// *************************************************************************** *
// *                                                                           *
// * Description:         CANDB File                                           *
// * Generated at:        2023-04-23 21:52                                     *
// * System:              SDB22400                                             *
// * Variant:             KX11_A2_ADCU2_VCU2_PCM                               *
// * Network:             ChassisCAN1                                          *
// *                                                                           *
// *************************************************************************** *
VERSION "ChassisCAN1"

NS_ :

BS_ :

BU_ :  ASDM BBM ECM ETC PSCM1 SAS TCM VDDM

BO_ 147 AsdmChas1Fr01 : 8 ASDM
 SG_ AsyADL3FuncCtrlSts_UB : 32|1@0+ (1,0) [0|1] "" Vector__XXX
 SG_ AsyADL3FuncCtrlStsADMod : 27|2@0+ (1,0) [0|3] "" Vector__XXX
 SG_ AsyADL3FuncCtrlStsChks : 23|8@0+ (1.0,0.0) [0.0|255.0] "Unitless" Vector__XXX
 SG_ AsyADL3FuncCtrlStsCntr : 31|4@0+ (1.0,0.0) [0.0|15.0] "Unitless" Vector__XXX
 SG_ AsyADL3FuncCtrlStsCtrlSts : 33|1@0+ (1,0) [0|1] "" Vector__XXX
 SG_ AsyADL3FuncCtrlStsDegraded : 39|4@0+ (1.0,0.0) [0.0|15.0] "Unitless" Vector__XXX
 SG_ AsyADL3FuncCtrlStsQf : 25|2@0+ (1,0) [0|3] "" Vector__XXX
 SG_ AsyADL3FuncCtrlStsSts : 35|2@0+ (1,0) [0|3] "" Vector__XXX
 SG_ AsyADModeReq_UB : 48|1@0+ (1,0) [0|1] "" BBM
 SG_ AsyADModeReqADActiveReq : 51|2@0+ (1,0) [0|3] "" BBM
 SG_ AsyADModeReqADDeactiveReq : 49|1@0+ (1,0) [0|1] "" BBM
 SG_ AsyADModeReqChks : 47|8@0+ (1.0,0.0) [0.0|255.0] "Unitless" BBM
 SG_ AsyADModeReqCntr : 55|4@0+ (1.0,0.0) [0.0|15.0] "Unitless" BBM
 SG_ PASFuncActive : 15|1@0+ (1,0) [0|1] "" ECM
 SG_ PASFuncActive_UB : 14|1@0+ (1,0) [0|1] "" ECM
 SG_ RctaBrkReqQM : 13|1@0+ (1,0) [0|1] "" ECM
 SG_ RctaBrkReqQM_UB : 12|1@0+ (1,0) [0|1] "" ECM
 SG_ RcwmBrkReqQM : 11|1@0+ (1,0) [0|1] "" Vector__XXX
 SG_ RcwmBrkReqQM_UB : 10|1@0+ (1,0) [0|1] "" Vector__XXX

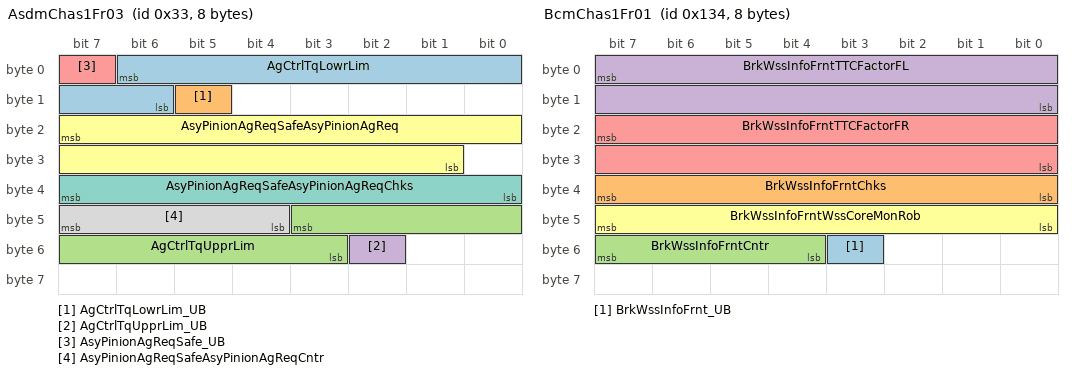
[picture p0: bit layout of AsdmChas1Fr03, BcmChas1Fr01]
BO_ 51 AsdmChas1Fr03 : 8 ASDM
 SG_ AgCtrlTqLowrLim : 6|9@0+ (0.125,-30.0) [-30.0|30.0] "Nm" PSCM1
 SG_ AgCtrlTqLowrLim_UB : 13|1@0+ (1,0) [0|1] "" PSCM1
 SG_ AgCtrlTqUpprLim : 43|9@0+ (0.125,-30.0) [-30.0|30.0] "Nm" PSCM1
 SG_ AgCtrlTqUpprLim_UB : 50|1@0+ (1,0) [0|1] "" PSCM1
 SG_ AsyPinionAgReqSafe_UB : 7|1@0+ (1,0) [0|1] "" PSCM1
 SG_ AsyPinionAgReqSafeAsyPinionAgReq : 23|15@0+ (0.0009765625,-14.5) [-14.5|17.4990234375] "rad" PSCM1
 SG_ AsyPinionAgReqSafeAsyPinionAgReqChks : 39|8@0+ (1.0,0.0) [0.0|255.0] "Unitless" PSCM1
 SG_ AsyPinionAgReqSafeAsyPinionAgReqCntr : 47|4@0+ (1.0,0.0) [0.0|15.0] "Unitless" PSCM1

BO_ 1321 AsdmChas1NMFr : 8 ASDM
 SG_ PNC16_ASDM : 16|1@0+ (1,0) [0|0] "" VDDM
 SG_ PNC17_ASDM : 17|1@0+ (1,0) [0|0] "" VDDM
 SG_ PNC18_ASDM : 18|1@0+ (1,0) [0|0] "" VDDM
 SG_ PNC19_ASDM : 19|1@0+ (1,0) [0|0] "" VDDM
 SG_ PNC20_ASDM : 20|1@0+ (1,0) [0|0] "" VDDM
 SG_ PNC21_ASDM : 21|1@0+ (1,0) [0|0] "" VDDM
 SG_ PNC22_ASDM : 22|1@0+ (1,0) [0|0] "" VDDM
 SG_ PNC23_ASDM : 23|1@0+ (1,0) [0|0] "" VDDM
 SG_ PNC24_ASDM : 24|1@0+ (1,0) [0|0] "" VDDM
 SG_ PNC25_ASDM : 25|1@0+ (1,0) [0|0] "" VDDM
 SG_ PNC26_ASDM : 26|1@0+ (1,0) [0|0] "" VDDM
 SG_ PNC27_ASDM : 27|1@0+ (1,0) [0|0] "" VDDM
 SG_ PNC28_ASDM : 28|1@0+ (1,0) [0|0] "" VDDM
 SG_ PNC29_ASDM : 29|1@0+ (1,0) [0|0] "" VDDM
 SG_ PNC30_ASDM : 30|1@0+ (1,0) [0|0] "" VDDM
 SG_ PNC31_ASDM : 31|1@0+ (1,0) [0|0] "" VDDM
 SG_ PNC32_ASDM : 32|1@0+ (1,0) [0|0] "" VDDM
 SG_ PNC33_ASDM : 33|1@0+ (1,0) [0|0] "" VDDM
 SG_ PNC34_ASDM : 34|1@0+ (1,0) [0|0] "" VDDM
 SG_ PNC35_ASDM : 35|1@0+ (1,0) [0|0] "" VDDM
 SG_ PNC36_ASDM : 36|1@0+ (1,0) [0|0] "" VDDM
 SG_ PNC37_ASDM : 37|1@0+ (1,0) [0|0] "" VDDM
 SG_ PNC38_ASDM : 38|1@0+ (1,0) [0|0] "" VDDM
 SG_ PNC39_ASDM : 39|1@0+ (1,0) [0|0] "" VDDM
 SG_ PNC40_ASDM : 40|1@0+ (1,0) [0|0] "" VDDM
 SG_ PNC41_ASDM : 41|1@0+ (1,0) [0|0] "" VDDM
 SG_ PNC42_ASDM : 42|1@0+ (1,0) [0|0] "" VDDM
 SG_ NM_PNI_ASDM : 14|1@0+ (1,0) [0|0] "" VDDM
 SG_ NM_AW_ASDM : 12|1@0+ (1,0) [0|0] "" VDDM
 SG_ NM_CS_ASDM : 11|1@0+ (1,0) [0|0] "" VDDM
 SG_ NM_RMR_ASDM : 8|1@0+ (1,0) [0|0] "" VDDM
 SG_ NM_NodeID_ASDM : 7|8@0+ (1,0) [0|0] "" VDDM

BO_ 308 BcmChas1Fr01 : 8 BBM
 SG_ BrkWssInfoFrnt_UB : 51|1@0+ (1,0) [0|1] "" Vector__XXX
 SG_ BrkWssInfoFrntChks : 39|8@0+ (1.0,0.0) [0.0|255.0] "Unitless" Vector__XXX
 SG_ BrkWssInfoFrntCntr : 55|4@0+ (1.0,0.0) [0.0|15.0] "Unitless" Vector__XXX
 SG_ BrkWssInfoFrntTTCFactorFL : 7|16@0+ (0.00000916,0.7) [0.7|1.3003006] "Unitless" Vector__XXX
 SG_ BrkWssInfoFrntTTCFactorFR : 23|16@0+ (0.00000916,0.7) [0.7|1.3003006] "Unitless" Vector__XXX
 SG_ BrkWssInfoFrntWssCoreMonRob : 47|8@0+ (1.0,0.0) [0.0|255.0] "Unitless" Vector__XXX

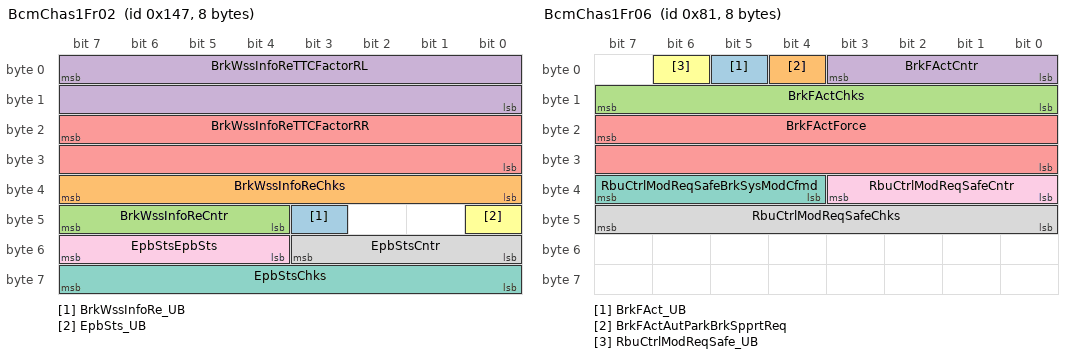
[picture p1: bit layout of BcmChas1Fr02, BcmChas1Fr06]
BO_ 327 BcmChas1Fr02 : 8 BBM
 SG_ BrkWssInfoRe_UB : 43|1@0+ (1,0) [0|1] "" Vector__XXX
 SG_ BrkWssInfoReChks : 39|8@0+ (1.0,0.0) [0.0|255.0] "Unitless" Vector__XXX
 SG_ BrkWssInfoReCntr : 47|4@0+ (1.0,0.0) [0.0|15.0] "Unitless" Vector__XXX
 SG_ BrkWssInfoReTTCFactorRL : 7|16@0+ (0.00000916,0.7) [0.7|1.3003006] "Unitless" Vector__XXX
 SG_ BrkWssInfoReTTCFactorRR : 23|16@0+ (0.00000916,0.7) [0.7|1.3003006] "Unitless" Vector__XXX
 SG_ EpbSts_UB : 40|1@0+ (1,0) [0|1] "" Vector__XXX
 SG_ EpbStsChks : 63|8@0+ (1.0,0.0) [0.0|255.0] "Unitless" Vector__XXX
 SG_ EpbStsCntr : 51|4@0+ (1.0,0.0) [0.0|15.0] "Unitless" Vector__XXX
 SG_ EpbStsEpbSts : 55|4@0+ (1,0) [0|15] "" Vector__XXX

BO_ 84 BcmChas1Fr03 : 8 BBM
 SG_ SBMHealthChkCmd : 63|8@0+ (1.0,0.0) [0.0|255.0] "Unitless" Vector__XXX
 SG_ SBMHealthChkCmd_UB : 27|1@0+ (1,0) [0|1] "" Vector__XXX

BO_ 129 BcmChas1Fr06 : 8 BBM
 SG_ BrkFAct_UB : 5|1@0+ (1,0) [0|1] "" Vector__XXX
 SG_ BrkFActAutParkBrkSpprtReq : 4|1@0+ (1,0) [0|1] "" Vector__XXX
 SG_ BrkFActChks : 15|8@0+ (1.0,0.0) [0.0|255.0] "Unitless" Vector__XXX
 SG_ BrkFActCntr : 3|4@0+ (1.0,0.0) [0.0|15.0] "Unitless" Vector__XXX
 SG_ BrkFActForce : 23|16@0+ (1.0,0.0) [0.0|50000.0] "N" Vector__XXX
 SG_ RbuCtrlModReqSafe_UB : 6|1@0+ (1,0) [0|1] "" Vector__XXX
 SG_ RbuCtrlModReqSafeBrkSysModCfmd : 39|4@0+ (1,0) [0|15] "" Vector__XXX
 SG_ RbuCtrlModReqSafeChks : 47|8@0+ (1.0,0.0) [0.0|255.0] "Unitless" Vector__XXX
 SG_ RbuCtrlModReqSafeCntr : 35|4@0+ (1.0,0.0) [0.0|15.0] "Unitless" Vector__XXX

BO_ 265 BcmChas1Fr07 : 8 BBM
 SG_ EpbAvlPrim_UB : 57|1@0+ (1,0) [0|1] "" Vector__XXX
 SG_ EpbAvlPrimApplyFunctionalitiesAvailable : 27|1@0+ (1,0) [0|1] "" Vector__XXX
 SG_ EpbAvlPrimChks : 23|8@0+ (1.0,0.0) [0.0|255.0] "Unitless" Vector__XXX
 SG_ EpbAvlPrimCntr : 31|4@0+ (1.0,0.0) [0.0|15.0] "Unitless" Vector__XXX
 SG_ EpbAvlPrimDriveAwayIntention : 26|1@0+ (1,0) [0|1] "" Vector__XXX
 SG_ EpbAvlPrimHostAvailabilityFull : 25|1@0+ (1,0) [0|1] "" Vector__XXX
 SG_ EpbAvlPrimHostAvailabilityRelOnly : 24|1@0+ (1,0) [0|1] "" Vector__XXX
 SG_ EpbAvlPrimPrimarySystemAvailable : 39|1@0+ (1,0) [0|1] "" Vector__XXX
 SG_ EpbAvlPrimReserved1 : 38|1@0+ (1,0) [0|1] "" Vector__XXX
 SG_ EpbAvlPrimReserved2 : 37|1@0+ (1,0) [0|1] "" Vector__XXX
 SG_ EpbAvlPrimReserved3 : 36|1@0+ (1,0) [0|1] "" Vector__XXX
 SG_ EpbAvlPrimReserved4 : 35|1@0+ (1,0) [0|1] "" Vector__XXX
 SG_ EpbAvlPrimRollerTestBench : 34|1@0+ (1,0) [0|1] "" Vector__XXX
 SG_ PrimBrkSysSt_UB : 56|1@0+ (1,0) [0|1] "" Vector__XXX
 SG_ PrimBrkSysStBrkSysSt : 7|4@0+ (1,0) [0|15] "" Vector__XXX
 SG_ PrimBrkSysStChks : 15|8@0+ (1.0,0.0) [0.0|255.0] "Unitless" Vector__XXX
 SG_ PrimBrkSysStCntr : 3|4@0+ (1.0,0.0) [0.0|15.0] "Unitless" Vector__XXX

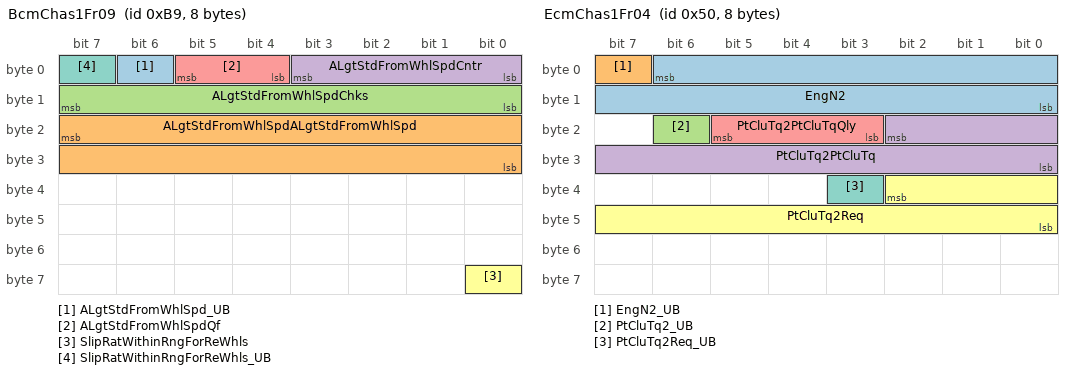
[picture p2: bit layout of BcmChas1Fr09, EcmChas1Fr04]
BO_ 185 BcmChas1Fr09 : 8 BBM
 SG_ ALgtStdFromWhlSpd_UB : 6|1@0+ (1,0) [0|1] "" Vector__XXX
 SG_ ALgtStdFromWhlSpdALgtStdFromWhlSpd : 23|16@0- (0.0009765625,0.0) [-18.0|18.0] "m/s^2" Vector__XXX
 SG_ ALgtStdFromWhlSpdChks : 15|8@0+ (1.0,0.0) [0.0|255.0] "Unitless" Vector__XXX
 SG_ ALgtStdFromWhlSpdCntr : 3|4@0+ (1.0,0.0) [0.0|15.0] "Unitless" Vector__XXX
 SG_ ALgtStdFromWhlSpdQf : 5|2@0+ (1,0) [0|3] "" Vector__XXX
 SG_ SlipRatWithinRngForReWhls : 56|1@0+ (1,0) [0|1] "" Vector__XXX
 SG_ SlipRatWithinRngForReWhls_UB : 7|1@0+ (1,0) [0|1] "" Vector__XXX

BO_ 1334 BcmChas1NMFr : 8 BBM
 SG_ PNC16_BBM : 16|1@0+ (1,0) [0|0] "" Vector__XXX
 SG_ PNC17_BBM : 17|1@0+ (1,0) [0|0] "" Vector__XXX
 SG_ PNC18_BBM : 18|1@0+ (1,0) [0|0] "" Vector__XXX
 SG_ PNC19_BBM : 19|1@0+ (1,0) [0|0] "" Vector__XXX
 SG_ PNC20_BBM : 20|1@0+ (1,0) [0|0] "" Vector__XXX
 SG_ PNC21_BBM : 21|1@0+ (1,0) [0|0] "" Vector__XXX
 SG_ PNC22_BBM : 22|1@0+ (1,0) [0|0] "" Vector__XXX
 SG_ PNC23_BBM : 23|1@0+ (1,0) [0|0] "" Vector__XXX
 SG_ PNC24_BBM : 24|1@0+ (1,0) [0|0] "" Vector__XXX
 SG_ PNC25_BBM : 25|1@0+ (1,0) [0|0] "" Vector__XXX
 SG_ PNC26_BBM : 26|1@0+ (1,0) [0|0] "" Vector__XXX
 SG_ PNC27_BBM : 27|1@0+ (1,0) [0|0] "" Vector__XXX
 SG_ PNC28_BBM : 28|1@0+ (1,0) [0|0] "" Vector__XXX
 SG_ PNC29_BBM : 29|1@0+ (1,0) [0|0] "" Vector__XXX
 SG_ PNC30_BBM : 30|1@0+ (1,0) [0|0] "" Vector__XXX
 SG_ PNC31_BBM : 31|1@0+ (1,0) [0|0] "" Vector__XXX
 SG_ PNC32_BBM : 32|1@0+ (1,0) [0|0] "" Vector__XXX
 SG_ PNC33_BBM : 33|1@0+ (1,0) [0|0] "" Vector__XXX
 SG_ PNC34_BBM : 34|1@0+ (1,0) [0|0] "" Vector__XXX
 SG_ PNC35_BBM : 35|1@0+ (1,0) [0|0] "" Vector__XXX
 SG_ PNC36_BBM : 36|1@0+ (1,0) [0|0] "" Vector__XXX
 SG_ PNC37_BBM : 37|1@0+ (1,0) [0|0] "" Vector__XXX
 SG_ PNC38_BBM : 38|1@0+ (1,0) [0|0] "" Vector__XXX
 SG_ PNC39_BBM : 39|1@0+ (1,0) [0|0] "" Vector__XXX
 SG_ PNC40_BBM : 40|1@0+ (1,0) [0|0] "" Vector__XXX
 SG_ PNC41_BBM : 41|1@0+ (1,0) [0|0] "" Vector__XXX
 SG_ PNC42_BBM : 42|1@0+ (1,0) [0|0] "" Vector__XXX
 SG_ NM_PNI_BBM : 14|1@0+ (1,0) [0|0] "" Vector__XXX
 SG_ NM_AW_BBM : 12|1@0+ (1,0) [0|0] "" Vector__XXX
 SG_ NM_CS_BBM : 11|1@0+ (1,0) [0|0] "" Vector__XXX
 SG_ NM_RMR_BBM : 8|1@0+ (1,0) [0|0] "" Vector__XXX
 SG_ NM_NodeID_BBM : 7|8@0+ (1,0) [0|0] "" Vector__XXX

BO_ 134 EcmChas1BsgFr40 : 8 ECM
 SG_ DrvgCyc : 39|1@0+ (1,0) [0|1] "" Vector__XXX
 SG_ DrvgCyc_UB : 38|1@0+ (1,0) [0|1] "" Vector__XXX

BO_ 544 EcmChas1BsgFr41 : 8 ECM
 SG_ AccrPedlRat_UB : 7|1@0+ (1,0) [0|1] "" Vector__XXX
 SG_ AccrPedlRatAccrPedlRat : 6|15@0+ (0.00390625,0.0) [0.0|100.0] "%" Vector__XXX
 SG_ AccrPedlRatChks : 23|8@0+ (1.0,0.0) [0.0|255.0] "Unitless" Vector__XXX
 SG_ AccrPedlRatCntr : 31|4@0+ (1.0,0.0) [0.0|15.0] "Unitless" Vector__XXX

BO_ 80 EcmChas1Fr04 : 8 ECM
 SG_ EngN2 : 6|15@0+ (0.5,0.0) [0.0|16383.5] "rpm" TCM,VDDM
 SG_ EngN2_UB : 7|1@0+ (1,0) [0|1] "" TCM,VDDM
 SG_ PtCluTq2_UB : 22|1@0+ (1,0) [0|1] "" TCM
 SG_ PtCluTq2PtCluTq : 18|11@0+ (1.0,-1024.0) [-1024.0|1023.0] "NewtonMeter" TCM
 SG_ PtCluTq2PtCluTqQly : 21|3@0+ (1,0) [0|7] "" TCM
 SG_ PtCluTq2Req : 34|11@0+ (1.0,-1024.0) [-1024.0|1023.0] "NewtonMeter" TCM
 SG_ PtCluTq2Req_UB : 35|1@0+ (1,0) [0|1] "" TCM

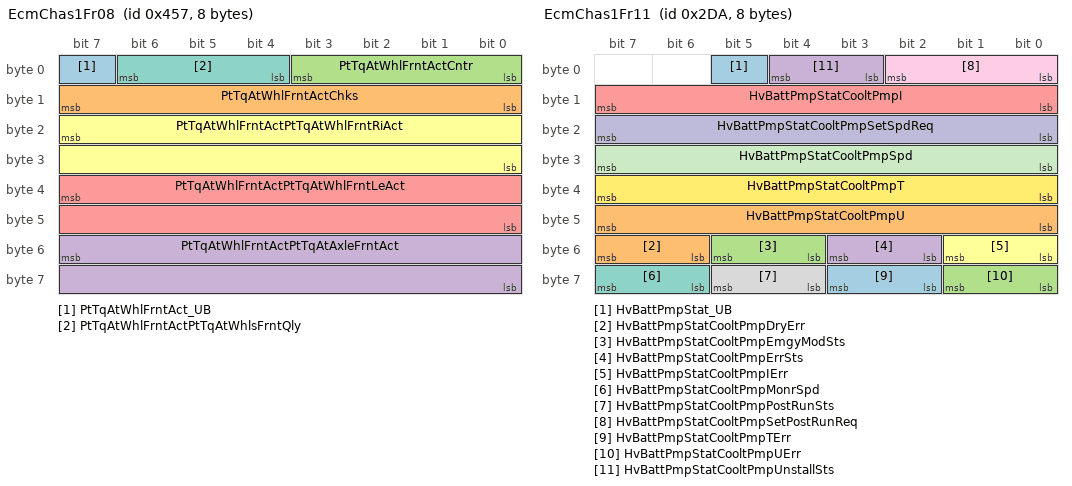
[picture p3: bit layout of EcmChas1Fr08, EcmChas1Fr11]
BO_ 1111 EcmChas1Fr08 : 8 ECM
 SG_ PtTqAtWhlFrntAct_UB : 7|1@0+ (1,0) [0|1] "" PSCM1
 SG_ PtTqAtWhlFrntActChks : 15|8@0+ (1.0,0.0) [0.0|255.0] "Unitless" PSCM1
 SG_ PtTqAtWhlFrntActCntr : 3|4@0+ (1.0,0.0) [0.0|15.0] "Unitless" PSCM1
 SG_ PtTqAtWhlFrntActPtTqAtAxleFrntAct : 55|16@0- (1.0,0.0) [-20000.0|20000.0] "NewtonMeter" PSCM1
 SG_ PtTqAtWhlFrntActPtTqAtWhlFrntLeAct : 39|16@0- (1.0,0.0) [-20000.0|20000.0] "NewtonMeter" PSCM1
 SG_ PtTqAtWhlFrntActPtTqAtWhlFrntRiAct : 23|16@0- (1.0,0.0) [-20000.0|20000.0] "NewtonMeter" PSCM1
 SG_ PtTqAtWhlFrntActPtTqAtWhlsFrntQly : 6|3@0+ (1,0) [0|7] "" PSCM1

BO_ 708 EcmChas1Fr09 : 8 ECM
 SG_ PtVehSpdMax_UB : 4|1@0+ (1,0) [0|1] "" VDDM
 SG_ PtVehSpdMaxChks : 15|8@0+ (1.0,0.0) [0.0|255.0] "Unitless" VDDM
 SG_ PtVehSpdMaxCntr : 3|4@0+ (1.0,0.0) [0.0|15.0] "Unitless" VDDM
 SG_ PtVehSpdMaxReq : 23|8@0+ (0.4,0.0) [0.0|102.0] "m/s" VDDM

BO_ 730 EcmChas1Fr11 : 8 ECM
 SG_ HvBattPmpStat_UB : 5|1@0+ (1,0) [0|1] "" VDDM
 SG_ HvBattPmpStatCooltPmpDryErr : 55|2@0+ (1,0) [0|3] "" VDDM
 SG_ HvBattPmpStatCooltPmpEmgyModSts : 53|2@0+ (1,0) [0|3] "" VDDM
 SG_ HvBattPmpStatCooltPmpErrSts : 51|2@0+ (1,0) [0|3] "" VDDM
 SG_ HvBattPmpStatCooltPmpI : 15|8@0+ (0.2,0.0) [0.0|50.800000000000004] "A" VDDM
 SG_ HvBattPmpStatCooltPmpIErr : 49|2@0+ (1,0) [0|3] "" VDDM
 SG_ HvBattPmpStatCooltPmpMonrSpd : 63|2@0+ (1,0) [0|3] "" VDDM
 SG_ HvBattPmpStatCooltPmpPostRunSts : 61|2@0+ (1,0) [0|3] "" VDDM
 SG_ HvBattPmpStatCooltPmpSetPostRunReq : 2|3@0+ (1,0) [0|7] "" VDDM
 SG_ HvBattPmpStatCooltPmpSetSpdReq : 23|8@0+ (1.0,0.0) [0.0|254.0] "Unitless" VDDM
 SG_ HvBattPmpStatCooltPmpSpd : 31|8@0+ (1.0,0.0) [0.0|254.0] "Unitless" VDDM
 SG_ HvBattPmpStatCooltPmpT : 39|8@0+ (1.0,-50.0) [-50.0|200.0] "degC" VDDM
 SG_ HvBattPmpStatCooltPmpTErr : 59|2@0+ (1,0) [0|3] "" VDDM
 SG_ HvBattPmpStatCooltPmpU : 47|8@0+ (0.1,0.0) [0.0|25.0] "Volt" VDDM
 SG_ HvBattPmpStatCooltPmpUErr : 57|2@0+ (1,0) [0|3] "" VDDM
 SG_ HvBattPmpStatCooltPmpUnstallSts : 4|2@0+ (1,0) [0|3] "" VDDM

BO_ 859 EcmChas1Fr12 : 8 ECM
 SG_ DispElecPwr_UB : 51|1@0+ (1,0) [0|1] "" VDDM
 SG_ DispElecPwrAbs : 49|10@0+ (0.5,0.0) [0.0|511.0] "kW" VDDM
 SG_ DispElecPwrSts : 50|1@0+ (1,0) [0|1] "" VDDM

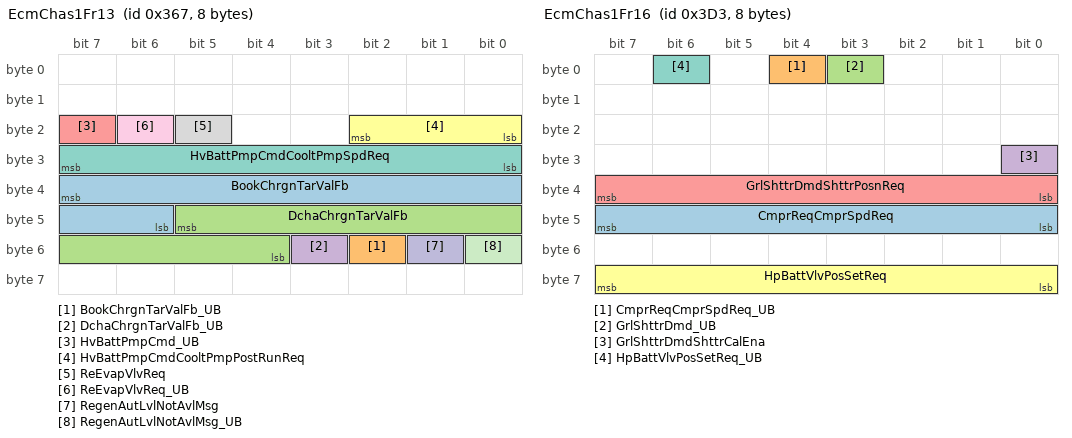
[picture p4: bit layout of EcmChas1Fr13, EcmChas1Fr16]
BO_ 871 EcmChas1Fr13 : 8 ECM
 SG_ BookChrgnTarValFb : 39|10@0+ (0.1,0.0) [0.0|100.0] "%" VDDM
 SG_ BookChrgnTarValFb_UB : 50|1@0+ (1,0) [0|1] "" VDDM
 SG_ DchaChrgnTarValFb : 45|10@0+ (0.1,0.0) [0.0|100.0] "%" VDDM
 SG_ DchaChrgnTarValFb_UB : 51|1@0+ (1,0) [0|1] "" VDDM
 SG_ HvBattPmpCmd_UB : 23|1@0+ (1,0) [0|1] "" Vector__XXX
 SG_ HvBattPmpCmdCooltPmpPostRunReq : 18|3@0+ (1,0) [0|7] "" Vector__XXX
 SG_ HvBattPmpCmdCooltPmpSpdReq : 31|8@0+ (1.0,0.0) [0.0|254.0] "Unitless" Vector__XXX
 SG_ ReEvapVlvReq : 21|1@0+ (1,0) [0|1] "" VDDM
 SG_ ReEvapVlvReq_UB : 22|1@0+ (1,0) [0|1] "" VDDM
 SG_ RegenAutLvlNotAvlMsg : 49|1@0+ (1,0) [0|1] "" VDDM
 SG_ RegenAutLvlNotAvlMsg_UB : 48|1@0+ (1,0) [0|1] "" VDDM

BO_ 979 EcmChas1Fr16 : 8 ECM
 SG_ CmprReqCmprSpdReq : 47|8@0+ (50.0,0.0) [0.0|12700.0] "rpm" VDDM
 SG_ CmprReqCmprSpdReq_UB : 4|1@0+ (1,0) [0|1] "" VDDM
 SG_ GrlShttrDmd_UB : 3|1@0+ (1,0) [0|1] "" Vector__XXX
 SG_ GrlShttrDmdShttrCalEna : 24|1@0+ (1,0) [0|1] "" Vector__XXX
 SG_ GrlShttrDmdShttrPosnReq : 39|8@0+ (1.0,0.0) [0.0|255.0] "Unitless" Vector__XXX
 SG_ HpBattVlvPosSetReq : 63|8@0+ (1.0,0.0) [0.0|100.0] "%" Vector__XXX
 SG_ HpBattVlvPosSetReq_UB : 6|1@0+ (1,0) [0|1] "" Vector__XXX

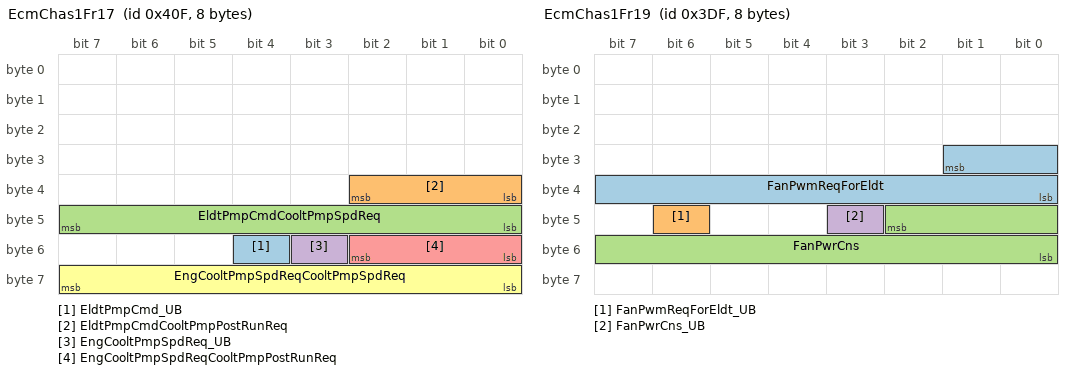
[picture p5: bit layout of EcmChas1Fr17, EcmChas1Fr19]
BO_ 1039 EcmChas1Fr17 : 8 ECM
 SG_ EldtPmpCmd_UB : 52|1@0+ (1,0) [0|1] "" Vector__XXX
 SG_ EldtPmpCmdCooltPmpPostRunReq : 34|3@0+ (1,0) [0|7] "" Vector__XXX
 SG_ EldtPmpCmdCooltPmpSpdReq : 47|8@0+ (1.0,0.0) [0.0|254.0] "Unitless" Vector__XXX
 SG_ EngCooltPmpSpdReq_UB : 51|1@0+ (1,0) [0|1] "" Vector__XXX
 SG_ EngCooltPmpSpdReqCooltPmpPostRunReq : 50|3@0+ (1,0) [0|7] "" Vector__XXX
 SG_ EngCooltPmpSpdReqCooltPmpSpdReq : 63|8@0+ (1.0,0.0) [0.0|254.0] "Unitless" Vector__XXX

BO_ 563 EcmChas1Fr18 : 8 ECM
 SG_ CmprRunTime : 7|32@0+ (1.0,0.0) [0.0|4294967295.0] "Unitless" VDDM
 SG_ CmprRunTime_UB : 38|1@0+ (1,0) [0|1] "" VDDM

BO_ 991 EcmChas1Fr19 : 8 ECM
 SG_ FanPwmReqForEldt : 25|10@0+ (0.1,0.0) [0.0|100.0] "%" VDDM
 SG_ FanPwmReqForEldt_UB : 46|1@0+ (1,0) [0|1] "" VDDM
 SG_ FanPwrCns : 42|11@0+ (1.0,0.0) [0.0|2047.0] "W" VDDM
 SG_ FanPwrCns_UB : 43|1@0+ (1,0) [0|1] "" VDDM

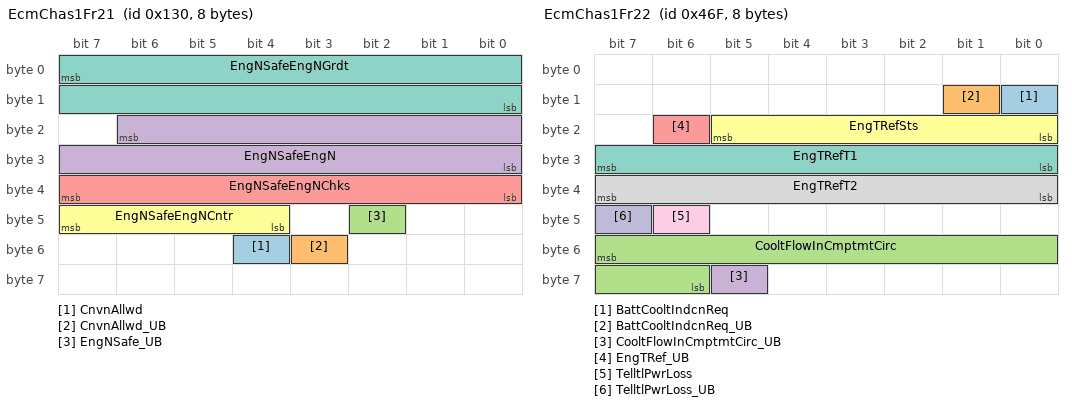
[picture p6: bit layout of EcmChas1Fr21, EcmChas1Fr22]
BO_ 304 EcmChas1Fr21 : 8 ECM
 SG_ CnvnAllwd : 52|1@0+ (1,0) [0|1] "" VDDM
 SG_ CnvnAllwd_UB : 51|1@0+ (1,0) [0|1] "" VDDM
 SG_ EngNSafe_UB : 42|1@0+ (1,0) [0|1] "" SAS
 SG_ EngNSafeEngN : 22|15@0+ (0.5,0.0) [0.0|16383.5] "rpm" SAS
 SG_ EngNSafeEngNChks : 39|8@0+ (1.0,0.0) [0.0|255.0] "Unitless" SAS
 SG_ EngNSafeEngNCntr : 47|4@0+ (1.0,0.0) [0.0|15.0] "Unitless" SAS
 SG_ EngNSafeEngNGrdt : 7|16@0- (1.0,0.0) [-30000.0|32767.0] "RpmPerSec" SAS

BO_ 1135 EcmChas1Fr22 : 8 ECM
 SG_ BattCooltIndcnReq : 8|1@0+ (1,0) [0|1] "" VDDM
 SG_ BattCooltIndcnReq_UB : 9|1@0+ (1,0) [0|1] "" VDDM
 SG_ CooltFlowInCmptmtCirc : 55|10@0+ (0.05,0.0) [0.0|51.150000000000006] "L / min" VDDM
 SG_ CooltFlowInCmptmtCirc_UB : 61|1@0+ (1,0) [0|1] "" VDDM
 SG_ EngTRef_UB : 22|1@0+ (1,0) [0|1] "" TCM
 SG_ EngTRefSts : 21|6@0+ (1.0,0.0) [0.0|63.0] "Unitless" TCM
 SG_ EngTRefT1 : 31|8@0+ (1.0,-50.0) [-50.0|200.0] "degC" TCM
 SG_ EngTRefT2 : 39|8@0+ (1.0,-50.0) [-50.0|200.0] "degC" TCM
 SG_ TelltlPwrLoss : 46|1@0+ (1,0) [0|1] "" VDDM
 SG_ TelltlPwrLoss_UB : 47|1@0+ (1,0) [0|1] "" VDDM

BO_ 576 EcmChas1Fr23 : 8 ECM
 SG_ HvBattPmpPwrCns : 3|12@0+ (1.0,0.0) [0.0|4095.0] "W" VDDM
 SG_ HvBattPmpPwrCns_UB : 7|1@0+ (1,0) [0|1] "" VDDM
 SG_ PostHeatgRunTiEstimd : 23|16@0+ (1.0,0.0) [0.0|65535.0] "Unitless" VDDM
 SG_ PostHeatgRunTiEstimd_UB : 6|1@0+ (1,0) [0|1] "" VDDM

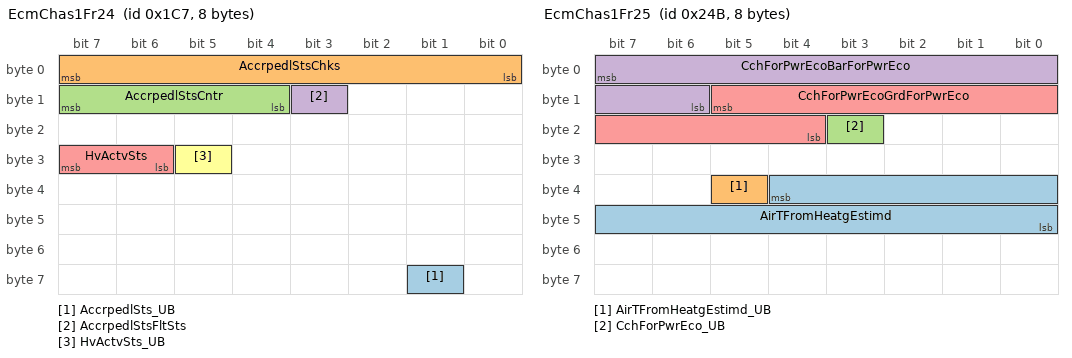
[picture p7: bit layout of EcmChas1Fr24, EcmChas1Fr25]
BO_ 455 EcmChas1Fr24 : 8 ECM
 SG_ AccrpedlSts_UB : 57|1@0+ (1,0) [0|1] "" VDDM
 SG_ AccrpedlStsChks : 7|8@0+ (1.0,0.0) [0.0|255.0] "Unitless" VDDM
 SG_ AccrpedlStsCntr : 15|4@0+ (1.0,0.0) [0.0|15.0] "Unitless" VDDM
 SG_ AccrpedlStsFltSts : 11|1@0+ (1,0) [0|1] "" VDDM
 SG_ HvActvSts : 31|2@0+ (1,0) [0|3] "" VDDM
 SG_ HvActvSts_UB : 29|1@0+ (1,0) [0|1] "" VDDM

BO_ 587 EcmChas1Fr25 : 8 ECM
 SG_ AirTFromHeatgEstimd : 36|13@0- (0.1,0.0) [-256.0|255.9] "degC" VDDM
 SG_ AirTFromHeatgEstimd_UB : 37|1@0+ (1,0) [0|1] "" VDDM
 SG_ CchForPwrEco_UB : 19|1@0+ (1,0) [0|1] "" VDDM
 SG_ CchForPwrEcoBarForPwrEco : 7|10@0+ (0.1,0.0) [0.0|102.30000000000001] "%" VDDM
 SG_ CchForPwrEcoGrdForPwrEco : 13|10@0+ (0.1,0.0) [0.0|102.30000000000001] "Unitless" VDDM

BO_ 543 EcmChas1Fr26 : 8 ECM
 SG_ AcCmprVlvICns : 39|8@0+ (0.05,0.0) [0.0|12.600000000000001] "A" VDDM
 SG_ AcCmprVlvICns_UB : 61|1@0+ (1,0) [0|1] "" VDDM
 SG_ GearMov : 23|2@0+ (1,0) [0|3] "" VDDM
 SG_ GearMov_UB : 21|1@0+ (1,0) [0|1] "" VDDM

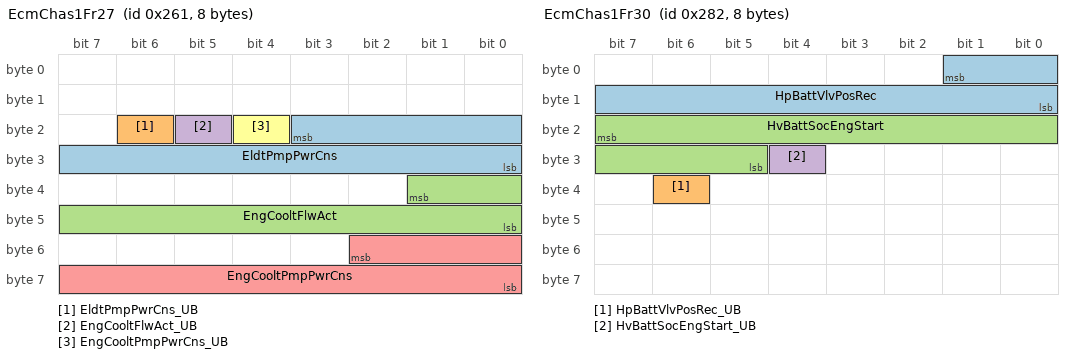
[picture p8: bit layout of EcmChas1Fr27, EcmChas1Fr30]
BO_ 609 EcmChas1Fr27 : 8 ECM
 SG_ EldtPmpPwrCns : 19|12@0+ (1.0,0.0) [0.0|4095.0] "W" VDDM
 SG_ EldtPmpPwrCns_UB : 22|1@0+ (1,0) [0|1] "" VDDM
 SG_ EngCooltFlwAct : 33|10@0+ (0.1,0.0) [0.0|102.30000000000001] "L / min" VDDM
 SG_ EngCooltFlwAct_UB : 21|1@0+ (1,0) [0|1] "" VDDM
 SG_ EngCooltPmpPwrCns : 50|11@0+ (1.0,0.0) [0.0|2047.0] "W" VDDM
 SG_ EngCooltPmpPwrCns_UB : 20|1@0+ (1,0) [0|1] "" VDDM

BO_ 632 EcmChas1Fr29 : 8 ECM
 SG_ ChrgnSpd : 38|11@0+ (1.0,0.0) [0.0|2047.0] "Km/h" VDDM
 SG_ ChrgnSpd_UB : 48|1@0+ (1,0) [0|1] "" VDDM

BO_ 642 EcmChas1Fr30 : 8 ECM
 SG_ HpBattVlvPosRec : 1|10@0+ (0.1,0.0) [0.0|100.0] "%" VDDM
 SG_ HpBattVlvPosRec_UB : 38|1@0+ (1,0) [0|1] "" VDDM
 SG_ HvBattSocEngStart : 23|11@0+ (0.05,0.0) [0.0|100.0] "%" VDDM
 SG_ HvBattSocEngStart_UB : 28|1@0+ (1,0) [0|1] "" VDDM

BO_ 131 EcmChas1Fr31 : 8 ECM
 SG_ EngSt1WdSts_UB : 23|1@0+ (1,0) [0|1] "" TCM,VDDM
 SG_ EngSt1WdStsChks : 7|8@0+ (1.0,0.0) [0.0|255.0] "Unitless" TCM,VDDM
 SG_ EngSt1WdStsCntr : 15|4@0+ (1.0,0.0) [0.0|15.0] "Unitless" TCM,VDDM
 SG_ EngSt1WdStsEngSt1WdSts : 11|4@0+ (1,0) [0|15] "" TCM,VDDM

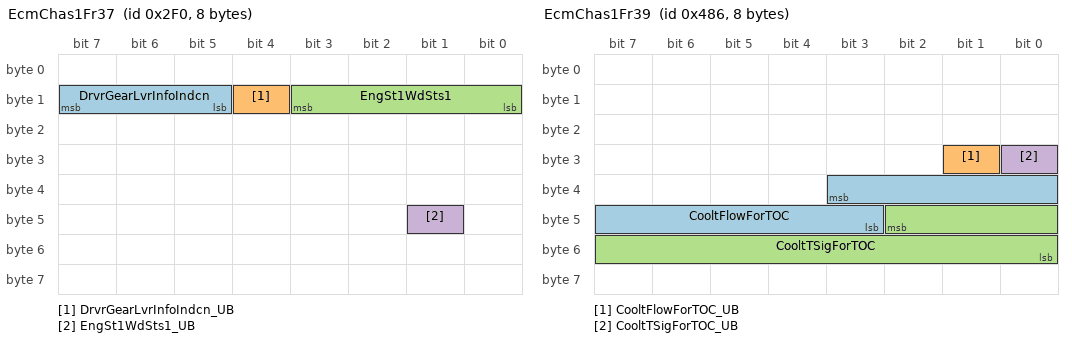
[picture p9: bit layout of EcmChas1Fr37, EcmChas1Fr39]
BO_ 752 EcmChas1Fr37 : 8 ECM
 SG_ DrvrGearLvrInfoIndcn : 15|3@0+ (1,0) [0|7] "" VDDM
 SG_ DrvrGearLvrInfoIndcn_UB : 12|1@0+ (1,0) [0|1] "" VDDM
 SG_ EngSt1WdSts1 : 11|4@0+ (1,0) [0|15] "" SAS
 SG_ EngSt1WdSts1_UB : 41|1@0+ (1,0) [0|1] "" SAS

BO_ 1157 EcmChas1Fr38 : 8 ECM
 SG_ AutoShowModPrpsnEna : 43|1@0+ (1,0) [0|1] "" VDDM
 SG_ AutoShowModPrpsnEna_UB : 42|1@0+ (1,0) [0|1] "" VDDM

BO_ 1158 EcmChas1Fr39 : 8 ECM
 SG_ CooltFlowForTOC : 35|9@0+ (0.1,0.0) [0.0|51.1] "L / min" TCM
 SG_ CooltFlowForTOC_UB : 25|1@0+ (1,0) [0|1] "" TCM
 SG_ CooltTSigForTOC : 42|11@0+ (0.1,-40.0) [-40.0|140.0] "degC" TCM
 SG_ CooltTSigForTOC_UB : 24|1@0+ (1,0) [0|1] "" TCM

BO_ 837 EcmChas1Fr42 : 8 ECM
 SG_ DstEstimdToEmptyForDrvgElecPredTyp2 : 46|10@0+ (1.0,0.0) [0.0|1023.0] "KiloMtr" VDDM
 SG_ DstEstimdToEmptyForDrvgElecPredTyp2_UB : 52|1@0+ (1,0) [0|1] "" VDDM

BO_ 913 EcmChas1Fr48 : 8 ECM
 SG_ DispIdlChrgPwr : 47|10@0+ (0.5,0.0) [0.0|511.0] "kW" VDDM
 SG_ DispIdlChrgPwr_UB : 32|1@0+ (1,0) [0|1] "" VDDM

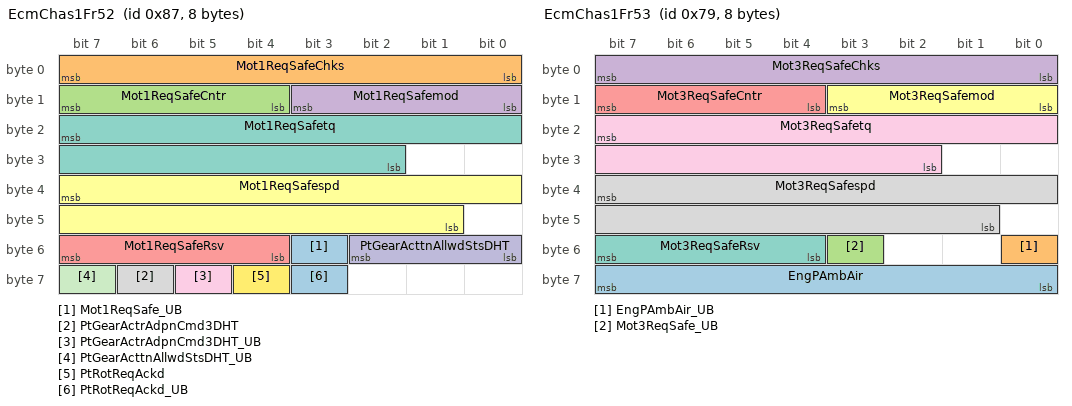
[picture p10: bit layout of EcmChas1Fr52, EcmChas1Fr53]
BO_ 135 EcmChas1Fr52 : 8 ECM
 SG_ Mot1ReqSafe_UB : 51|1@0+ (1,0) [0|1] "" TCM
 SG_ Mot1ReqSafeChks : 7|8@0+ (1.0,0.0) [0.0|255.0] "Unitless" TCM
 SG_ Mot1ReqSafeCntr : 15|4@0+ (1.0,0.0) [0.0|15.0] "Unitless" TCM
 SG_ Mot1ReqSafemod : 11|4@0+ (1,0) [0|15] "" TCM
 SG_ Mot1ReqSafeRsv : 55|4@0+ (1.0,0.0) [0.0|15.0] "Unitless" TCM
 SG_ Mot1ReqSafespd : 39|15@0- (1.0,0.0) [-16384.0|16383.0] "rpm" TCM
 SG_ Mot1ReqSafetq : 23|14@0+ (1.0,-8188.0) [-8188.0|8192.0] "NewtonMeter" TCM
 SG_ PtGearActrAdpnCmd3DHT : 62|1@0+ (1,0) [0|1] "" TCM
 SG_ PtGearActrAdpnCmd3DHT_UB : 61|1@0+ (1,0) [0|1] "" TCM
 SG_ PtGearActtnAllwdStsDHT : 50|3@0+ (1.0,0.0) [0.0|7.0] "Unitless" TCM
 SG_ PtGearActtnAllwdStsDHT_UB : 63|1@0+ (1,0) [0|1] "" TCM
 SG_ PtRotReqAckd : 60|1@0+ (1,0) [0|1] "" TCM
 SG_ PtRotReqAckd_UB : 59|1@0+ (1,0) [0|1] "" TCM

BO_ 121 EcmChas1Fr53 : 8 ECM
 SG_ EngPAmbAir : 63|8@0+ (5.0,0.0) [0.0|1275.0] "hPa" TCM
 SG_ EngPAmbAir_UB : 48|1@0+ (1,0) [0|1] "" TCM
 SG_ Mot3ReqSafe_UB : 51|1@0+ (1,0) [0|1] "" TCM
 SG_ Mot3ReqSafeChks : 7|8@0+ (1.0,0.0) [0.0|255.0] "Unitless" TCM
 SG_ Mot3ReqSafeCntr : 15|4@0+ (1.0,0.0) [0.0|15.0] "Unitless" TCM
 SG_ Mot3ReqSafemod : 11|4@0+ (1,0) [0|15] "" TCM
 SG_ Mot3ReqSafeRsv : 55|4@0+ (1.0,0.0) [0.0|15.0] "Unitless" TCM
 SG_ Mot3ReqSafespd : 39|15@0- (1.0,0.0) [-16384.0|16383.0] "rpm" TCM
 SG_ Mot3ReqSafetq : 23|14@0+ (1.0,-8188.0) [-8188.0|8192.0] "NewtonMeter" TCM

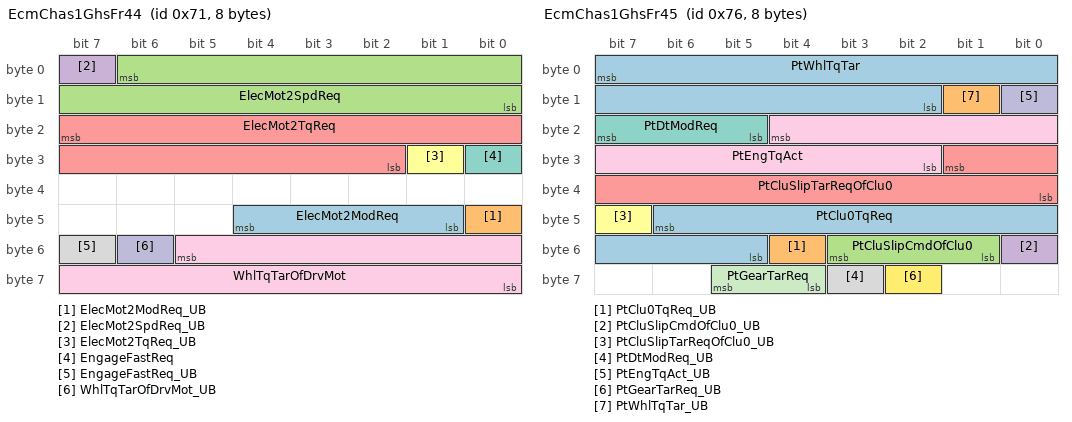
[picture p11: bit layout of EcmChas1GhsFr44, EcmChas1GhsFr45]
BO_ 113 EcmChas1GhsFr44 : 8 ECM
 SG_ ElecMot2ModReq : 44|4@0+ (1,0) [0|15] "" TCM,VDDM
 SG_ ElecMot2ModReq_UB : 40|1@0+ (1,0) [0|1] "" TCM,VDDM
 SG_ ElecMot2SpdReq : 6|15@0- (1.0,0.0) [-16384.0|16383.0] "rpm" TCM
 SG_ ElecMot2SpdReq_UB : 7|1@0+ (1,0) [0|1] "" TCM
 SG_ ElecMot2TqReq : 23|14@0+ (1.0,-8188.0) [-8188.0|8192.0] "NewtonMeter" TCM
 SG_ ElecMot2TqReq_UB : 25|1@0+ (1,0) [0|1] "" TCM
 SG_ EngageFastReq : 24|1@0+ (1,0) [0|1] "" TCM
 SG_ EngageFastReq_UB : 55|1@0+ (1,0) [0|1] "" TCM
 SG_ WhlTqTarOfDrvMot : 53|14@0+ (1.0,-6383.0) [-6383.0|10000.0] "NewtonMeter" TCM
 SG_ WhlTqTarOfDrvMot_UB : 54|1@0+ (1,0) [0|1] "" TCM

BO_ 118 EcmChas1GhsFr45 : 8 ECM
 SG_ PtClu0TqReq : 46|10@0+ (1.0,0.0) [0.0|1023.0] "Unitless" TCM
 SG_ PtClu0TqReq_UB : 52|1@0+ (1,0) [0|1] "" TCM
 SG_ PtCluSlipCmdOfClu0 : 51|3@0+ (1,0) [0|7] "" TCM
 SG_ PtCluSlipCmdOfClu0_UB : 48|1@0+ (1,0) [0|1] "" TCM
 SG_ PtCluSlipTarReqOfClu0 : 25|10@0+ (1.0,0.0) [0.0|1023.0] "Unitless" TCM
 SG_ PtCluSlipTarReqOfClu0_UB : 47|1@0+ (1,0) [0|1] "" TCM
 SG_ PtDtModReq : 23|3@0+ (1,0) [0|7] "" TCM,VDDM
 SG_ PtDtModReq_UB : 59|1@0+ (1,0) [0|1] "" TCM,VDDM
 SG_ PtEngTqAct : 20|11@0+ (1.0,-1024.0) [-1024.0|1023.0] "NewtonMeter" TCM
 SG_ PtEngTqAct_UB : 8|1@0+ (1,0) [0|1] "" TCM
 SG_ PtGearTarReq : 61|2@0+ (1,0) [0|3] "" TCM
 SG_ PtGearTarReq_UB : 58|1@0+ (1,0) [0|1] "" TCM
 SG_ PtWhlTqTar : 7|14@0+ (1.0,-6383.0) [-6383.0|10000.0] "NewtonMeter" TCM
 SG_ PtWhlTqTar_UB : 9|1@0+ (1,0) [0|1] "" TCM

BO_ 133 EcmChas1GhsFr47 : 8 ECM
 SG_ EngTqCpMax : 6|11@0+ (1.0,-1024.0) [-1024.0|1023.0] "NewtonMeter" TCM,VDDM
 SG_ EngTqCpMax_UB : 7|1@0+ (1,0) [0|1] "" TCM,VDDM
 SG_ EngTqCpMin : 11|11@0+ (1.0,-1024.0) [-1024.0|1023.0] "NewtonMeter" TCM,VDDM
 SG_ EngTqCpMin_UB : 16|1@0+ (1,0) [0|1] "" TCM,VDDM

BO_ 1296 EcmChas1NMFr : 8 ECM
 SG_ PNC16_ECM : 16|1@0+ (1,0) [0|0] "" ASDM, BBM
 SG_ PNC17_ECM : 17|1@0+ (1,0) [0|0] "" ASDM, BBM
 SG_ PNC18_ECM : 18|1@0+ (1,0) [0|0] "" ASDM, BBM
 SG_ PNC19_ECM : 19|1@0+ (1,0) [0|0] "" ASDM, BBM
 SG_ PNC20_ECM : 20|1@0+ (1,0) [0|0] "" ASDM, BBM
 SG_ PNC21_ECM : 21|1@0+ (1,0) [0|0] "" ASDM, BBM
 SG_ PNC22_ECM : 22|1@0+ (1,0) [0|0] "" ASDM, BBM
 SG_ PNC23_ECM : 23|1@0+ (1,0) [0|0] "" ASDM, BBM
 SG_ PNC24_ECM : 24|1@0+ (1,0) [0|0] "" ASDM, BBM
 SG_ PNC25_ECM : 25|1@0+ (1,0) [0|0] "" ASDM, BBM
 SG_ PNC26_ECM : 26|1@0+ (1,0) [0|0] "" ASDM, BBM
 SG_ PNC27_ECM : 27|1@0+ (1,0) [0|0] "" ASDM, BBM
 SG_ PNC28_ECM : 28|1@0+ (1,0) [0|0] "" ASDM, BBM
 SG_ PNC29_ECM : 29|1@0+ (1,0) [0|0] "" ASDM, BBM
 SG_ PNC30_ECM : 30|1@0+ (1,0) [0|0] "" ASDM, BBM
 SG_ PNC31_ECM : 31|1@0+ (1,0) [0|0] "" ASDM, BBM
 SG_ PNC32_ECM : 32|1@0+ (1,0) [0|0] "" ASDM, BBM
 SG_ PNC33_ECM : 33|1@0+ (1,0) [0|0] "" ASDM, BBM
 SG_ PNC34_ECM : 34|1@0+ (1,0) [0|0] "" ASDM, BBM
 SG_ PNC35_ECM : 35|1@0+ (1,0) [0|0] "" ASDM, BBM
 SG_ PNC36_ECM : 36|1@0+ (1,0) [0|0] "" ASDM, BBM
 SG_ PNC37_ECM : 37|1@0+ (1,0) [0|0] "" ASDM, BBM
 SG_ PNC38_ECM : 38|1@0+ (1,0) [0|0] "" ASDM, BBM
 SG_ PNC39_ECM : 39|1@0+ (1,0) [0|0] "" ASDM, BBM
 SG_ PNC40_ECM : 40|1@0+ (1,0) [0|0] "" ASDM, BBM
 SG_ PNC41_ECM : 41|1@0+ (1,0) [0|0] "" ASDM, BBM
 SG_ PNC42_ECM : 42|1@0+ (1,0) [0|0] "" ASDM, BBM
 SG_ NM_PNI_ECM : 14|1@0+ (1,0) [0|0] "" ASDM, BBM
 SG_ NM_AW_ECM : 12|1@0+ (1,0) [0|0] "" ASDM, BBM
 SG_ NM_CS_ECM : 11|1@0+ (1,0) [0|0] "" ASDM, BBM
 SG_ NM_RMR_ECM : 8|1@0+ (1,0) [0|0] "" ASDM, BBM
 SG_ NM_NodeID_ECM : 7|8@0+ (1,0) [0|0] "" ASDM, BBM

BO_ 1429 EtcToMvemXcpFr01 : 8 ETC

BO_ 1424 EtcToMvemXcpFr02 : 8 ETC

BO_ 1425 EtcToMvemXcpFr03 : 8 ETC

BO_ 1441 EtcToPscm1cChas1XcpFr01 : 8 ETC

BO_ 1409 EtcToPscmChas1XcpFr01 : 8 ETC

BO_ 1416 EtcToPscmChas1XcpFr02 : 8 ETC

BO_ 1418 EtcToPscmChas1XcpFr03 : 8 ETC

BO_ 1420 EtcToPscmChas1XcpFr04 : 8 ETC

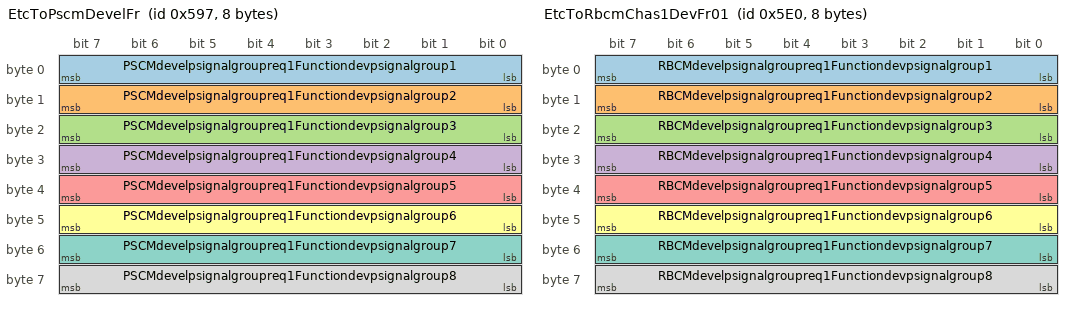
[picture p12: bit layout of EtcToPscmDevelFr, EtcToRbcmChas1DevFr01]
BO_ 1431 EtcToPscmDevelFr : 8 ETC
 SG_ PSCMdevelpsignalgroupreq1Functiondevpsignalgroup1 : 7|8@0+ (1.0,0.0) [0.0|255.0] "Unitless" PSCM1
 SG_ PSCMdevelpsignalgroupreq1Functiondevpsignalgroup2 : 15|8@0+ (1.0,0.0) [0.0|255.0] "Unitless" PSCM1
 SG_ PSCMdevelpsignalgroupreq1Functiondevpsignalgroup3 : 23|8@0+ (1.0,0.0) [0.0|255.0] "Unitless" PSCM1
 SG_ PSCMdevelpsignalgroupreq1Functiondevpsignalgroup4 : 31|8@0+ (1.0,0.0) [0.0|255.0] "Unitless" PSCM1
 SG_ PSCMdevelpsignalgroupreq1Functiondevpsignalgroup5 : 39|8@0+ (1.0,0.0) [0.0|255.0] "Unitless" PSCM1
 SG_ PSCMdevelpsignalgroupreq1Functiondevpsignalgroup6 : 47|8@0+ (1.0,0.0) [0.0|255.0] "Unitless" PSCM1
 SG_ PSCMdevelpsignalgroupreq1Functiondevpsignalgroup7 : 55|8@0+ (1.0,0.0) [0.0|255.0] "Unitless" PSCM1
 SG_ PSCMdevelpsignalgroupreq1Functiondevpsignalgroup8 : 63|8@0+ (1.0,0.0) [0.0|255.0] "Unitless" PSCM1

BO_ 1442 EtcToRasmChas1XcpFr01 : 8 ETC

BO_ 1504 EtcToRbcmChas1DevFr01 : 8 ETC
 SG_ RBCMdevelpsignalgroupreq1Functiondevpsignalgroup1 : 7|8@0+ (1.0,0.0) [0.0|255.0] "Unitless" Vector__XXX
 SG_ RBCMdevelpsignalgroupreq1Functiondevpsignalgroup2 : 15|8@0+ (1.0,0.0) [0.0|255.0] "Unitless" Vector__XXX
 SG_ RBCMdevelpsignalgroupreq1Functiondevpsignalgroup3 : 23|8@0+ (1.0,0.0) [0.0|255.0] "Unitless" Vector__XXX
 SG_ RBCMdevelpsignalgroupreq1Functiondevpsignalgroup4 : 31|8@0+ (1.0,0.0) [0.0|255.0] "Unitless" Vector__XXX
 SG_ RBCMdevelpsignalgroupreq1Functiondevpsignalgroup5 : 39|8@0+ (1.0,0.0) [0.0|255.0] "Unitless" Vector__XXX
 SG_ RBCMdevelpsignalgroupreq1Functiondevpsignalgroup6 : 47|8@0+ (1.0,0.0) [0.0|255.0] "Unitless" Vector__XXX
 SG_ RBCMdevelpsignalgroupreq1Functiondevpsignalgroup7 : 55|8@0+ (1.0,0.0) [0.0|255.0] "Unitless" Vector__XXX
 SG_ RBCMdevelpsignalgroupreq1Functiondevpsignalgroup8 : 63|8@0+ (1.0,0.0) [0.0|255.0] "Unitless" Vector__XXX

BO_ 1414 EtcToTcmXcpFr01 : 8 ETC

BO_ 1411 EtcToTcmXcpFr02 : 8 ETC

BO_ 1421 EtctoVddmBcmXCPFr01 : 8 ETC

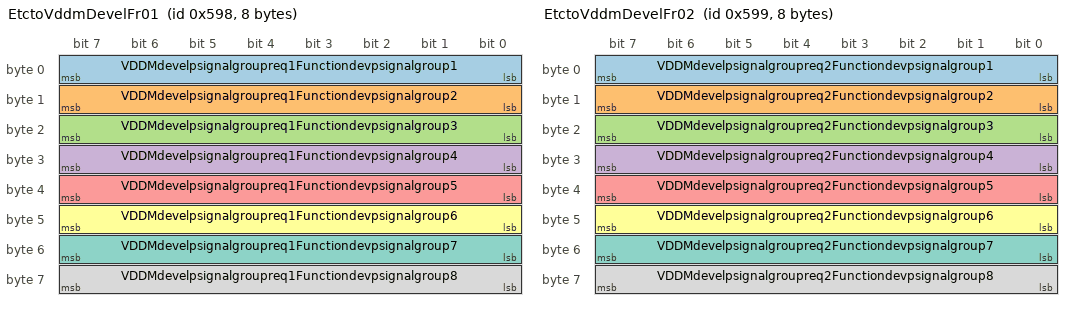
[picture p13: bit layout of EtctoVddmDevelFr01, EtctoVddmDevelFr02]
BO_ 1432 EtctoVddmDevelFr01 : 8 ETC
 SG_ VDDMdevelpsignalgroupreq1Functiondevpsignalgroup1 : 7|8@0+ (1.0,0.0) [0.0|255.0] "Unitless" BBM
 SG_ VDDMdevelpsignalgroupreq1Functiondevpsignalgroup2 : 15|8@0+ (1.0,0.0) [0.0|255.0] "Unitless" BBM
 SG_ VDDMdevelpsignalgroupreq1Functiondevpsignalgroup3 : 23|8@0+ (1.0,0.0) [0.0|255.0] "Unitless" BBM
 SG_ VDDMdevelpsignalgroupreq1Functiondevpsignalgroup4 : 31|8@0+ (1.0,0.0) [0.0|255.0] "Unitless" BBM
 SG_ VDDMdevelpsignalgroupreq1Functiondevpsignalgroup5 : 39|8@0+ (1.0,0.0) [0.0|255.0] "Unitless" BBM
 SG_ VDDMdevelpsignalgroupreq1Functiondevpsignalgroup6 : 47|8@0+ (1.0,0.0) [0.0|255.0] "Unitless" BBM
 SG_ VDDMdevelpsignalgroupreq1Functiondevpsignalgroup7 : 55|8@0+ (1.0,0.0) [0.0|255.0] "Unitless" BBM
 SG_ VDDMdevelpsignalgroupreq1Functiondevpsignalgroup8 : 63|8@0+ (1.0,0.0) [0.0|255.0] "Unitless" BBM

BO_ 1433 EtctoVddmDevelFr02 : 8 ETC
 SG_ VDDMdevelpsignalgroupreq2Functiondevpsignalgroup1 : 7|8@0+ (1.0,0.0) [0.0|255.0] "Unitless" BBM
 SG_ VDDMdevelpsignalgroupreq2Functiondevpsignalgroup2 : 15|8@0+ (1.0,0.0) [0.0|255.0] "Unitless" BBM
 SG_ VDDMdevelpsignalgroupreq2Functiondevpsignalgroup3 : 23|8@0+ (1.0,0.0) [0.0|255.0] "Unitless" BBM
 SG_ VDDMdevelpsignalgroupreq2Functiondevpsignalgroup4 : 31|8@0+ (1.0,0.0) [0.0|255.0] "Unitless" BBM
 SG_ VDDMdevelpsignalgroupreq2Functiondevpsignalgroup5 : 39|8@0+ (1.0,0.0) [0.0|255.0] "Unitless" BBM
 SG_ VDDMdevelpsignalgroupreq2Functiondevpsignalgroup6 : 47|8@0+ (1.0,0.0) [0.0|255.0] "Unitless" BBM
 SG_ VDDMdevelpsignalgroupreq2Functiondevpsignalgroup7 : 55|8@0+ (1.0,0.0) [0.0|255.0] "Unitless" BBM
 SG_ VDDMdevelpsignalgroupreq2Functiondevpsignalgroup8 : 63|8@0+ (1.0,0.0) [0.0|255.0] "Unitless" BBM

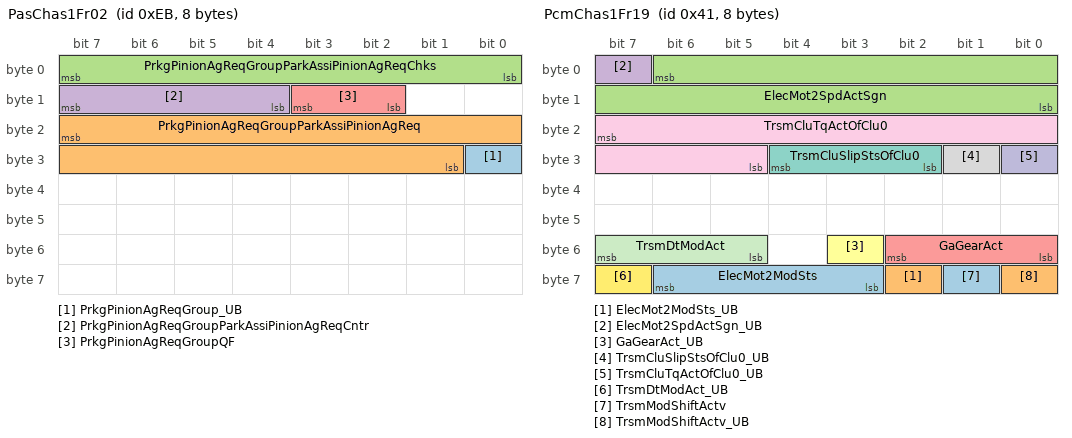
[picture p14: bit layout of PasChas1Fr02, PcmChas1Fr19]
BO_ 235 PasChas1Fr02 : 8 ASDM
 SG_ PrkgPinionAgReqGroup_UB : 24|1@0+ (1,0) [0|1] "" PSCM1
 SG_ PrkgPinionAgReqGroupParkAssiPinionAgReq : 23|15@0+ (0.000976563,-14.5) [-14.5|17.499039821] "rad" PSCM1
 SG_ PrkgPinionAgReqGroupParkAssiPinionAgReqChks : 7|8@0+ (1.0,0.0) [0.0|255.0] "Unitless" PSCM1
 SG_ PrkgPinionAgReqGroupParkAssiPinionAgReqCntr : 15|4@0+ (1.0,0.0) [0.0|15.0] "Unitless" PSCM1
 SG_ PrkgPinionAgReqGroupQF : 11|2@0+ (1,0) [0|3] "" PSCM1

BO_ 149 PasChas1Fr04 : 8 ASDM
 SG_ PrkgGearReqGroup_UB : 10|1@0+ (1,0) [0|1] "" ECM
 SG_ PrkgGearReqGroupChks : 7|8@0+ (1.0,0.0) [0.0|255.0] "Unitless" ECM
 SG_ PrkgGearReqGroupCntr : 15|4@0+ (1.0,0.0) [0.0|15.0] "Unitless" ECM
 SG_ PrkgGearReqGroupReqSts1 : 11|1@0+ (1,0) [0|1] "" ECM

BO_ 65 PcmChas1Fr19 : 8 TCM
 SG_ ElecMot2ModSts : 62|4@0+ (1,0) [0|15] "" BBM,ECM,VDDM
 SG_ ElecMot2ModSts_UB : 58|1@0+ (1,0) [0|1] "" BBM,ECM,VDDM
 SG_ ElecMot2SpdActSgn : 6|15@0- (1.0,0.0) [-16384.0|16383.0] "rpm" BBM,ECM,VDDM
 SG_ ElecMot2SpdActSgn_UB : 7|1@0+ (1,0) [0|1] "" BBM,ECM,VDDM
 SG_ GaGearAct : 50|3@0+ (1.0,0.0) [0.0|7.0] "Unitless" ECM
 SG_ GaGearAct_UB : 51|1@0+ (1,0) [0|1] "" ECM
 SG_ TrsmCluSlipStsOfClu0 : 28|3@0+ (1,0) [0|7] "" ECM
 SG_ TrsmCluSlipStsOfClu0_UB : 25|1@0+ (1,0) [0|1] "" ECM
 SG_ TrsmCluTqActOfClu0 : 23|11@0+ (1.0,-1024.0) [-1024.0|1023.0] "NewtonMeter" ECM
 SG_ TrsmCluTqActOfClu0_UB : 24|1@0+ (1,0) [0|1] "" ECM
 SG_ TrsmDtModAct : 55|3@0+ (1,0) [0|7] "" BBM,ECM
 SG_ TrsmDtModAct_UB : 63|1@0+ (1,0) [0|1] "" BBM,ECM
 SG_ TrsmModShiftActv : 57|1@0+ (1,0) [0|1] "" ECM
 SG_ TrsmModShiftActv_UB : 56|1@0+ (1,0) [0|1] "" ECM

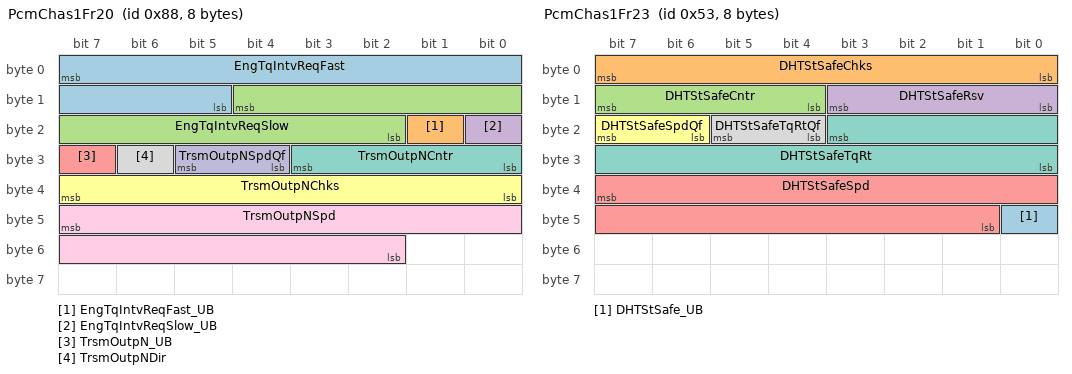
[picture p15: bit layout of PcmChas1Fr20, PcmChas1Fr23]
BO_ 136 PcmChas1Fr20 : 8 TCM
 SG_ EngTqIntvReqFast : 7|11@0+ (1.0,-1024.0) [-1024.0|1023.0] "NewtonMeter" ECM
 SG_ EngTqIntvReqFast_UB : 17|1@0+ (1,0) [0|1] "" ECM
 SG_ EngTqIntvReqSlow : 12|11@0+ (1.0,-1024.0) [-1024.0|1023.0] "NewtonMeter" ECM
 SG_ EngTqIntvReqSlow_UB : 16|1@0+ (1,0) [0|1] "" ECM
 SG_ TrsmOutpN_UB : 31|1@0+ (1,0) [0|1] "" ECM
 SG_ TrsmOutpNChks : 39|8@0+ (1.0,0.0) [0.0|255.0] "Unitless" ECM
 SG_ TrsmOutpNCntr : 27|4@0+ (1.0,0.0) [0.0|15.0] "Unitless" ECM
 SG_ TrsmOutpNDir : 30|1@0+ (1,0) [0|1] "" ECM
 SG_ TrsmOutpNSpd : 47|14@0+ (1.0,0.0) [0.0|16383.0] "Unitless" ECM
 SG_ TrsmOutpNSpdQf : 29|2@0+ (1,0) [0|3] "" ECM

BO_ 262 PcmChas1Fr21 : 8 TCM
 SG_ TrsmClu0FltIndcn : 55|2@0+ (1,0) [0|3] "" ECM
 SG_ TrsmClu0FltIndcn_UB : 39|1@0+ (1,0) [0|1] "" ECM
 SG_ TrsmClu0Sts_UB : 38|1@0+ (1,0) [0|1] "" ECM
 SG_ TrsmClu0StsChks : 47|8@0+ (1.0,0.0) [0.0|255.0] "Unitless" ECM
 SG_ TrsmClu0StsCntr : 35|4@0+ (1.0,0.0) [0.0|15.0] "Unitless" ECM
 SG_ TrsmClu0StsTrsm0CluSts : 37|2@0+ (1,0) [0|3] "" ECM
 SG_ TrsmCluTqCpMaxOfClu0 : 7|11@0+ (1.0,-1024.0) [-1024.0|1023.0] "NewtonMeter" ECM
 SG_ TrsmCluTqCpMaxOfClu0_UB : 10|1@0+ (1,0) [0|1] "" ECM
 SG_ TrsmGearActrScanForRefActv3DHT : 53|1@0+ (1,0) [0|1] "" ECM
 SG_ TrsmGearActrScanForRefActv3DHT_UB : 52|1@0+ (1,0) [0|1] "" ECM
 SG_ TrsmGearActrScanForRefReq3DHT : 63|1@0+ (1,0) [0|1] "" ECM
 SG_ TrsmGearActrScanForRefReq3DHT_UB : 62|1@0+ (1,0) [0|1] "" ECM
 SG_ TrsmGearEngmtSts : 50|3@0+ (1.0,0.0) [0.0|7.0] "Unitless" ECM
 SG_ TrsmGearEngmtSts_UB : 51|1@0+ (1,0) [0|1] "" ECM
 SG_ TrsmParkLockSt : 12|2@0+ (1,0) [0|3] "" ECM,VDDM
 SG_ TrsmParkLockSt_UB : 9|1@0+ (1,0) [0|1] "" ECM,VDDM
 SG_ TrsmRotReq : 61|1@0+ (1,0) [0|1] "" ECM
 SG_ TrsmRotReq_UB : 60|1@0+ (1,0) [0|1] "" ECM
 SG_ TrsmWhlProtnMaxTq : 23|16@0- (1.0,0.0) [-20000.0|20000.0] "NewtonMeter" ECM
 SG_ TrsmWhlProtnMaxTq_UB : 8|1@0+ (1,0) [0|1] "" ECM

BO_ 1142 PcmChas1Fr22 : 8 TCM
 SG_ TOCCooltFlowReq : 7|10@0+ (0.02,0.0) [0.0|20.46] "L / min" ECM,VDDM
 SG_ TOCCooltFlowReq_UB : 13|1@0+ (1,0) [0|1] "" ECM,VDDM

BO_ 83 PcmChas1Fr23 : 8 TCM
 SG_ DHTStSafe_UB : 40|1@0+ (1,0) [0|1] "" ECM
 SG_ DHTStSafeChks : 7|8@0+ (1.0,0.0) [0.0|255.0] "Unitless" ECM
 SG_ DHTStSafeCntr : 15|4@0+ (1.0,0.0) [0.0|15.0] "Unitless" ECM
 SG_ DHTStSafeRsv : 11|4@0+ (1.0,0.0) [0.0|15.0] "Unitless" ECM
 SG_ DHTStSafeSpd : 39|15@0- (1.0,0.0) [-16384.0|16383.0] "rpm" ECM
 SG_ DHTStSafeSpdQf : 23|2@0+ (1,0) [0|3] "" ECM
 SG_ DHTStSafeTqRt : 19|12@0+ (0.01,0.0) [0.0|40.95] "Unitless" ECM
 SG_ DHTStSafeTqRtQf : 21|2@0+ (1,0) [0|3] "" ECM

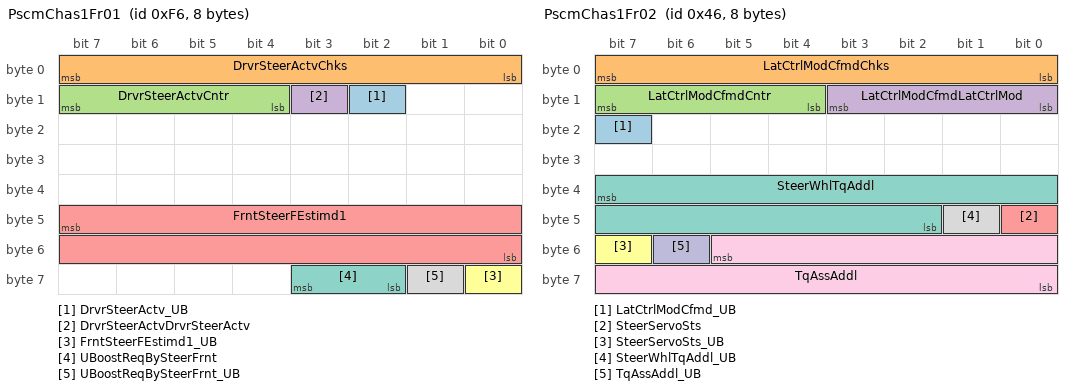
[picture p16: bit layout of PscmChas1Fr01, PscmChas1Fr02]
BO_ 246 PscmChas1Fr01 : 8 PSCM1
 SG_ DrvrSteerActv_UB : 10|1@0+ (1,0) [0|1] "" ASDM
 SG_ DrvrSteerActvChks : 7|8@0+ (1.0,0.0) [0.0|255.0] "Unitless" ASDM
 SG_ DrvrSteerActvCntr : 15|4@0+ (1.0,0.0) [0.0|15.0] "Unitless" ASDM
 SG_ DrvrSteerActvDrvrSteerActv : 11|1@0+ (1,0) [0|1] "" ASDM
 SG_ FrntSteerFEstimd1 : 47|16@0- (1.0,0.0) [-32768.0|32767.0] "N" BBM,VDDM
 SG_ FrntSteerFEstimd1_UB : 56|1@0+ (1,0) [0|1] "" BBM,VDDM
 SG_ UBoostReqBySteerFrnt : 59|2@0+ (1,0) [0|3] "" ECM,VDDM
 SG_ UBoostReqBySteerFrnt_UB : 57|1@0+ (1,0) [0|1] "" ECM,VDDM

BO_ 70 PscmChas1Fr02 : 8 PSCM1
 SG_ LatCtrlModCfmd_UB : 23|1@0+ (1,0) [0|1] "" ASDM,BBM,VDDM
 SG_ LatCtrlModCfmdChks : 7|8@0+ (1.0,0.0) [0.0|255.0] "Unitless" ASDM,BBM,VDDM
 SG_ LatCtrlModCfmdCntr : 15|4@0+ (1.0,0.0) [0.0|15.0] "Unitless" ASDM,BBM,VDDM
 SG_ LatCtrlModCfmdLatCtrlMod : 11|4@0+ (1,0) [0|15] "" ASDM,BBM,VDDM
 SG_ SteerServoSts : 40|1@0+ (1,0) [0|1] "" ASDM,VDDM
 SG_ SteerServoSts_UB : 55|1@0+ (1,0) [0|1] "" ASDM,VDDM
 SG_ SteerWhlTqAddl : 39|14@0- (0.00390625,0.0) [-30.0|30.0] "NewtonMeter" ASDM,BBM,VDDM
 SG_ SteerWhlTqAddl_UB : 41|1@0+ (1,0) [0|1] "" ASDM,BBM,VDDM
 SG_ TqAssAddl : 53|14@0- (0.00390625,0.0) [-30.0|30.0] "NewtonMeter" ASDM
 SG_ TqAssAddl_UB : 54|1@0+ (1,0) [0|1] "" ASDM

BO_ 444 PscmChas1Fr03 : 8 PSCM1
 SG_ DrvrSteerWhlHldGroup_UB : 1|1@0+ (1,0) [0|1] "" ASDM,VDDM
 SG_ DrvrSteerWhlHldGroupDrvrSteerWhlHld : 7|2@0+ (1,0) [0|3] "" ASDM,VDDM
 SG_ DrvrSteerWhlHldGroupDrvrSteerWhlHldQly : 5|4@0+ (1.0,0.0) [0.0|15.0] "Unitless" ASDM,VDDM
 SG_ SteerErrReq : 46|3@0+ (1,0) [0|7] "" VDDM
 SG_ SteerErrReq_UB : 47|1@0+ (1,0) [0|1] "" VDDM
 SG_ SteerExtFctSts_UB : 43|1@0+ (1,0) [0|1] "" ASDM
 SG_ SteerExtFctStsChks : 63|8@0+ (1.0,0.0) [0.0|255.0] "Unitless" ASDM
 SG_ SteerExtFctStsCntr : 51|4@0+ (1.0,0.0) [0.0|15.0] "Unitless" ASDM
 SG_ SteerExtFctStsDrvrSteerOvrd : 52|1@0+ (1,0) [0|1] "" ASDM
 SG_ SteerExtFctStsExtFctLowerLimActive : 53|1@0+ (1,0) [0|1] "" ASDM
 SG_ SteerExtFctStsExtFctRateLimActive : 54|1@0+ (1,0) [0|1] "" ASDM
 SG_ SteerExtFctStsExtFctUpperLimActive : 55|1@0+ (1,0) [0|1] "" ASDM
 SG_ SteerExtFctStsExtSafeLimActive : 40|1@0+ (1,0) [0|1] "" ASDM
 SG_ SteerExtFctStsLatAgReqNotInRange : 41|1@0+ (1,0) [0|1] "" ASDM
 SG_ SteerExtFctStsLatCtrlReqNotInRange : 42|1@0+ (1,0) [0|1] "" ASDM
 SG_ SteerStsToParkAssi : 15|3@0+ (1,0) [0|7] "" ASDM,BBM
 SG_ SteerStsToParkAssi_UB : 0|1@0+ (1,0) [0|1] "" ASDM,BBM

BO_ 955 PscmChas1Fr06 : 8 PSCM1
 SG_ PinionSteerAgMax1 : 54|15@0- (0.0009765625,0.0) [-14.5|14.5] "rad" VDDM
 SG_ PinionSteerAgMax1_UB : 55|1@0+ (1,0) [0|1] "" VDDM

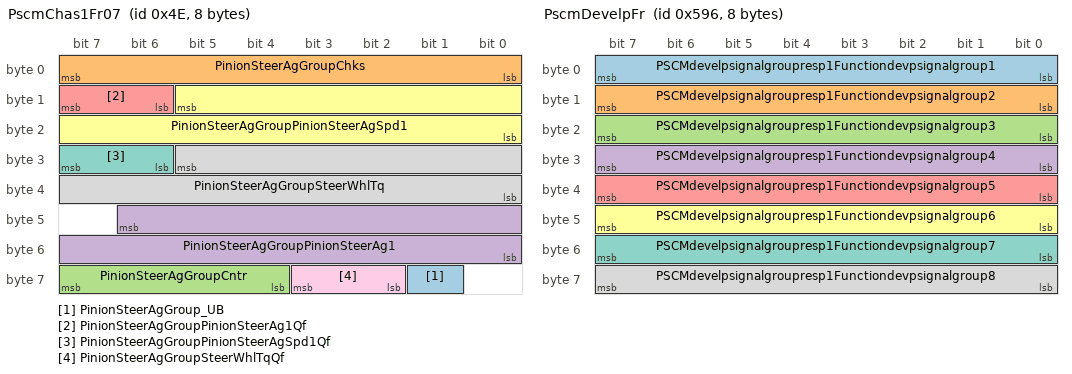
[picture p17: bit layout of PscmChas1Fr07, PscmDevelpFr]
BO_ 78 PscmChas1Fr07 : 8 PSCM1
 SG_ PinionSteerAgGroup_UB : 57|1@0+ (1,0) [0|1] "" ASDM,BBM,VDDM
 SG_ PinionSteerAgGroupChks : 7|8@0+ (1.0,0.0) [0.0|255.0] "Unitless" ASDM,BBM,VDDM
 SG_ PinionSteerAgGroupCntr : 63|4@0+ (1.0,0.0) [0.0|15.0] "Unitless" ASDM,BBM,VDDM
 SG_ PinionSteerAgGroupPinionSteerAg1 : 46|15@0- (0.0009765625,0.0) [-14.5|14.5] "rad" ASDM,BBM,VDDM
 SG_ PinionSteerAgGroupPinionSteerAg1Qf : 15|2@0+ (1,0) [0|3] "" ASDM,BBM,VDDM
 SG_ PinionSteerAgGroupPinionSteerAgSpd1 : 13|14@0- (0.0078125,0.0) [-50.0|50.0] "rad/s" ASDM,BBM,VDDM
 SG_ PinionSteerAgGroupPinionSteerAgSpd1Qf : 31|2@0+ (1,0) [0|3] "" ASDM,BBM,VDDM
 SG_ PinionSteerAgGroupSteerWhlTq : 29|14@0- (0.00390625,0.0) [-30.0|30.0] "NewtonMeter" ASDM,BBM,VDDM
 SG_ PinionSteerAgGroupSteerWhlTqQf : 59|2@0+ (1,0) [0|3] "" ASDM,BBM,VDDM

BO_ 1315 PscmChas1NMFr : 8 PSCM1
 SG_ PNC16_PSCM1 : 16|1@0+ (1,0) [0|0] "" Vector__XXX
 SG_ PNC17_PSCM1 : 17|1@0+ (1,0) [0|0] "" Vector__XXX
 SG_ PNC18_PSCM1 : 18|1@0+ (1,0) [0|0] "" Vector__XXX
 SG_ PNC19_PSCM1 : 19|1@0+ (1,0) [0|0] "" Vector__XXX
 SG_ PNC20_PSCM1 : 20|1@0+ (1,0) [0|0] "" Vector__XXX
 SG_ PNC21_PSCM1 : 21|1@0+ (1,0) [0|0] "" Vector__XXX
 SG_ PNC22_PSCM1 : 22|1@0+ (1,0) [0|0] "" Vector__XXX
 SG_ PNC23_PSCM1 : 23|1@0+ (1,0) [0|0] "" Vector__XXX
 SG_ PNC24_PSCM1 : 24|1@0+ (1,0) [0|0] "" Vector__XXX
 SG_ PNC25_PSCM1 : 25|1@0+ (1,0) [0|0] "" Vector__XXX
 SG_ PNC26_PSCM1 : 26|1@0+ (1,0) [0|0] "" Vector__XXX
 SG_ PNC27_PSCM1 : 27|1@0+ (1,0) [0|0] "" Vector__XXX
 SG_ PNC28_PSCM1 : 28|1@0+ (1,0) [0|0] "" Vector__XXX
 SG_ PNC29_PSCM1 : 29|1@0+ (1,0) [0|0] "" Vector__XXX
 SG_ PNC30_PSCM1 : 30|1@0+ (1,0) [0|0] "" Vector__XXX
 SG_ PNC31_PSCM1 : 31|1@0+ (1,0) [0|0] "" Vector__XXX
 SG_ PNC32_PSCM1 : 32|1@0+ (1,0) [0|0] "" Vector__XXX
 SG_ PNC33_PSCM1 : 33|1@0+ (1,0) [0|0] "" Vector__XXX
 SG_ PNC34_PSCM1 : 34|1@0+ (1,0) [0|0] "" Vector__XXX
 SG_ PNC35_PSCM1 : 35|1@0+ (1,0) [0|0] "" Vector__XXX
 SG_ PNC36_PSCM1 : 36|1@0+ (1,0) [0|0] "" Vector__XXX
 SG_ PNC37_PSCM1 : 37|1@0+ (1,0) [0|0] "" Vector__XXX
 SG_ PNC38_PSCM1 : 38|1@0+ (1,0) [0|0] "" Vector__XXX
 SG_ PNC39_PSCM1 : 39|1@0+ (1,0) [0|0] "" Vector__XXX
 SG_ PNC40_PSCM1 : 40|1@0+ (1,0) [0|0] "" Vector__XXX
 SG_ PNC41_PSCM1 : 41|1@0+ (1,0) [0|0] "" Vector__XXX
 SG_ PNC42_PSCM1 : 42|1@0+ (1,0) [0|0] "" Vector__XXX
 SG_ NM_PNI_PSCM1 : 14|1@0+ (1,0) [0|0] "" Vector__XXX
 SG_ NM_AW_PSCM1 : 12|1@0+ (1,0) [0|0] "" Vector__XXX
 SG_ NM_CS_PSCM1 : 11|1@0+ (1,0) [0|0] "" Vector__XXX
 SG_ NM_RMR_PSCM1 : 8|1@0+ (1,0) [0|0] "" Vector__XXX
 SG_ NM_NodeID_PSCM1 : 7|8@0+ (1,0) [0|0] "" Vector__XXX

BO_ 1430 PscmDevelpFr : 8 PSCM1
 SG_ PSCMdevelpsignalgroupresp1Functiondevpsignalgroup1 : 7|8@0+ (1.0,0.0) [0.0|255.0] "Unitless" ETC
 SG_ PSCMdevelpsignalgroupresp1Functiondevpsignalgroup2 : 15|8@0+ (1.0,0.0) [0.0|255.0] "Unitless" ETC
 SG_ PSCMdevelpsignalgroupresp1Functiondevpsignalgroup3 : 23|8@0+ (1.0,0.0) [0.0|255.0] "Unitless" ETC
 SG_ PSCMdevelpsignalgroupresp1Functiondevpsignalgroup4 : 31|8@0+ (1.0,0.0) [0.0|255.0] "Unitless" ETC
 SG_ PSCMdevelpsignalgroupresp1Functiondevpsignalgroup5 : 39|8@0+ (1.0,0.0) [0.0|255.0] "Unitless" ETC
 SG_ PSCMdevelpsignalgroupresp1Functiondevpsignalgroup6 : 47|8@0+ (1.0,0.0) [0.0|255.0] "Unitless" ETC
 SG_ PSCMdevelpsignalgroupresp1Functiondevpsignalgroup7 : 55|8@0+ (1.0,0.0) [0.0|255.0] "Unitless" ETC
 SG_ PSCMdevelpsignalgroupresp1Functiondevpsignalgroup8 : 63|8@0+ (1.0,0.0) [0.0|255.0] "Unitless" ETC

BO_ 1410 PscmToEtcChas1XcpFr01 : 8 PSCM1

BO_ 1417 PscmToEtcChas1XcpFr02 : 8 PSCM1

BO_ 1419 PscmToEtcChas1XcpFr03 : 8 PSCM1

BO_ 1415 PscmToEtcChas1XcpFr04 : 8 PSCM1

BO_ 1412 PscmToEtcChas1XcpFr05 : 8 PSCM1

BO_ 1423 PscmToEtcChas1XcpFr06 : 8 PSCM1

BO_ 1648 PscmToVddmChas1DiagResFrame : 8 PSCM1
 SG_ PscmToVddmChas1DiagResNpdu : 7|64@0+ (1,0) [0|0] "" VDDM

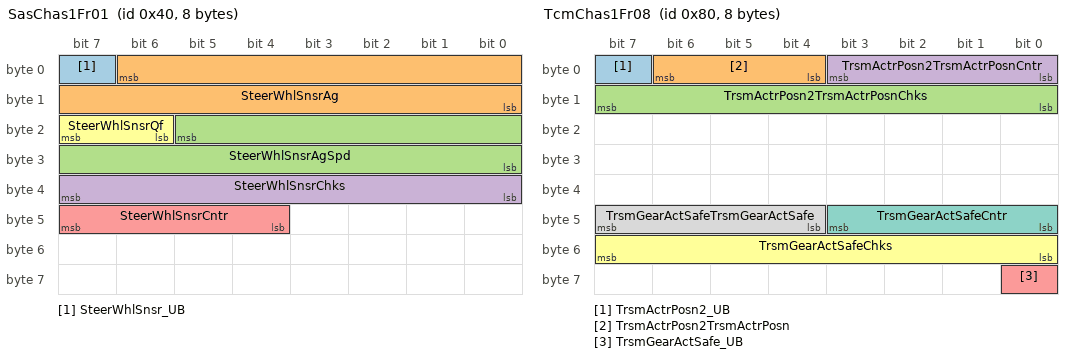
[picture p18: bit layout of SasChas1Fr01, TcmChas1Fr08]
BO_ 64 SasChas1Fr01 : 8 SAS
 SG_ SteerWhlSnsr_UB : 7|1@0+ (1,0) [0|1] "" ASDM,BBM,ECM,PSCM1,VDDM
 SG_ SteerWhlSnsrAg : 6|15@0- (0.0009765625,0.0) [-14.5|14.5] "rad" ASDM,BBM,ECM,PSCM1,VDDM
 SG_ SteerWhlSnsrAgSpd : 21|14@0- (0.0078125,0.0) [-50.0|50.0] "rad/s" ASDM,BBM,ECM,PSCM1,VDDM
 SG_ SteerWhlSnsrChks : 39|8@0+ (1.0,0.0) [0.0|255.0] "Unitless" ASDM,BBM,ECM,PSCM1,VDDM
 SG_ SteerWhlSnsrCntr : 47|4@0+ (1.0,0.0) [0.0|15.0] "Unitless" ASDM,BBM,ECM,PSCM1,VDDM
 SG_ SteerWhlSnsrQf : 23|2@0+ (1,0) [0|3] "" ASDM,BBM,ECM,PSCM1,VDDM

BO_ 1319 SasChas1NMFr : 8 SAS
 SG_ PNC16_SAS : 16|1@0+ (1,0) [0|0] "" Vector__XXX
 SG_ PNC17_SAS : 17|1@0+ (1,0) [0|0] "" Vector__XXX
 SG_ PNC18_SAS : 18|1@0+ (1,0) [0|0] "" Vector__XXX
 SG_ PNC19_SAS : 19|1@0+ (1,0) [0|0] "" Vector__XXX
 SG_ PNC20_SAS : 20|1@0+ (1,0) [0|0] "" Vector__XXX
 SG_ PNC21_SAS : 21|1@0+ (1,0) [0|0] "" Vector__XXX
 SG_ PNC22_SAS : 22|1@0+ (1,0) [0|0] "" Vector__XXX
 SG_ PNC23_SAS : 23|1@0+ (1,0) [0|0] "" Vector__XXX
 SG_ PNC24_SAS : 24|1@0+ (1,0) [0|0] "" Vector__XXX
 SG_ PNC25_SAS : 25|1@0+ (1,0) [0|0] "" Vector__XXX
 SG_ PNC26_SAS : 26|1@0+ (1,0) [0|0] "" Vector__XXX
 SG_ PNC27_SAS : 27|1@0+ (1,0) [0|0] "" Vector__XXX
 SG_ PNC28_SAS : 28|1@0+ (1,0) [0|0] "" Vector__XXX
 SG_ PNC29_SAS : 29|1@0+ (1,0) [0|0] "" Vector__XXX
 SG_ PNC30_SAS : 30|1@0+ (1,0) [0|0] "" Vector__XXX
 SG_ PNC31_SAS : 31|1@0+ (1,0) [0|0] "" Vector__XXX
 SG_ PNC32_SAS : 32|1@0+ (1,0) [0|0] "" Vector__XXX
 SG_ PNC33_SAS : 33|1@0+ (1,0) [0|0] "" Vector__XXX
 SG_ PNC34_SAS : 34|1@0+ (1,0) [0|0] "" Vector__XXX
 SG_ PNC35_SAS : 35|1@0+ (1,0) [0|0] "" Vector__XXX
 SG_ PNC36_SAS : 36|1@0+ (1,0) [0|0] "" Vector__XXX
 SG_ PNC37_SAS : 37|1@0+ (1,0) [0|0] "" Vector__XXX
 SG_ PNC38_SAS : 38|1@0+ (1,0) [0|0] "" Vector__XXX
 SG_ PNC39_SAS : 39|1@0+ (1,0) [0|0] "" Vector__XXX
 SG_ PNC40_SAS : 40|1@0+ (1,0) [0|0] "" Vector__XXX
 SG_ PNC41_SAS : 41|1@0+ (1,0) [0|0] "" Vector__XXX
 SG_ PNC42_SAS : 42|1@0+ (1,0) [0|0] "" Vector__XXX
 SG_ NM_PNI_SAS : 14|1@0+ (1,0) [0|0] "" Vector__XXX
 SG_ NM_AW_SAS : 12|1@0+ (1,0) [0|0] "" Vector__XXX
 SG_ NM_CS_SAS : 11|1@0+ (1,0) [0|0] "" Vector__XXX
 SG_ NM_RMR_SAS : 8|1@0+ (1,0) [0|0] "" Vector__XXX
 SG_ NM_NodeID_SAS : 7|8@0+ (1,0) [0|0] "" Vector__XXX

BO_ 1650 SasToVddmChas1DiagResFrame : 8 SAS
 SG_ SasToVddmChas1DiagResNpdu : 7|64@0+ (1,0) [0|0] "" VDDM

BO_ 128 TcmChas1Fr08 : 8 TCM
 SG_ TrsmActrPosn2_UB : 7|1@0+ (1,0) [0|1] "" ECM
 SG_ TrsmActrPosn2TrsmActrPosn : 6|3@0+ (1,0) [0|7] "" ECM
 SG_ TrsmActrPosn2TrsmActrPosnChks : 15|8@0+ (1.0,0.0) [0.0|255.0] "Unitless" ECM
 SG_ TrsmActrPosn2TrsmActrPosnCntr : 3|4@0+ (1.0,0.0) [0.0|15.0] "Unitless" ECM
 SG_ TrsmGearActSafe_UB : 56|1@0+ (1,0) [0|1] "" ECM
 SG_ TrsmGearActSafeChks : 55|8@0+ (1.0,0.0) [0.0|255.0] "Unitless" ECM
 SG_ TrsmGearActSafeCntr : 43|4@0+ (1.0,0.0) [0.0|15.0] "Unitless" ECM
 SG_ TrsmGearActSafeTrsmGearActSafe : 47|4@0+ (1,0) [0|15] "" ECM

BO_ 512 TcmChas1Fr09 : 8 TCM
 SG_ TrsmClrRdyReq : 21|1@0+ (1,0) [0|1] "" ECM
 SG_ TrsmClrRdyReq_UB : 20|1@0+ (1,0) [0|1] "" ECM
 SG_ TrsmCluTEstimdOfClu0 : 31|9@0+ (1.25,-40.0) [-40.0|598.75] "degC" ECM
 SG_ TrsmCluTEstimdOfClu0_UB : 38|1@0+ (1,0) [0|1] "" ECM

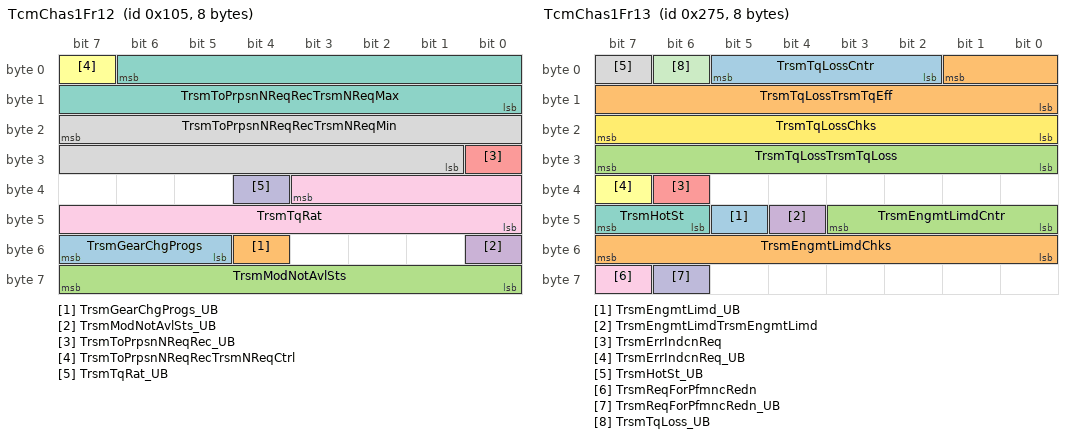
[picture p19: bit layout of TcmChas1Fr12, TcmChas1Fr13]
BO_ 261 TcmChas1Fr12 : 8 TCM
 SG_ TrsmGearChgProgs : 55|3@0+ (1,0) [0|7] "" ECM,VDDM
 SG_ TrsmGearChgProgs_UB : 52|1@0+ (1,0) [0|1] "" ECM,VDDM
 SG_ TrsmModNotAvlSts : 63|8@0+ (1.0,0.0) [0.0|255.0] "Unitless" ECM,VDDM
 SG_ TrsmModNotAvlSts_UB : 48|1@0+ (1,0) [0|1] "" ECM,VDDM
 SG_ TrsmToPrpsnNReqRec_UB : 24|1@0+ (1,0) [0|1] "" ECM
 SG_ TrsmToPrpsnNReqRecTrsmNReqCtrl : 7|1@0+ (1,0) [0|1] "" ECM
 SG_ TrsmToPrpsnNReqRecTrsmNReqMax : 6|15@0+ (0.5,0.0) [0.0|16383.5] "rpm" ECM
 SG_ TrsmToPrpsnNReqRecTrsmNReqMin : 23|15@0+ (0.5,0.0) [0.0|16383.5] "rpm" ECM
 SG_ TrsmTqRat : 35|12@0+ (0.01,0.0) [0.0|40.95] "Unitless" ECM,VDDM
 SG_ TrsmTqRat_UB : 36|1@0+ (1,0) [0|1] "" ECM,VDDM

BO_ 629 TcmChas1Fr13 : 8 TCM
 SG_ TrsmEngmtLimd_UB : 45|1@0+ (1,0) [0|1] "" ECM
 SG_ TrsmEngmtLimdChks : 55|8@0+ (1.0,0.0) [0.0|255.0] "Unitless" ECM
 SG_ TrsmEngmtLimdCntr : 43|4@0+ (1.0,0.0) [0.0|15.0] "Unitless" ECM
 SG_ TrsmEngmtLimdTrsmEngmtLimd : 44|1@0+ (1,0) [0|1] "" ECM
 SG_ TrsmErrIndcnReq : 38|1@0+ (1,0) [0|1] "" ECM,VDDM
 SG_ TrsmErrIndcnReq_UB : 39|1@0+ (1,0) [0|1] "" ECM,VDDM
 SG_ TrsmHotSt : 47|2@0+ (1,0) [0|3] "" ECM,VDDM
 SG_ TrsmHotSt_UB : 7|1@0+ (1,0) [0|1] "" ECM,VDDM
 SG_ TrsmReqForPfmncRedn : 63|1@0+ (1,0) [0|1] "" ECM
 SG_ TrsmReqForPfmncRedn_UB : 62|1@0+ (1,0) [0|1] "" ECM
 SG_ TrsmTqLoss_UB : 6|1@0+ (1,0) [0|1] "" ECM,VDDM
 SG_ TrsmTqLossChks : 23|8@0+ (1.0,0.0) [0.0|255.0] "Unitless" ECM,VDDM
 SG_ TrsmTqLossCntr : 5|4@0+ (1.0,0.0) [0.0|15.0] "Unitless" ECM,VDDM
 SG_ TrsmTqLossTrsmTqEff : 1|10@0+ (0.1,0.0) [0.0|100.0] "%" ECM,VDDM
 SG_ TrsmTqLossTrsmTqLoss : 31|8@0+ (0.5,0.0) [0.0|127.0] "Unitless" ECM,VDDM

// Node Comments
CM_ BU_ ETC "External Tester Connector";
CM_ BU_ PSCM1 "Power Steering Control Module";
CM_ BU_ SAS "Steering Angle Sensor";

// Signal Comments
CM_ SG_ 147 AsyADL3FuncCtrlStsADMod "ADMod";
CM_ SG_ 147 AsyADL3FuncCtrlStsChks "Checksum";
CM_ SG_ 147 AsyADL3FuncCtrlStsCntr "Counter";
CM_ SG_ 147 AsyADL3FuncCtrlStsCtrlSts "CtrlSts";
CM_ SG_ 147 AsyADL3FuncCtrlStsDegraded "Degraded";
CM_ SG_ 147 AsyADL3FuncCtrlStsQf "Qf";
CM_ SG_ 147 AsyADL3FuncCtrlStsSts "Status";
CM_ SG_ 147 AsyADModeReqADActiveReq "ADActiveRequest";
CM_ SG_ 147 AsyADModeReqADDeactiveReq "AD Deactive Request";
CM_ SG_ 147 AsyADModeReqChks "Checksum";
CM_ SG_ 147 AsyADModeReqCntr "Counter";
CM_ SG_ 147 PASFuncActive "Parking function.";
CM_ SG_ 147 RctaBrkReqQM "Indicating RCTA braking is committed.
This signal complies with QM.";
CM_ SG_ 147 RcwmBrkReqQM "Indicating RCW braking request is committed. This signal complies with QM.";
CM_ SG_ 51 AgCtrlTqLowrLim "Lower limit for angle controller torque request.";
CM_ SG_ 51 AgCtrlTqUpprLim "Upper limit for angle controller torque request.";
CM_ SG_ 51 AsyPinionAgReqSafeAsyPinionAgReq "Steering request signal from Active Safety with end-to-end protection ";
CM_ SG_ 51 AsyPinionAgReqSafeAsyPinionAgReqChks "CRC";
CM_ SG_ 51 AsyPinionAgReqSafeAsyPinionAgReqCntr "Counter";
CM_ SG_ 308 BrkWssInfoFrntChks "checksum
";
CM_ SG_ 308 BrkWssInfoFrntCntr "counter";
CM_ SG_ 308 BrkWssInfoFrntTTCFactorFL "Correction factor needed by BBM to calculate Vehicle speed. If VDDM lost, then BBM use the latest value";
CM_ SG_ 308 BrkWssInfoFrntTTCFactorFR "Correction factor needed by BBM to calculate Vehicle speed. If VDDM lost, then BBM use the latest value";
CM_ SG_ 308 BrkWssInfoFrntWssCoreMonRob "wss core monitor";
CM_ SG_ 327 BrkWssInfoReChks "checksum
";
CM_ SG_ 327 BrkWssInfoReCntr "counter";
CM_ SG_ 327 BrkWssInfoReTTCFactorRL "Correction factor needed by BBM to calculate Vehicle speed. If VDDM lost, then BBM use the latest value";
CM_ SG_ 327 BrkWssInfoReTTCFactorRR "Correction factor needed by BBM to calculate Vehicle speed. If VDDM lost, then BBM use the latest value";
CM_ SG_ 327 EpbStsChks "Electrical Park Brake system status information Status for the rear wheel park actuator";
CM_ SG_ 327 EpbStsCntr "Electrical Park Brake system status information Counter for EPB status";
CM_ SG_ 327 EpbStsEpbSts "Electrical Park Brake system status information Status for the rear wheel park actuator";
CM_ SG_ 84 SBMHealthChkCmd "These signals are for BCM  and RBCM handshake during SelfTest, to check RBCM pressure build and valve status on lifecycle.";
CM_ SG_ 129 BrkFActAutParkBrkSpprtReq "AutParkBrkSpprtReq";
CM_ SG_ 129 BrkFActChks "checksum";
CM_ SG_ 129 BrkFActCntr "counter";
CM_ SG_ 129 BrkFActForce "Brake force in Newtons";
CM_ SG_ 129 RbuCtrlModReqSafeBrkSysModCfmd "Mode confirmation";
CM_ SG_ 129 RbuCtrlModReqSafeChks "checksum";
CM_ SG_ 129 RbuCtrlModReqSafeCntr "counter";
CM_ SG_ 265 EpbAvlPrimApplyFunctionalitiesAvailable "apply func available";
CM_ SG_ 265 EpbAvlPrimChks "Checksum";
CM_ SG_ 265 EpbAvlPrimCntr "Counter";
CM_ SG_ 265 EpbAvlPrimDriveAwayIntention "DAR";
CM_ SG_ 265 EpbAvlPrimHostAvailabilityFull "Host availabiltiy full";
CM_ SG_ 265 EpbAvlPrimHostAvailabilityRelOnly "Host availablity relay only";
CM_ SG_ 265 EpbAvlPrimPrimarySystemAvailable "Primary system available ";
CM_ SG_ 265 EpbAvlPrimReserved1 "reserved";
CM_ SG_ 265 EpbAvlPrimReserved2 "reserved";
CM_ SG_ 265 EpbAvlPrimReserved3 "reserved";
CM_ SG_ 265 EpbAvlPrimReserved4 "reserved";
CM_ SG_ 265 EpbAvlPrimRollerTestBench "Rollerbench";
CM_ SG_ 265 PrimBrkSysStBrkSysSt "brake system state";
CM_ SG_ 265 PrimBrkSysStChks "checksum";
CM_ SG_ 265 PrimBrkSysStCntr "counter";
CM_ SG_ 185 ALgtStdFromWhlSpdALgtStdFromWhlSpd "Longitudinal acceleration over ground.
end2endprotection=profile1A dataid= 12345 Longitudinal acceleration over ground";
CM_ SG_ 185 ALgtStdFromWhlSpdChks "Longitudinal acceleration over ground.
end2endprotection=profile1A dataid=12345 Checksum for longitudinal acceleration over ground";
CM_ SG_ 185 ALgtStdFromWhlSpdCntr "Longitudinal acceleration over ground.
end2endprotection=profile1A dataid=12345 Counter for longitudinal acceleration over ground";
CM_ SG_ 185 ALgtStdFromWhlSpdQf "Longitudinal acceleration over ground.
end2endprotection=profile1A dataid=12345 Qf for longitudinal acceleration over ground";
CM_ SG_ 185 SlipRatWithinRngForReWhls "The boolean flag of both rear wheels' slip ratio beyond the calibrated threshold";
CM_ SG_ 134 DrvgCyc " Transition from 0 to 1 indicates a start of a new Driving Cycle.";
CM_ SG_ 544 AccrPedlRatAccrPedlRat "Accelerator Pedal Position with adapted 0 point. Value as percentage of fully pressed pedal";
CM_ SG_ 544 AccrPedlRatChks "Accelerator Pedal Position with adapted 0 point. Value as percentage of fully pressed pedal. Checksum";
CM_ SG_ 544 AccrPedlRatCntr "Accelerator Pedal Position with adapted 0 point. Value as percentage of fully pressed pedal. Counter";
CM_ SG_ 80 EngN2 "Engine Speed [rpm]";
CM_ SG_ 80 PtCluTq2PtCluTq "Crankshaft torque";
CM_ SG_ 80 PtCluTq2PtCluTqQly "Crankshaft torque quality factor";
CM_ SG_ 80 PtCluTq2Req "Requset crank shaft torque";
CM_ SG_ 1111 PtTqAtWhlFrntActChks "checksum";
CM_ SG_ 1111 PtTqAtWhlFrntActCntr "counter";
CM_ SG_ 1111 PtTqAtWhlFrntActPtTqAtAxleFrntAct "Actual torque delivered by the powertrain to the front axle";
CM_ SG_ 1111 PtTqAtWhlFrntActPtTqAtWhlFrntLeAct "Actual torque delivered by the powertrain to the front left wheel.";
CM_ SG_ 1111 PtTqAtWhlFrntActPtTqAtWhlFrntRiAct "Actual torque delivered by the powertrain to the front right wheel.";
CM_ SG_ 1111 PtTqAtWhlFrntActPtTqAtWhlsFrntQly "quality factor";
CM_ SG_ 708 PtVehSpdMaxChks "Checksum of PtVehSpdMax";
CM_ SG_ 708 PtVehSpdMaxCntr "Counter of PtVehSpdMax";
CM_ SG_ 708 PtVehSpdMaxReq " The signal shall limit the vehicle speed for e.g. reverse with electric engine and manipulation of the speed signal.";
CM_ SG_ 730 HvBattPmpStatCooltPmpDryErr "water pump MT Dryrun error";
CM_ SG_ 730 HvBattPmpStatCooltPmpEmgyModSts "water pump MT, Status Emergency mode";
CM_ SG_ 730 HvBattPmpStatCooltPmpErrSts "water pump error status";
CM_ SG_ 730 HvBattPmpStatCooltPmpI "Actual current consumption from battery coolant pump.";
CM_ SG_ 730 HvBattPmpStatCooltPmpIErr "water pump MT current error";
CM_ SG_ 730 HvBattPmpStatCooltPmpMonrSpd "water pump MT, RPM Monitoring";
CM_ SG_ 730 HvBattPmpStatCooltPmpPostRunSts "water pump post run status";
CM_ SG_ 730 HvBattPmpStatCooltPmpSetPostRunReq "water pump set post run speed request";
CM_ SG_ 730 HvBattPmpStatCooltPmpSetSpdReq "Coolant pump set speed request";
CM_ SG_ 730 HvBattPmpStatCooltPmpSpd "Coolant pump actual speed";
CM_ SG_ 730 HvBattPmpStatCooltPmpT "water pump MT Temperature ";
CM_ SG_ 730 HvBattPmpStatCooltPmpTErr "water pump MT temperature error";
CM_ SG_ 730 HvBattPmpStatCooltPmpU "Coolant pump voltage";
CM_ SG_ 730 HvBattPmpStatCooltPmpUErr "water pump MT voltage error";
CM_ SG_ 730 HvBattPmpStatCooltPmpUnstallSts "water pump MT, Deblocking";
CM_ SG_ 859 DispElecPwrAbs "absolutely motor power for display";
CM_ SG_ 859 DispElecPwrSts "status of motor charing o regen.";
CM_ SG_ 871 BookChrgnTarValFb "Feedback the corresponding signal when receives BookChrgnTarVal from TCAM";
CM_ SG_ 871 DchaChrgnTarValFb "Feedback the corresponding signal when receivesDchaChrgnTarVal from TCAM";
CM_ SG_ 871 HvBattPmpCmdCooltPmpPostRunReq "Coolant pump post run request";
CM_ SG_ 871 HvBattPmpCmdCooltPmpSpdReq "Coolant pump speed request";
CM_ SG_ 871 ReEvapVlvReq "Request to open shut off valve of rear evaporator.";
CM_ SG_ 871 RegenAutLvlNotAvlMsg "Regeneration level Auto not avaliable indication";
CM_ SG_ 979 CmprReqCmprSpdReq "AC compressor rotational speed request.";
CM_ SG_ 979 GrlShttrDmdShttrCalEna "AGM shutter calculation enable";
CM_ SG_ 979 GrlShttrDmdShttrPosnReq "AGM shutter position request";
CM_ SG_ 979 HpBattVlvPosSetReq "Battery three-way valve position request.";
CM_ SG_ 1039 EldtPmpCmdCooltPmpPostRunReq "Coolant pump post run request.";
CM_ SG_ 1039 EldtPmpCmdCooltPmpSpdReq "Coolant pump speed request.";
CM_ SG_ 1039 EngCooltPmpSpdReqCooltPmpPostRunReq "Coolant pump post run request";
CM_ SG_ 1039 EngCooltPmpSpdReqCooltPmpSpdReq "Coolant pump speed request.";
CM_ SG_ 563 CmprRunTime "Compressor run time.";
CM_ SG_ 991 FanPwmReqForEldt "Fan pwm request for electric drivetrain.";
CM_ SG_ 991 FanPwrCns "Actual electrical power consumed by the engine cooling fan.";
CM_ SG_ 304 CnvnAllwd "Intelligent charging allow status. 0 = NOK Or 1 = OK";
CM_ SG_ 304 EngNSafeEngN "Engine Speed [rpm] and Engine Speed derivative [rpm/s]";
CM_ SG_ 304 EngNSafeEngNChks "Engine Speed [rpm] and Engine Speed derivative [rpm/s]";
CM_ SG_ 304 EngNSafeEngNCntr "Engine Speed [rpm] and Engine Speed derivative [rpm/s]";
CM_ SG_ 304 EngNSafeEngNGrdt "Engine Speed [rpm] and Engine Speed derivative [rpm/s]";
CM_ SG_ 1135 BattCooltIndcnReq "Battery coolant level indication request";
CM_ SG_ 1135 CooltFlowInCmptmtCirc "Informs of coolant flow in the heat exchange. Created for the short coolant circuit in hybrid cars.";
CM_ SG_ 1135 EngTRefSts "Status bit array to indicate which sensors are used for the calculation of EngTRefT1 and EngTRefT2.";
CM_ SG_ 1135 EngTRefT1 "The lowest of the two reference temperatures that may be used for offset low diagnostics of temperatures in the TCM.";
CM_ SG_ 1135 EngTRefT2 "The highest of the two reference temperatures that may be used for offset low diagnostics of temperatures in the TCM.";
CM_ SG_ 1135 TelltlPwrLoss "Power loss dection ,which is used to indicate the DIM(turtle indicator)";
CM_ SG_ 576 HvBattPmpPwrCns "Coolant pump power consumption in battery cooling circuit.";
CM_ SG_ 576 PostHeatgRunTiEstimd "Estimated heating afterrun time.";
CM_ SG_ 455 AccrpedlStsChks " It should provide acceleration pedal Status signal ( AccrpedlSts ) to predict whether the accelerator pedal  has fault or not.1-Fault; 0-NoFault";
CM_ SG_ 455 AccrpedlStsCntr " It should provide acceleration pedal Status signal ( AccrpedlSts ) to predict whether the accelerator pedal  has fault or not.1-Fault; 0-NoFault";
CM_ SG_ 455 AccrpedlStsFltSts " It should provide acceleration pedal Status signal ( AccrpedlSts ) to predict whether the accelerator pedal  has fault or not.1-Fault; 0-NoFault";
CM_ SG_ 455 HvActvSts "Indicate HV avtivation status.";
CM_ SG_ 587 AirTFromHeatgEstimd "Estimated air temperature from heater.";
CM_ SG_ 587 CchForPwrEcoBarForPwrEco "Eco Coach data, both calculated instantaneous and grade eco coach data.";
CM_ SG_ 587 CchForPwrEcoGrdForPwrEco "Eco Coach data, both calculated instantaneous and grade eco coach data.";
CM_ SG_ 543 AcCmprVlvICns "Ac variable displacement valve current consumption.";
CM_ SG_ 543 GearMov "To indicate the case that if any one of gear lever, shifting fork, gear lock button, P-button is intervened when vehicle enter APA/RPA mode
YesYesNoUnknown,
0=YesYesNoUnknown_No
1=YesYesNoUnknown_YesNo
2=YesYesNoUnknown_Unknown
3=YesYesNoUnknown_YesYes";
CM_ SG_ 609 EldtPmpPwrCns "Coolant pump power consumption in ELDT cooling circuit.";
CM_ SG_ 609 EngCooltFlwAct "Engine actual coolant flow.";
CM_ SG_ 609 EngCooltPmpPwrCns "Actual electrical power consumed by engine water pump.";
CM_ SG_ 632 ChrgnSpd "Charging speed indication to driver in kph.";
CM_ SG_ 642 HpBattVlvPosRec "Battery three-way valve opening  position in percentage.";
CM_ SG_ 642 HvBattSocEngStart "Low SOC engine start point in HEV drive mode.";
CM_ SG_ 131 EngSt1WdStsChks "checksum";
CM_ SG_ 131 EngSt1WdStsCntr "counter";
CM_ SG_ 131 EngSt1WdStsEngSt1WdSts "Signaling the state of the powerpack";
CM_ SG_ 752 DrvrGearLvrInfoIndcn "Indicates to the driver why the gear lever information is change.";
CM_ SG_ 752 EngSt1WdSts1 "Signaling the state of the powerpack(without E2E)";
CM_ SG_ 1157 AutoShowModPrpsnEna "show car mode propultion enable conditon";
CM_ SG_ 1158 CooltFlowForTOC "estimated coolant flow of TOC circuit";
CM_ SG_ 1158 CooltTSigForTOC "coolant temperature of TOC circuit radiator outlet measured by sensor";
CM_ SG_ 837 DstEstimdToEmptyForDrvgElecPredTyp2 "Predicted distance till empty in economic driving behavior of type 2.";
CM_ SG_ 913 DispIdlChrgPwr "Charging power idle charging";
CM_ SG_ 135 Mot1ReqSafeChks "Checksum";
CM_ SG_ 135 Mot1ReqSafeCntr "Rolling Counter";
CM_ SG_ 135 Mot1ReqSafemod "P1 mode request";
CM_ SG_ 135 Mot1ReqSafeRsv "Reserved for FuSa";
CM_ SG_ 135 Mot1ReqSafespd "P1 speed  request";
CM_ SG_ 135 Mot1ReqSafetq "P1 torque  request";
CM_ SG_ 135 PtGearActrAdpnCmd3DHT "Gear actuator adaption allowed";
CM_ SG_ 135 PtGearActtnAllwdStsDHT "Gear action allowed status";
CM_ SG_ 135 PtRotReqAckd "Antibalking rotation performed";
CM_ SG_ 121 EngPAmbAir "Ambient pressure";
CM_ SG_ 121 Mot3ReqSafeChks "Checksum";
CM_ SG_ 121 Mot3ReqSafeCntr "Rolling Counter";
CM_ SG_ 121 Mot3ReqSafemod "P3 mode request";
CM_ SG_ 121 Mot3ReqSafeRsv "Reserved for FuSa";
CM_ SG_ 121 Mot3ReqSafespd "P3 speed  request";
CM_ SG_ 121 Mot3ReqSafetq "P3 torque  request";
CM_ SG_ 113 ElecMot2ModReq "Generator motor operation mode request
1: standby
2: torque control
3: speed control
4: UDC control
5: Speed Control Dead Zone";
CM_ SG_ 113 ElecMot2SpdReq "Generator motor speed request";
CM_ SG_ 113 ElecMot2TqReq "Generator motor torque request";
CM_ SG_ 113 EngageFastReq "Drivetrain engagement fast request";
CM_ SG_ 113 WhlTqTarOfDrvMot "Wheel torque request distributed to P2 motor";
CM_ SG_ 118 PtClu0TqReq "Clutch C0 torque request (Unit: Nm)";
CM_ SG_ 118 PtCluSlipCmdOfClu0 "Clutch C0 mode request, Reserve for other cases, current only used for Tip in C0 slip";
CM_ SG_ 118 PtCluSlipTarReqOfClu0 "Clutch C0 slip target request (Unit: rpm)";
CM_ SG_ 118 PtDtModReq "Drivetrain mode request(EV/Serial/Parallel)";
CM_ SG_ 118 PtEngTqAct "Engine Net torque actual without P1";
CM_ SG_ 118 PtGearTarReq "DHT Gear target request";
CM_ SG_ 118 PtWhlTqTar "Powertrain final torque request on the wheel";
CM_ SG_ 133 EngTqCpMax "Engine max torque capacity";
CM_ SG_ 133 EngTqCpMin "Engine min torque capacity";
CM_ SG_ 1431 PSCMdevelpsignalgroupreq1Functiondevpsignalgroup1 "develop signal group request";
CM_ SG_ 1431 PSCMdevelpsignalgroupreq1Functiondevpsignalgroup2 "develop signal group request";
CM_ SG_ 1431 PSCMdevelpsignalgroupreq1Functiondevpsignalgroup3 "develop signal group request";
CM_ SG_ 1431 PSCMdevelpsignalgroupreq1Functiondevpsignalgroup4 "develop signal group request";
CM_ SG_ 1431 PSCMdevelpsignalgroupreq1Functiondevpsignalgroup5 "develop signal group request";
CM_ SG_ 1431 PSCMdevelpsignalgroupreq1Functiondevpsignalgroup6 "develop signal group request";
CM_ SG_ 1431 PSCMdevelpsignalgroupreq1Functiondevpsignalgroup7 "develop signal group request";
CM_ SG_ 1431 PSCMdevelpsignalgroupreq1Functiondevpsignalgroup8 "develop signal group request";
CM_ SG_ 1504 RBCMdevelpsignalgroupreq1Functiondevpsignalgroup1 "RBCM development signal";
CM_ SG_ 1504 RBCMdevelpsignalgroupreq1Functiondevpsignalgroup2 "RBCM development signal";
CM_ SG_ 1504 RBCMdevelpsignalgroupreq1Functiondevpsignalgroup3 "RBCM development signal";
CM_ SG_ 1504 RBCMdevelpsignalgroupreq1Functiondevpsignalgroup4 "RBCM development signal";
CM_ SG_ 1504 RBCMdevelpsignalgroupreq1Functiondevpsignalgroup5 "RBCM development signal";
CM_ SG_ 1504 RBCMdevelpsignalgroupreq1Functiondevpsignalgroup6 "RBCM development signal";
CM_ SG_ 1504 RBCMdevelpsignalgroupreq1Functiondevpsignalgroup7 "RBCM development signal";
CM_ SG_ 1504 RBCMdevelpsignalgroupreq1Functiondevpsignalgroup8 "RBCM development signal";
CM_ SG_ 1432 VDDMdevelpsignalgroupreq1Functiondevpsignalgroup1 "develop signal group request";
CM_ SG_ 1432 VDDMdevelpsignalgroupreq1Functiondevpsignalgroup2 "develop signal group request";
CM_ SG_ 1432 VDDMdevelpsignalgroupreq1Functiondevpsignalgroup3 "develop signal group request";
CM_ SG_ 1432 VDDMdevelpsignalgroupreq1Functiondevpsignalgroup4 "develop signal group request";
CM_ SG_ 1432 VDDMdevelpsignalgroupreq1Functiondevpsignalgroup5 "develop signal group request";
CM_ SG_ 1432 VDDMdevelpsignalgroupreq1Functiondevpsignalgroup6 "develop signal group request";
CM_ SG_ 1432 VDDMdevelpsignalgroupreq1Functiondevpsignalgroup7 "develop signal group request";
CM_ SG_ 1432 VDDMdevelpsignalgroupreq1Functiondevpsignalgroup8 "develop signal group request";
CM_ SG_ 1433 VDDMdevelpsignalgroupreq2Functiondevpsignalgroup1 "VDDM development signal";
CM_ SG_ 1433 VDDMdevelpsignalgroupreq2Functiondevpsignalgroup2 "VDDM development signal";
CM_ SG_ 1433 VDDMdevelpsignalgroupreq2Functiondevpsignalgroup3 "VDDM development signal";
CM_ SG_ 1433 VDDMdevelpsignalgroupreq2Functiondevpsignalgroup4 "VDDM development signal";
CM_ SG_ 1433 VDDMdevelpsignalgroupreq2Functiondevpsignalgroup5 "VDDM development signal";
CM_ SG_ 1433 VDDMdevelpsignalgroupreq2Functiondevpsignalgroup6 "VDDM development signal";
CM_ SG_ 1433 VDDMdevelpsignalgroupreq2Functiondevpsignalgroup7 "VDDM development signal";
CM_ SG_ 1433 VDDMdevelpsignalgroupreq2Functiondevpsignalgroup8 "VDDM development signal";
CM_ SG_ 235 PrkgPinionAgReqGroupParkAssiPinionAgReq "The requested steering pinion angle by the autonomous parking system.";
CM_ SG_ 235 PrkgPinionAgReqGroupParkAssiPinionAgReqChks "counter,For E2E Protection";
CM_ SG_ 235 PrkgPinionAgReqGroupParkAssiPinionAgReqCntr "CRC,to check the signal,For E2E Protection";
CM_ SG_ 235 PrkgPinionAgReqGroupQF "QF";
CM_ SG_ 149 PrkgGearReqGroupChks "counter";
CM_ SG_ 149 PrkgGearReqGroupCntr "checksum";
CM_ SG_ 149 PrkgGearReqGroupReqSts1 "After selecting the RPA and before the handshake is successful, the PAS requests to suspend the P file to pull up the EPB";
CM_ SG_ 65 ElecMot2ModSts "Inverter mode status";
CM_ SG_ 65 ElecMot2SpdActSgn "Actual auxiliary motor speed with sign to indicate forward or backward direction";
CM_ SG_ 65 GaGearAct "Actual gear for DHT Everest";
CM_ SG_ 65 TrsmCluSlipStsOfClu0 "Transmission cluch slip actual status of C0";
CM_ SG_ 65 TrsmCluTqActOfClu0 "Clutch torque  actual  of clutch 0";
CM_ SG_ 65 TrsmDtModAct "the actual mode of the drivetrain";
CM_ SG_ 65 TrsmModShiftActv "Mode Shift Active";
CM_ SG_ 136 EngTqIntvReqFast "Engine torque intervention request fast";
CM_ SG_ 136 EngTqIntvReqSlow "Engine torque intervention request slow";
CM_ SG_ 136 TrsmOutpNChks "Checksum";
CM_ SG_ 136 TrsmOutpNCntr "rolling counter";
CM_ SG_ 136 TrsmOutpNDir "Transmission outputshaft direction 0 is the forward direction";
CM_ SG_ 136 TrsmOutpNSpd "Tansmission output shaft speed";
CM_ SG_ 136 TrsmOutpNSpdQf "Transmission outputshaft speed signal quality factor";
CM_ SG_ 262 TrsmClu0FltIndcn "Shall include the corresponding C0 fault message";
CM_ SG_ 262 TrsmClu0StsChks "Shall include the corresponding status of Clutch 0";
CM_ SG_ 262 TrsmClu0StsCntr "Shall include the corresponding status of Clutch 0";
CM_ SG_ 262 TrsmClu0StsTrsm0CluSts "Shall include the corresponding status of Clutch 0";
CM_ SG_ 262 TrsmCluTqCpMaxOfClu0 "Clutch capacity max of clutch 0";
CM_ SG_ 262 TrsmGearActrScanForRefActv3DHT "Gear actuator adaption active";
CM_ SG_ 262 TrsmGearActrScanForRefReq3DHT "Gear actuator adaption request";
CM_ SG_ 262 TrsmGearEngmtSts "Transmission gear engaging management status";
CM_ SG_ 262 TrsmParkLockSt "Transmission park lock state";
CM_ SG_ 262 TrsmRotReq "antibalking request";
CM_ SG_ 262 TrsmWhlProtnMaxTq "Transmission  wheel protection max  torque";
CM_ SG_ 1142 TOCCooltFlowReq "coolant flow requirement for TOC";
CM_ SG_ 83 DHTStSafeChks "Chechsum";
CM_ SG_ 83 DHTStSafeCntr "Rolling Counter";
CM_ SG_ 83 DHTStSafeRsv "Reserved for FuSa";
CM_ SG_ 83 DHTStSafeSpd "P1 actual speed";
CM_ SG_ 83 DHTStSafeSpdQf "P1 actual speed quality factor";
CM_ SG_ 83 DHTStSafeTqRt "Actual gear ratio";
CM_ SG_ 83 DHTStSafeTqRtQf "Actual gear ratio quality factor";
CM_ SG_ 246 DrvrSteerActvChks "Confirmation of driver steer actively Checksum";
CM_ SG_ 246 DrvrSteerActvCntr "Confirmation of driver steer actively Counter";
CM_ SG_ 246 DrvrSteerActvDrvrSteerActv "Indicates if the driver steers actively";
CM_ SG_ 246 FrntSteerFEstimd1 "FrntSteerFEstimd1 (Front Steer Force Estimated) provides estimates of the front steering rack force.";
CM_ SG_ 246 UBoostReqBySteerFrnt "UBoosReqBySteerFrnt is sent to the Electrical Management subsystem to request that sufficient electrical power is prodived for the steering system during special driving situations, e.g. parking manouvers.";
CM_ SG_ 70 LatCtrlModCfmdChks "Confirmation of lateral control request Confirmed lateral mode";
CM_ SG_ 70 LatCtrlModCfmdCntr "Confirmation of lateral control request Confirmed lateral mode";
CM_ SG_ 70 LatCtrlModCfmdLatCtrlMod "Confirmation of lateral control request Confirmed lateral mode";
CM_ SG_ 70 SteerServoSts "Status of lateral control request";
CM_ SG_ 70 SteerWhlTqAddl "Overlay torque from external requests";
CM_ SG_ 70 TqAssAddl "Total torque at motor";
CM_ SG_ 444 DrvrSteerWhlHldGroupDrvrSteerWhlHld "Hands on steering wheel information. Signal indicating whether the driver has his hands on the steering wheel or not.";
CM_ SG_ 444 DrvrSteerWhlHldGroupDrvrSteerWhlHldQly "Hands on steering wheel information. Confidence value for the DrvrSteerWhlHld estimation calculation, specifically indicating the confidence for the hands off state.";
CM_ SG_ 444 SteerErrReq "Sent from steering system to display to notify driver if no steering torque assist is available. Messages sent from Steering system to DIM";
CM_ SG_ 444 SteerExtFctStsChks "Confirmation of steer external function status Checksum";
CM_ SG_ 444 SteerExtFctStsCntr "Confirmation of steer external function status Counter";
CM_ SG_ 444 SteerExtFctStsDrvrSteerOvrd "Steering request of asking driver to take over";
CM_ SG_ 444 SteerExtFctStsExtFctLowerLimActive "Column  Torque Lower Limit ";
CM_ SG_ 444 SteerExtFctStsExtFctRateLimActive "External function rate Limit ";
CM_ SG_ 444 SteerExtFctStsExtFctUpperLimActive "Column Torque Upper Limit ";
CM_ SG_ 444 SteerExtFctStsExtSafeLimActive "External function torque output vs defined safety limiters ";
CM_ SG_ 444 SteerExtFctStsLatAgReqNotInRange "Pinion angle /current trajectory between primary and fall back ";
CM_ SG_ 444 SteerExtFctStsLatCtrlReqNotInRange "Lateral Ctrl request and primary and fall back ";
CM_ SG_ 444 SteerStsToParkAssi "SteerStsToParkAssi contains PSCM status related to execution of SAP.";
CM_ SG_ 955 PinionSteerAgMax1 "PinionSteerAgMax1 contains the current maximal pinion angle. Depends on tire size and vehicle type.";
CM_ SG_ 78 PinionSteerAgGroupChks "Checksum for PinionSteerAgGroup";
CM_ SG_ 78 PinionSteerAgGroupCntr "Counter for PinionSteerAgGroup";
CM_ SG_ 78 PinionSteerAgGroupPinionSteerAg1 "Calculated pinion steer angle at the front steering device";
CM_ SG_ 78 PinionSteerAgGroupPinionSteerAg1Qf "Quality factor for PinionSteerAg1";
CM_ SG_ 78 PinionSteerAgGroupPinionSteerAgSpd1 "Calculated pinion steer angle speed at the front steering device ";
CM_ SG_ 78 PinionSteerAgGroupPinionSteerAgSpd1Qf "Quality factor for PinionSteerAgSpd1";
CM_ SG_ 78 PinionSteerAgGroupSteerWhlTq "Torque on steering wheel";
CM_ SG_ 78 PinionSteerAgGroupSteerWhlTqQf "Quality factor for SteerWhlTq";
CM_ SG_ 1430 PSCMdevelpsignalgroupresp1Functiondevpsignalgroup1 "PSCM development signal";
CM_ SG_ 1430 PSCMdevelpsignalgroupresp1Functiondevpsignalgroup2 "PSCM development signal";
CM_ SG_ 1430 PSCMdevelpsignalgroupresp1Functiondevpsignalgroup3 "PSCM development signal";
CM_ SG_ 1430 PSCMdevelpsignalgroupresp1Functiondevpsignalgroup4 "PSCM development signal";
CM_ SG_ 1430 PSCMdevelpsignalgroupresp1Functiondevpsignalgroup5 "PSCM development signal";
CM_ SG_ 1430 PSCMdevelpsignalgroupresp1Functiondevpsignalgroup6 "PSCM development signal";
CM_ SG_ 1430 PSCMdevelpsignalgroupresp1Functiondevpsignalgroup7 "PSCM development signal";
CM_ SG_ 1430 PSCMdevelpsignalgroupresp1Functiondevpsignalgroup8 "PSCM development signal";
CM_ SG_ 64 SteerWhlSnsrAg "Actual steering wheel angle from the actual centre position of the steering wheel. ";
CM_ SG_ 64 SteerWhlSnsrAgSpd "Actual steering wheel angle from the actual centre position of the steering wheel. Steering angle speed with steering wheel rotation direction.  ";
CM_ SG_ 64 SteerWhlSnsrChks "Checksum for steering wheel sensor data.";
CM_ SG_ 64 SteerWhlSnsrCntr "Counter value for steering wheel sensor data.";
CM_ SG_ 64 SteerWhlSnsrQf "Qf for steering wheel sensor information";
CM_ SG_ 128 TrsmActrPosn2TrsmActrPosn "Describes the transmission position (P, R, N, D). Can also take intermediate positions (PR, RN, ND). If error are detected on position sensors undefined is set. Transmission measured gear lever position";
CM_ SG_ 128 TrsmActrPosn2TrsmActrPosnChks "E2E checksum";
CM_ SG_ 128 TrsmActrPosn2TrsmActrPosnCntr "Data counter";
CM_ SG_ 128 TrsmGearActSafeChks "Transmission Gear Actual. Actual gear engaged sent by transmission supplier.";
CM_ SG_ 128 TrsmGearActSafeCntr "Transmission Gear Actual. Actual gear engaged sent by transmission supplier.";
CM_ SG_ 128 TrsmGearActSafeTrsmGearActSafe "Transmission Gear Actual. Actual gear engaged sent by transmission supplier.";
CM_ SG_ 512 TrsmClrRdyReq "TrsmClrRdyReq";
CM_ SG_ 512 TrsmCluTEstimdOfClu0 "Clutch C0 temperature";
CM_ SG_ 261 TrsmGearChgProgs "Transmission gear change in progress. Transmission supplier sent signal containing informatoin regarding which phase the gear shift is in. 0 - not changing gear, 1 - start phase, 2 - tourqe phase, 3 - inertia phase, 4 - end phase.";
CM_ SG_ 261 TrsmModNotAvlSts "TCM uses signal Transmissions Mode Not Available Status to inform ECM which modes are unavailable (Neutral, Reverse, Drive, LockUp stuck-Off or LockUp stuck-On). Default value - 0 (no modes unavailable). Bit 0-7";
CM_ SG_ 261 TrsmToPrpsnNReqRecTrsmNReqCtrl "Transmission To Propulsion eNgine speed Request Record. Unit: Rpm";
CM_ SG_ 261 TrsmToPrpsnNReqRecTrsmNReqMax "Transmission To Propulsion eNgine speed Request Record. Unit: Rpm";
CM_ SG_ 261 TrsmToPrpsnNReqRecTrsmNReqMin "Transmission To Propulsion eNgine speed Request Record. Unit: Rpm";
CM_ SG_ 261 TrsmTqRat "Transmission Torque Ratio. Actual ratio between the input and the output torque of the transmission and torque converter This includes torque converter effects, clutch slip effects, and all gearing effects including final drive.";
CM_ SG_ 629 TrsmEngmtLimdChks "Reports if the gearbox is in a state with limited ability to transfer torque., e.g. engine standing still with open lockup.";
CM_ SG_ 629 TrsmEngmtLimdCntr "Reports if the gearbox is in a state with limited ability to transfer torque., e.g. engine standing still with open lockup.";
CM_ SG_ 629 TrsmEngmtLimdTrsmEngmtLimd "Reports if the gearbox is in a state with limited ability to transfer torque., e.g. engine standing still with open lockup.";
CM_ SG_ 629 TrsmErrIndcnReq "TCM uses signal Transmission Error Indication Request to send a MIL-request to ECM. ECM will then act upon this request and iluminate the MIL. For VEP software, TCM transmits signal after two consecutive failed driving cycles (for a MIL-relevant code). Default value - 0 (Off)";
CM_ SG_ 629 TrsmHotSt "Transmission hot state. Indicate transmission is in hot state. 0 - Not in hot state, 1 - Hot state level 1, 2 - Hot state level 2.";
CM_ SG_ 629 TrsmReqForPfmncRedn "TCM uses signal Transmission Request For Performance Reduction to send requests to ECM to activate the functionality Intended System Degradation (ISD). ISD will stage by stage reduce the maximum allowed torque for the engine over a number of driving cycles. Default signal - 0 (false).";
CM_ SG_ 629 TrsmTqLossChks "Actual torque losses in the transmission";
CM_ SG_ 629 TrsmTqLossCntr "Actual torque losses in the transmission";
CM_ SG_ 629 TrsmTqLossTrsmTqEff "Actual torque losses in the transmission";
CM_ SG_ 629 TrsmTqLossTrsmTqLoss "Actual torque losses in the transmission";

// Attribute definitions
BA_DEF_  "Baudrate" INT 1000 1000000; // [bps]
BA_DEF_  "BusType" STRING;
BA_DEF_  "DBName" STRING;
BA_DEF_  "ProtocolType" STRING;
BA_DEF_ BU_ "NmAsrNode" ENUM "No","Yes";
BA_DEF_ BU_ "NmAsrNodeIdentifier" INT 0 255;
BA_DEF_ BO_ "GenMsgCycleTime" INT 0 65536; // [ms]
BA_DEF_ BO_ "GenMsgDelayTime" INT 0 65536; // [ms]
BA_DEF_ BO_ "GenMsgSendType" ENUM "cyclic", "spontaneous", "not-used", "not-used", "not-used", "cyclicAndSpontaneous", "not-used", "cyclicIfActive", "NoMsgSendType"; // [us]
BA_DEF_ BO_ "GenMsgStartDelayTime" INT 0 65536; // [ms]
BA_DEF_ SG_ "GenSigSendType" ENUM "Cyclic","OnWrite","OnWriteWithRepetition","OnChange","OnChangeWithRepetition","IfActive","IfActiveWithRepetition","NoSigSendType";
BA_DEF_ SG_ "GenSigStartValue" HEX 0 80000000;
BA_DEF_ BO_ "GenMsgILSupport" ENUM "No","Yes";
BA_DEF_ BO_ "NmAsrMessage" ENUM "No","Yes";
BA_DEF_  "NmAsrBaseAddress" HEX 0 536870911;
BA_DEF_  "NmAsrMessageCount" INT 0 255;
BA_DEF_ BU_ "NodeLayerModules" STRING;
BA_DEF_ BU_ "ILused" ENUM "No","Yes";
BA_DEF_ SG_ "GenSigFuncType" ENUM "NoFunction","n/a","n/a","n/a","n/a","n/a","n/a","n/a","n/a","n/a","n/a","n/a","n/a","n/a","n/a","CHK","CNTR","n/a","n/a","n/a","CNTR_AR_01","CRC_AR_01_BOTH","CRC_AR_01_ALT","CRC_AR_01_LOW","CRC_AR_01_NIBBLE","CNTR_AR_04","CRC_AR_04A","CNTR_AR_05","CRC_AR_05";
BA_DEF_ SG_ "GenSigDataID" STRING;

BA_DEF_DEF_ "BusType" "";
BA_DEF_DEF_ "DBName" "";
BA_DEF_DEF_ "ProtocolType" "";
BA_DEF_DEF_ "NmAsrNode" "No";
BA_DEF_DEF_ "NmAsrNodeIdentifier" 0;
BA_DEF_DEF_ "GenSigStartValue" 0;
BA_DEF_DEF_ "GenSigSendType" "NoSigSendType";
BA_DEF_DEF_ "GenMsgCycleTime" 0;
BA_DEF_DEF_ "GenMsgDelayTime" 0;
BA_DEF_DEF_ "GenMsgStartDelayTime" 0;
BA_DEF_DEF_ "GenMsgSendType" "NoMsgSendType";
BA_DEF_DEF_ "GenMsgILSupport" "Yes";
BA_DEF_DEF_ "NmAsrMessage" "No";
BA_DEF_DEF_ "NmAsrBaseAddress" 1280;
BA_DEF_DEF_ "NmAsrMessageCount" 64;
BA_DEF_DEF_ "NodeLayerModules" "CANoeILNLSPA.dll";
BA_DEF_DEF_ "ILused" "Yes";
BA_DEF_DEF_ "GenSigFuncType" "NoFunction";
BA_DEF_DEF_ "GenSigDataID" "";

BA_ "Baudrate" 500000;
BA_ "BusType" "CAN";
BA_ "DBName" "ChassisCAN1";
BA_ "ProtocolType" "CAN";
// Network
// ECU: ASDM
BA_ "NmAsrNode" BU_ ASDM 1;
BA_ "NmAsrNodeIdentifier" BU_ ASDM 41;
BA_ "NodeLayerModules" BU_ ASDM "CANoeILNLSPA.dll,AsrNM33.dll";
// ECU: BBM
BA_ "NmAsrNode" BU_ BBM 1;
BA_ "NmAsrNodeIdentifier" BU_ BBM 54;
BA_ "NodeLayerModules" BU_ BBM "CANoeILNLSPA.dll,AsrNM33.dll";
// ECU: ECM
BA_ "NmAsrNode" BU_ ECM 1;
BA_ "NmAsrNodeIdentifier" BU_ ECM 16;
BA_ "NodeLayerModules" BU_ ECM "CANoeILNLSPA.dll,AsrNM33.dll";
// ECU: ETC
BA_ "ILused" BU_ ETC 0;
// ECU: PSCM1
BA_ "NmAsrNode" BU_ PSCM1 1;
BA_ "NmAsrNodeIdentifier" BU_ PSCM1 35;
BA_ "NodeLayerModules" BU_ PSCM1 "CANoeILNLSPA.dll,AsrNM33.dll";
// ECU: SAS
BA_ "NmAsrNode" BU_ SAS 1;
BA_ "NmAsrNodeIdentifier" BU_ SAS 39;
BA_ "NodeLayerModules" BU_ SAS "CANoeILNLSPA.dll,AsrNM33.dll";
// ECU: TCM
BA_ "NmAsrNode" BU_ TCM 1;
BA_ "NmAsrNodeIdentifier" BU_ TCM 48;
BA_ "NodeLayerModules" BU_ TCM "CANoeILNLSPA.dll,AsrNM33.dll";
// ECU: VDDM
BA_ "NmAsrNode" BU_ VDDM 1;
BA_ "NmAsrNodeIdentifier" BU_ VDDM 33;
BA_ "NodeLayerModules" BU_ VDDM "CANoeILNLSPA.dll,AsrNM33.dll";
// Frame: AsdmChas1Fr01
BA_ "GenMsgCycleTime" BO_ 147 20.000;
BA_ "GenMsgSendType" BO_ 147 0;
// Frame: AsdmChas1Fr03
BA_ "GenMsgCycleTime" BO_ 51 10.000;
BA_ "GenMsgSendType" BO_ 51 0;
// Frame: AsdmChas1NMFr
BA_ "GenMsgDelayTime" BO_ 1321 20.000;
BA_ "GenMsgSendType" BO_ 1321 1;
// Frame: BcmChas1Fr01
BA_ "GenMsgCycleTime" BO_ 308 50.000;
BA_ "GenMsgSendType" BO_ 308 0;
// Frame: BcmChas1Fr02
BA_ "GenMsgCycleTime" BO_ 327 50.000;
BA_ "GenMsgSendType" BO_ 327 0;
// Frame: BcmChas1Fr03
BA_ "GenMsgCycleTime" BO_ 84 10.000;
BA_ "GenMsgSendType" BO_ 84 0;
// Frame: BcmChas1Fr06
BA_ "GenMsgCycleTime" BO_ 129 10.000;
BA_ "GenMsgSendType" BO_ 129 0;
// Frame: BcmChas1Fr07
BA_ "GenMsgCycleTime" BO_ 265 20.000;
BA_ "GenMsgSendType" BO_ 265 0;
// Frame: BcmChas1Fr09
BA_ "GenMsgCycleTime" BO_ 185 20.000;
BA_ "GenMsgSendType" BO_ 185 0;
// Frame: BcmChas1NMFr
BA_ "GenMsgDelayTime" BO_ 1334 20.000;
BA_ "GenMsgSendType" BO_ 1334 1;
// Frame: EcmChas1BsgFr40
BA_ "GenMsgCycleTime" BO_ 134 50.000;
BA_ "GenMsgSendType" BO_ 134 0;
// Frame: EcmChas1BsgFr41
BA_ "GenMsgCycleTime" BO_ 544 100.000;
BA_ "GenMsgSendType" BO_ 544 0;
// Frame: EcmChas1Fr04
BA_ "GenMsgCycleTime" BO_ 80 10.000;
BA_ "GenMsgSendType" BO_ 80 0;
// Frame: EcmChas1Fr08
BA_ "GenMsgCycleTime" BO_ 1111 50.000;
BA_ "GenMsgSendType" BO_ 1111 0;
// Frame: EcmChas1Fr09
BA_ "GenMsgCycleTime" BO_ 708 130.000;
BA_ "GenMsgSendType" BO_ 708 0;
// Frame: EcmChas1Fr11
BA_ "GenMsgCycleTime" BO_ 730 130.000;
BA_ "GenMsgSendType" BO_ 730 0;
// Frame: EcmChas1Fr12
BA_ "GenMsgCycleTime" BO_ 859 170.000;
BA_ "GenMsgSendType" BO_ 859 0;
// Frame: EcmChas1Fr13
BA_ "GenMsgCycleTime" BO_ 871 200.000;
BA_ "GenMsgSendType" BO_ 871 0;
// Frame: EcmChas1Fr16
BA_ "GenMsgCycleTime" BO_ 979 260.000;
BA_ "GenMsgSendType" BO_ 979 0;
// Frame: EcmChas1Fr17
BA_ "GenMsgCycleTime" BO_ 1039 300.000;
BA_ "GenMsgSendType" BO_ 1039 0;
// Frame: EcmChas1Fr18
BA_ "GenMsgCycleTime" BO_ 563 100.000;
BA_ "GenMsgSendType" BO_ 563 0;
// Frame: EcmChas1Fr19
BA_ "GenMsgCycleTime" BO_ 991 270.000;
BA_ "GenMsgSendType" BO_ 991 0;
// Frame: EcmChas1Fr21
BA_ "GenMsgCycleTime" BO_ 304 25.000;
BA_ "GenMsgSendType" BO_ 304 0;
// Frame: EcmChas1Fr22
BA_ "GenMsgCycleTime" BO_ 1135 400.000;
BA_ "GenMsgSendType" BO_ 1135 0;
// Frame: EcmChas1Fr23
BA_ "GenMsgCycleTime" BO_ 576 800.000;
BA_ "GenMsgSendType" BO_ 576 0;
// Frame: EcmChas1Fr24
BA_ "GenMsgCycleTime" BO_ 455 30.000;
BA_ "GenMsgSendType" BO_ 455 0;
// Frame: EcmChas1Fr25
BA_ "GenMsgCycleTime" BO_ 587 100.000;
BA_ "GenMsgSendType" BO_ 587 0;
// Frame: EcmChas1Fr26
BA_ "GenMsgCycleTime" BO_ 543 40.000;
BA_ "GenMsgSendType" BO_ 543 0;
// Frame: EcmChas1Fr27
BA_ "GenMsgCycleTime" BO_ 609 100.000;
BA_ "GenMsgSendType" BO_ 609 0;
// Frame: EcmChas1Fr29
BA_ "GenMsgCycleTime" BO_ 632 100.000;
BA_ "GenMsgSendType" BO_ 632 0;
// Frame: EcmChas1Fr30
BA_ "GenMsgCycleTime" BO_ 642 100.000;
BA_ "GenMsgSendType" BO_ 642 0;
// Frame: EcmChas1Fr31
BA_ "GenMsgCycleTime" BO_ 131 10.000;
BA_ "GenMsgSendType" BO_ 131 0;
// Frame: EcmChas1Fr37
BA_ "GenMsgCycleTime" BO_ 752 80.000;
BA_ "GenMsgSendType" BO_ 752 0;
// Frame: EcmChas1Fr38
BA_ "GenMsgCycleTime" BO_ 1157 1000.000;
BA_ "GenMsgSendType" BO_ 1157 0;
// Frame: EcmChas1Fr39
BA_ "GenMsgCycleTime" BO_ 1158 1000.000;
BA_ "GenMsgSendType" BO_ 1158 0;
// Frame: EcmChas1Fr42
BA_ "GenMsgCycleTime" BO_ 837 260.000;
BA_ "GenMsgSendType" BO_ 837 0;
// Frame: EcmChas1Fr48
BA_ "GenMsgCycleTime" BO_ 913 400.000;
BA_ "GenMsgSendType" BO_ 913 0;
// Frame: EcmChas1Fr52
BA_ "GenMsgCycleTime" BO_ 135 20.000;
BA_ "GenMsgSendType" BO_ 135 0;
// Frame: EcmChas1Fr53
BA_ "GenMsgCycleTime" BO_ 121 20.000;
BA_ "GenMsgSendType" BO_ 121 0;
// Frame: EcmChas1GhsFr44
BA_ "GenMsgCycleTime" BO_ 113 10.000;
BA_ "GenMsgSendType" BO_ 113 0;
// Frame: EcmChas1GhsFr45
BA_ "GenMsgCycleTime" BO_ 118 10.000;
BA_ "GenMsgSendType" BO_ 118 0;
// Frame: EcmChas1GhsFr47
BA_ "GenMsgCycleTime" BO_ 133 10.000;
BA_ "GenMsgSendType" BO_ 133 0;
// Frame: EcmChas1NMFr
BA_ "GenMsgDelayTime" BO_ 1296 20.000;
BA_ "GenMsgSendType" BO_ 1296 1;
// Frame: EtcToMvemXcpFr01
BA_ "GenMsgDelayTime" BO_ 1429 5.000;
BA_ "GenMsgSendType" BO_ 1429 1;
// Frame: EtcToMvemXcpFr02
BA_ "GenMsgDelayTime" BO_ 1424 5.000;
BA_ "GenMsgSendType" BO_ 1424 1;
// Frame: EtcToMvemXcpFr03
BA_ "GenMsgDelayTime" BO_ 1425 5.000;
BA_ "GenMsgSendType" BO_ 1425 1;
// Frame: EtcToPscm1cChas1XcpFr01
BA_ "GenMsgDelayTime" BO_ 1441 5.000;
BA_ "GenMsgSendType" BO_ 1441 1;
// Frame: EtcToPscmChas1XcpFr01
BA_ "GenMsgDelayTime" BO_ 1409 5.000;
BA_ "GenMsgSendType" BO_ 1409 1;
// Frame: EtcToPscmChas1XcpFr02
BA_ "GenMsgDelayTime" BO_ 1416 5.000;
BA_ "GenMsgSendType" BO_ 1416 1;
// Frame: EtcToPscmChas1XcpFr03
BA_ "GenMsgDelayTime" BO_ 1418 5.000;
BA_ "GenMsgSendType" BO_ 1418 1;
// Frame: EtcToPscmChas1XcpFr04
BA_ "GenMsgDelayTime" BO_ 1420 5.000;
BA_ "GenMsgSendType" BO_ 1420 1;
// Frame: EtcToPscmDevelFr
BA_ "GenMsgDelayTime" BO_ 1431 95.000;
BA_ "GenMsgSendType" BO_ 1431 1;
// Frame: EtcToRasmChas1XcpFr01
BA_ "GenMsgDelayTime" BO_ 1442 5.000;
BA_ "GenMsgSendType" BO_ 1442 1;
// Frame: EtcToRbcmChas1DevFr01
BA_ "GenMsgDelayTime" BO_ 1504 95.000;
BA_ "GenMsgSendType" BO_ 1504 1;
// Frame: EtcToTcmXcpFr01
BA_ "GenMsgDelayTime" BO_ 1414 10.000;
BA_ "GenMsgSendType" BO_ 1414 1;
// Frame: EtcToTcmXcpFr02
BA_ "GenMsgDelayTime" BO_ 1411 10.000;
BA_ "GenMsgSendType" BO_ 1411 1;
// Frame: EtctoVddmBcmXCPFr01
BA_ "GenMsgDelayTime" BO_ 1421 10.000;
BA_ "GenMsgSendType" BO_ 1421 1;
// Frame: EtctoVddmDevelFr01
BA_ "GenMsgDelayTime" BO_ 1432 95.000;
BA_ "GenMsgSendType" BO_ 1432 1;
// Frame: EtctoVddmDevelFr02
BA_ "GenMsgDelayTime" BO_ 1433 95.000;
BA_ "GenMsgSendType" BO_ 1433 1;
// Frame: PasChas1Fr02
BA_ "GenMsgCycleTime" BO_ 235 15.000;
BA_ "GenMsgSendType" BO_ 235 0;
// Frame: PasChas1Fr04
BA_ "GenMsgDelayTime" BO_ 149 10.000;
BA_ "GenMsgSendType" BO_ 149 1;
// Frame: PcmChas1Fr19
BA_ "GenMsgCycleTime" BO_ 65 10.000;
BA_ "GenMsgSendType" BO_ 65 0;
// Frame: PcmChas1Fr20
BA_ "GenMsgCycleTime" BO_ 136 15.000;
BA_ "GenMsgSendType" BO_ 136 0;
// Frame: PcmChas1Fr21
BA_ "GenMsgCycleTime" BO_ 262 20.000;
BA_ "GenMsgSendType" BO_ 262 0;
// Frame: PcmChas1Fr22
BA_ "GenMsgCycleTime" BO_ 1142 1000.000;
BA_ "GenMsgSendType" BO_ 1142 0;
// Frame: PcmChas1Fr23
BA_ "GenMsgCycleTime" BO_ 83 15.000;
BA_ "GenMsgSendType" BO_ 83 0;
// Frame: PscmChas1Fr01
BA_ "GenMsgCycleTime" BO_ 246 10.000;
BA_ "GenMsgSendType" BO_ 246 0;
// Frame: PscmChas1Fr02
BA_ "GenMsgCycleTime" BO_ 70 15.000;
BA_ "GenMsgSendType" BO_ 70 0;
// Frame: PscmChas1Fr03
BA_ "GenMsgCycleTime" BO_ 444 25.000;
BA_ "GenMsgSendType" BO_ 444 0;
// Frame: PscmChas1Fr06
BA_ "GenMsgCycleTime" BO_ 955 400.000;
BA_ "GenMsgSendType" BO_ 955 0;
// Frame: PscmChas1Fr07
BA_ "GenMsgCycleTime" BO_ 78 10.000;
BA_ "GenMsgSendType" BO_ 78 0;
// Frame: PscmChas1NMFr
BA_ "GenMsgDelayTime" BO_ 1315 20.000;
BA_ "GenMsgSendType" BO_ 1315 1;
// Frame: PscmDevelpFr
BA_ "GenMsgDelayTime" BO_ 1430 95.000;
BA_ "GenMsgSendType" BO_ 1430 1;
// Frame: PscmToEtcChas1XcpFr01
BA_ "GenMsgDelayTime" BO_ 1410 5.000;
BA_ "GenMsgSendType" BO_ 1410 1;
// Frame: PscmToEtcChas1XcpFr02
BA_ "GenMsgDelayTime" BO_ 1417 5.000;
BA_ "GenMsgSendType" BO_ 1417 1;
// Frame: PscmToEtcChas1XcpFr03
BA_ "GenMsgDelayTime" BO_ 1419 5.000;
BA_ "GenMsgSendType" BO_ 1419 1;
// Frame: PscmToEtcChas1XcpFr04
BA_ "GenMsgDelayTime" BO_ 1415 5.000;
BA_ "GenMsgSendType" BO_ 1415 1;
// Frame: PscmToEtcChas1XcpFr05
BA_ "GenMsgDelayTime" BO_ 1412 5.000;
BA_ "GenMsgSendType" BO_ 1412 1;
// Frame: PscmToEtcChas1XcpFr06
BA_ "GenMsgDelayTime" BO_ 1423 5.000;
BA_ "GenMsgSendType" BO_ 1423 1;
// Frame: PscmToVddmChas1DiagResFrame
BA_ "GenMsgDelayTime" BO_ 1648 5.000;
BA_ "GenMsgSendType" BO_ 1648 1;
// Frame: SasChas1Fr01
BA_ "GenMsgCycleTime" BO_ 64 10.000;
BA_ "GenMsgSendType" BO_ 64 0;
// Frame: SasChas1NMFr
BA_ "GenMsgDelayTime" BO_ 1319 20.000;
BA_ "GenMsgSendType" BO_ 1319 1;
// Frame: SasToVddmChas1DiagResFrame
BA_ "GenMsgDelayTime" BO_ 1650 5.000;
BA_ "GenMsgSendType" BO_ 1650 1;
// Frame: TcmChas1Fr08
BA_ "GenMsgCycleTime" BO_ 128 30.000;
BA_ "GenMsgSendType" BO_ 128 0;
// Frame: TcmChas1Fr09
BA_ "GenMsgCycleTime" BO_ 512 200.000;
BA_ "GenMsgSendType" BO_ 512 0;
// Frame: TcmChas1Fr12
BA_ "GenMsgCycleTime" BO_ 261 15.000;
BA_ "GenMsgSendType" BO_ 261 0;
// Frame: TcmChas1Fr13
BA_ "GenMsgCycleTime" BO_ 629 100.000;
BA_ "GenMsgSendType" BO_ 629 0;
BA_ "GenMsgILSupport" BO_ 1321 0;
BA_ "GenMsgILSupport" BO_ 1334 0;
BA_ "GenMsgILSupport" BO_ 1296 0;
BA_ "GenMsgILSupport" BO_ 1315 0;
BA_ "GenMsgILSupport" BO_ 1319 0;
BA_ "NmAsrMessage" BO_ 1321 1;
BA_ "NmAsrMessage" BO_ 1334 1;
BA_ "NmAsrMessage" BO_ 1296 1;
BA_ "NmAsrMessage" BO_ 1315 1;
BA_ "NmAsrMessage" BO_ 1319 1;
BA_ "GenSigSendType" SG_ 185 ALgtStdFromWhlSpdALgtStdFromWhlSpd 0;
BA_ "GenSigDataID" SG_ 185 ALgtStdFromWhlSpdChks "0x34";
BA_ "GenSigFuncType" SG_ 185 ALgtStdFromWhlSpdChks 15;
BA_ "GenSigSendType" SG_ 185 ALgtStdFromWhlSpdChks 0;
BA_ "GenSigFuncType" SG_ 185 ALgtStdFromWhlSpdCntr 16;
BA_ "GenSigSendType" SG_ 185 ALgtStdFromWhlSpdCntr 0;
BA_ "GenSigSendType" SG_ 185 ALgtStdFromWhlSpdQf 0;
BA_ "GenSigStartValue" SG_ 185 ALgtStdFromWhlSpdQf 1;
BA_ "GenSigSendType" SG_ 543 AcCmprVlvICns 0;
BA_ "GenSigSendType" SG_ 544 AccrPedlRatAccrPedlRat 0;
BA_ "GenSigDataID" SG_ 544 AccrPedlRatChks "0x364";
BA_ "GenSigFuncType" SG_ 544 AccrPedlRatChks 15;
BA_ "GenSigSendType" SG_ 544 AccrPedlRatChks 0;
BA_ "GenSigFuncType" SG_ 544 AccrPedlRatCntr 16;
BA_ "GenSigSendType" SG_ 544 AccrPedlRatCntr 0;
BA_ "GenSigDataID" SG_ 455 AccrpedlStsChks "0x1781";
BA_ "GenSigFuncType" SG_ 455 AccrpedlStsChks 15;
BA_ "GenSigSendType" SG_ 455 AccrpedlStsChks 0;
BA_ "GenSigFuncType" SG_ 455 AccrpedlStsCntr 16;
BA_ "GenSigSendType" SG_ 455 AccrpedlStsCntr 0;
BA_ "GenSigSendType" SG_ 455 AccrpedlStsFltSts 0;
BA_ "GenSigSendType" SG_ 51 AgCtrlTqLowrLim 0;
BA_ "GenSigStartValue" SG_ 51 AgCtrlTqLowrLim 240;
BA_ "GenSigSendType" SG_ 51 AgCtrlTqUpprLim 0;
BA_ "GenSigStartValue" SG_ 51 AgCtrlTqUpprLim 240;
BA_ "GenSigSendType" SG_ 587 AirTFromHeatgEstimd 0;
BA_ "GenSigSendType" SG_ 147 AsyADL3FuncCtrlStsADMod 0;
BA_ "GenSigDataID" SG_ 147 AsyADL3FuncCtrlStsChks "0xD17";
BA_ "GenSigFuncType" SG_ 147 AsyADL3FuncCtrlStsChks 15;
BA_ "GenSigSendType" SG_ 147 AsyADL3FuncCtrlStsChks 0;
BA_ "GenSigFuncType" SG_ 147 AsyADL3FuncCtrlStsCntr 16;
BA_ "GenSigSendType" SG_ 147 AsyADL3FuncCtrlStsCntr 0;
BA_ "GenSigSendType" SG_ 147 AsyADL3FuncCtrlStsCtrlSts 0;
BA_ "GenSigSendType" SG_ 147 AsyADL3FuncCtrlStsDegraded 0;
BA_ "GenSigSendType" SG_ 147 AsyADL3FuncCtrlStsQf 0;
BA_ "GenSigSendType" SG_ 147 AsyADL3FuncCtrlStsSts 0;
BA_ "GenSigSendType" SG_ 147 AsyADModeReqADActiveReq 0;
BA_ "GenSigSendType" SG_ 147 AsyADModeReqADDeactiveReq 0;
BA_ "GenSigDataID" SG_ 147 AsyADModeReqChks "0xD18";
BA_ "GenSigFuncType" SG_ 147 AsyADModeReqChks 15;
BA_ "GenSigSendType" SG_ 147 AsyADModeReqChks 0;
BA_ "GenSigFuncType" SG_ 147 AsyADModeReqCntr 16;
BA_ "GenSigSendType" SG_ 147 AsyADModeReqCntr 0;
BA_ "GenSigSendType" SG_ 51 AsyPinionAgReqSafeAsyPinionAgReq 0;
BA_ "GenSigStartValue" SG_ 51 AsyPinionAgReqSafeAsyPinionAgReq 14848;
BA_ "GenSigDataID" SG_ 51 AsyPinionAgReqSafeAsyPinionAgReqChks "0x2F7";
BA_ "GenSigFuncType" SG_ 51 AsyPinionAgReqSafeAsyPinionAgReqChks 15;
BA_ "GenSigSendType" SG_ 51 AsyPinionAgReqSafeAsyPinionAgReqChks 0;
BA_ "GenSigFuncType" SG_ 51 AsyPinionAgReqSafeAsyPinionAgReqCntr 16;
BA_ "GenSigSendType" SG_ 51 AsyPinionAgReqSafeAsyPinionAgReqCntr 0;
BA_ "GenSigSendType" SG_ 1157 AutoShowModPrpsnEna 0;
BA_ "GenSigSendType" SG_ 1135 BattCooltIndcnReq 0;
BA_ "GenSigSendType" SG_ 871 BookChrgnTarValFb 0;
BA_ "GenSigStartValue" SG_ 871 BookChrgnTarValFb 1000;
BA_ "GenSigSendType" SG_ 129 BrkFActAutParkBrkSpprtReq 0;
BA_ "GenSigDataID" SG_ 129 BrkFActChks "0x42C";
BA_ "GenSigFuncType" SG_ 129 BrkFActChks 15;
BA_ "GenSigSendType" SG_ 129 BrkFActChks 0;
BA_ "GenSigFuncType" SG_ 129 BrkFActCntr 16;
BA_ "GenSigSendType" SG_ 129 BrkFActCntr 0;
BA_ "GenSigSendType" SG_ 129 BrkFActForce 0;
BA_ "GenSigDataID" SG_ 308 BrkWssInfoFrntChks "0x1F4";
BA_ "GenSigFuncType" SG_ 308 BrkWssInfoFrntChks 15;
BA_ "GenSigSendType" SG_ 308 BrkWssInfoFrntChks 0;
BA_ "GenSigFuncType" SG_ 308 BrkWssInfoFrntCntr 16;
BA_ "GenSigSendType" SG_ 308 BrkWssInfoFrntCntr 0;
BA_ "GenSigSendType" SG_ 308 BrkWssInfoFrntTTCFactorFL 0;
BA_ "GenSigStartValue" SG_ 308 BrkWssInfoFrntTTCFactorFL 32751.0917031;
BA_ "GenSigSendType" SG_ 308 BrkWssInfoFrntTTCFactorFR 0;
BA_ "GenSigStartValue" SG_ 308 BrkWssInfoFrntTTCFactorFR 32751.0917031;
BA_ "GenSigSendType" SG_ 308 BrkWssInfoFrntWssCoreMonRob 0;
BA_ "GenSigDataID" SG_ 327 BrkWssInfoReChks "0x1F5";
BA_ "GenSigFuncType" SG_ 327 BrkWssInfoReChks 15;
BA_ "GenSigSendType" SG_ 327 BrkWssInfoReChks 0;
BA_ "GenSigFuncType" SG_ 327 BrkWssInfoReCntr 16;
BA_ "GenSigSendType" SG_ 327 BrkWssInfoReCntr 0;
BA_ "GenSigSendType" SG_ 327 BrkWssInfoReTTCFactorRL 0;
BA_ "GenSigStartValue" SG_ 327 BrkWssInfoReTTCFactorRL 32751.0917031;
BA_ "GenSigSendType" SG_ 327 BrkWssInfoReTTCFactorRR 0;
BA_ "GenSigStartValue" SG_ 327 BrkWssInfoReTTCFactorRR 32751.0917031;
BA_ "GenSigSendType" SG_ 587 CchForPwrEcoBarForPwrEco 0;
BA_ "GenSigSendType" SG_ 587 CchForPwrEcoGrdForPwrEco 0;
BA_ "GenSigSendType" SG_ 632 ChrgnSpd 0;
BA_ "GenSigSendType" SG_ 979 CmprReqCmprSpdReq 0;
BA_ "GenSigSendType" SG_ 563 CmprRunTime 0;
BA_ "GenSigSendType" SG_ 304 CnvnAllwd 0;
BA_ "GenSigSendType" SG_ 1158 CooltFlowForTOC 0;
BA_ "GenSigSendType" SG_ 1135 CooltFlowInCmptmtCirc 0;
BA_ "GenSigSendType" SG_ 1158 CooltTSigForTOC 0;
BA_ "GenSigStartValue" SG_ 1158 CooltTSigForTOC 400;
BA_ "GenSigDataID" SG_ 83 DHTStSafeChks "0x1786";
BA_ "GenSigFuncType" SG_ 83 DHTStSafeChks 15;
BA_ "GenSigSendType" SG_ 83 DHTStSafeChks 0;
BA_ "GenSigFuncType" SG_ 83 DHTStSafeCntr 16;
BA_ "GenSigSendType" SG_ 83 DHTStSafeCntr 0;
BA_ "GenSigSendType" SG_ 83 DHTStSafeRsv 0;
BA_ "GenSigSendType" SG_ 83 DHTStSafeSpd 0;
BA_ "GenSigSendType" SG_ 83 DHTStSafeSpdQf 0;
BA_ "GenSigSendType" SG_ 83 DHTStSafeTqRt 0;
BA_ "GenSigSendType" SG_ 83 DHTStSafeTqRtQf 0;
BA_ "GenSigSendType" SG_ 871 DchaChrgnTarValFb 0;
BA_ "GenSigStartValue" SG_ 871 DchaChrgnTarValFb 200;
BA_ "GenSigSendType" SG_ 859 DispElecPwrAbs 0;
BA_ "GenSigSendType" SG_ 859 DispElecPwrSts 0;
BA_ "GenSigSendType" SG_ 913 DispIdlChrgPwr 0;
BA_ "GenSigSendType" SG_ 134 DrvgCyc 0;
BA_ "GenSigSendType" SG_ 752 DrvrGearLvrInfoIndcn 0;
BA_ "GenSigDataID" SG_ 246 DrvrSteerActvChks "0xBC";
BA_ "GenSigFuncType" SG_ 246 DrvrSteerActvChks 15;
BA_ "GenSigSendType" SG_ 246 DrvrSteerActvChks 0;
BA_ "GenSigFuncType" SG_ 246 DrvrSteerActvCntr 16;
BA_ "GenSigSendType" SG_ 246 DrvrSteerActvCntr 0;
BA_ "GenSigSendType" SG_ 246 DrvrSteerActvDrvrSteerActv 0;
BA_ "GenSigSendType" SG_ 444 DrvrSteerWhlHldGroupDrvrSteerWhlHld 0;
BA_ "GenSigSendType" SG_ 444 DrvrSteerWhlHldGroupDrvrSteerWhlHldQly 0;
BA_ "GenSigSendType" SG_ 837 DstEstimdToEmptyForDrvgElecPredTyp2 0;
BA_ "GenSigSendType" SG_ 1039 EldtPmpCmdCooltPmpPostRunReq 0;
BA_ "GenSigSendType" SG_ 1039 EldtPmpCmdCooltPmpSpdReq 0;
BA_ "GenSigSendType" SG_ 609 EldtPmpPwrCns 0;
BA_ "GenSigSendType" SG_ 113 ElecMot2ModReq 0;
BA_ "GenSigSendType" SG_ 65 ElecMot2ModSts 0;
BA_ "GenSigSendType" SG_ 65 ElecMot2SpdActSgn 0;
BA_ "GenSigSendType" SG_ 113 ElecMot2SpdReq 0;
BA_ "GenSigSendType" SG_ 113 ElecMot2TqReq 0;
BA_ "GenSigStartValue" SG_ 113 ElecMot2TqReq 8188;
BA_ "GenSigSendType" SG_ 609 EngCooltFlwAct 0;
BA_ "GenSigSendType" SG_ 609 EngCooltPmpPwrCns 0;
BA_ "GenSigSendType" SG_ 1039 EngCooltPmpSpdReqCooltPmpPostRunReq 0;
BA_ "GenSigSendType" SG_ 1039 EngCooltPmpSpdReqCooltPmpSpdReq 0;
BA_ "GenSigSendType" SG_ 80 EngN2 0;
BA_ "GenSigSendType" SG_ 304 EngNSafeEngN 0;
BA_ "GenSigDataID" SG_ 304 EngNSafeEngNChks "0x44";
BA_ "GenSigFuncType" SG_ 304 EngNSafeEngNChks 15;
BA_ "GenSigSendType" SG_ 304 EngNSafeEngNChks 0;
BA_ "GenSigFuncType" SG_ 304 EngNSafeEngNCntr 16;
BA_ "GenSigSendType" SG_ 304 EngNSafeEngNCntr 0;
BA_ "GenSigSendType" SG_ 304 EngNSafeEngNGrdt 0;
BA_ "GenSigSendType" SG_ 121 EngPAmbAir 0;
BA_ "GenSigSendType" SG_ 752 EngSt1WdSts1 0;
BA_ "GenSigDataID" SG_ 131 EngSt1WdStsChks "0x89";
BA_ "GenSigFuncType" SG_ 131 EngSt1WdStsChks 15;
BA_ "GenSigSendType" SG_ 131 EngSt1WdStsChks 0;
BA_ "GenSigFuncType" SG_ 131 EngSt1WdStsCntr 16;
BA_ "GenSigSendType" SG_ 131 EngSt1WdStsCntr 0;
BA_ "GenSigSendType" SG_ 131 EngSt1WdStsEngSt1WdSts 0;
BA_ "GenSigSendType" SG_ 1135 EngTRefSts 0;
BA_ "GenSigSendType" SG_ 1135 EngTRefT1 0;
BA_ "GenSigStartValue" SG_ 1135 EngTRefT1 50;
BA_ "GenSigSendType" SG_ 1135 EngTRefT2 0;
BA_ "GenSigStartValue" SG_ 1135 EngTRefT2 50;
BA_ "GenSigSendType" SG_ 133 EngTqCpMax 0;
BA_ "GenSigStartValue" SG_ 133 EngTqCpMax 2047;
BA_ "GenSigSendType" SG_ 133 EngTqCpMin 0;
BA_ "GenSigSendType" SG_ 136 EngTqIntvReqFast 0;
BA_ "GenSigStartValue" SG_ 136 EngTqIntvReqFast 1024;
BA_ "GenSigSendType" SG_ 136 EngTqIntvReqSlow 0;
BA_ "GenSigStartValue" SG_ 136 EngTqIntvReqSlow 1024;
BA_ "GenSigSendType" SG_ 113 EngageFastReq 0;
BA_ "GenSigSendType" SG_ 265 EpbAvlPrimApplyFunctionalitiesAvailable 0;
BA_ "GenSigDataID" SG_ 265 EpbAvlPrimChks "0x465";
BA_ "GenSigFuncType" SG_ 265 EpbAvlPrimChks 15;
BA_ "GenSigSendType" SG_ 265 EpbAvlPrimChks 0;
BA_ "GenSigFuncType" SG_ 265 EpbAvlPrimCntr 16;
BA_ "GenSigSendType" SG_ 265 EpbAvlPrimCntr 0;
BA_ "GenSigSendType" SG_ 265 EpbAvlPrimDriveAwayIntention 0;
BA_ "GenSigSendType" SG_ 265 EpbAvlPrimHostAvailabilityFull 0;
BA_ "GenSigSendType" SG_ 265 EpbAvlPrimHostAvailabilityRelOnly 0;
BA_ "GenSigSendType" SG_ 265 EpbAvlPrimPrimarySystemAvailable 0;
BA_ "GenSigSendType" SG_ 265 EpbAvlPrimReserved1 0;
BA_ "GenSigSendType" SG_ 265 EpbAvlPrimReserved2 0;
BA_ "GenSigSendType" SG_ 265 EpbAvlPrimReserved3 0;
BA_ "GenSigSendType" SG_ 265 EpbAvlPrimReserved4 0;
BA_ "GenSigSendType" SG_ 265 EpbAvlPrimRollerTestBench 0;
BA_ "GenSigDataID" SG_ 327 EpbStsChks "0x84";
BA_ "GenSigFuncType" SG_ 327 EpbStsChks 15;
BA_ "GenSigSendType" SG_ 327 EpbStsChks 0;
BA_ "GenSigFuncType" SG_ 327 EpbStsCntr 16;
BA_ "GenSigSendType" SG_ 327 EpbStsCntr 0;
BA_ "GenSigSendType" SG_ 327 EpbStsEpbSts 0;
BA_ "GenSigSendType" SG_ 991 FanPwmReqForEldt 0;
BA_ "GenSigSendType" SG_ 991 FanPwrCns 0;
BA_ "GenSigSendType" SG_ 246 FrntSteerFEstimd1 0;
BA_ "GenSigSendType" SG_ 65 GaGearAct 0;
BA_ "GenSigSendType" SG_ 543 GearMov 0;
BA_ "GenSigStartValue" SG_ 543 GearMov 2;
BA_ "GenSigSendType" SG_ 979 GrlShttrDmdShttrCalEna 0;
BA_ "GenSigSendType" SG_ 979 GrlShttrDmdShttrPosnReq 0;
BA_ "GenSigSendType" SG_ 979 HpBattVlvPosSetReq 0;
BA_ "GenSigSendType" SG_ 455 HvActvSts 0;
BA_ "GenSigSendType" SG_ 871 HvBattPmpCmdCooltPmpPostRunReq 0;
BA_ "GenSigSendType" SG_ 871 HvBattPmpCmdCooltPmpSpdReq 0;
BA_ "GenSigSendType" SG_ 576 HvBattPmpPwrCns 0;
BA_ "GenSigSendType" SG_ 730 HvBattPmpStatCooltPmpDryErr 0;
BA_ "GenSigSendType" SG_ 730 HvBattPmpStatCooltPmpEmgyModSts 0;
BA_ "GenSigSendType" SG_ 730 HvBattPmpStatCooltPmpErrSts 0;
BA_ "GenSigSendType" SG_ 730 HvBattPmpStatCooltPmpI 0;
BA_ "GenSigSendType" SG_ 730 HvBattPmpStatCooltPmpIErr 0;
BA_ "GenSigSendType" SG_ 730 HvBattPmpStatCooltPmpMonrSpd 0;
BA_ "GenSigSendType" SG_ 730 HvBattPmpStatCooltPmpPostRunSts 0;
BA_ "GenSigSendType" SG_ 730 HvBattPmpStatCooltPmpSetPostRunReq 0;
BA_ "GenSigSendType" SG_ 730 HvBattPmpStatCooltPmpSetSpdReq 0;
BA_ "GenSigSendType" SG_ 730 HvBattPmpStatCooltPmpSpd 0;
BA_ "GenSigSendType" SG_ 730 HvBattPmpStatCooltPmpT 0;
BA_ "GenSigStartValue" SG_ 730 HvBattPmpStatCooltPmpT 100;
BA_ "GenSigSendType" SG_ 730 HvBattPmpStatCooltPmpTErr 0;
BA_ "GenSigSendType" SG_ 730 HvBattPmpStatCooltPmpU 0;
BA_ "GenSigSendType" SG_ 730 HvBattPmpStatCooltPmpUErr 0;
BA_ "GenSigSendType" SG_ 730 HvBattPmpStatCooltPmpUnstallSts 0;
BA_ "GenSigSendType" SG_ 642 HvBattSocEngStart 0;
BA_ "GenSigDataID" SG_ 70 LatCtrlModCfmdChks "0x3A";
BA_ "GenSigFuncType" SG_ 70 LatCtrlModCfmdChks 15;
BA_ "GenSigSendType" SG_ 70 LatCtrlModCfmdChks 0;
BA_ "GenSigFuncType" SG_ 70 LatCtrlModCfmdCntr 16;
BA_ "GenSigSendType" SG_ 70 LatCtrlModCfmdCntr 0;
BA_ "GenSigSendType" SG_ 70 LatCtrlModCfmdLatCtrlMod 0;
BA_ "GenSigDataID" SG_ 135 Mot1ReqSafeChks "0x1787";
BA_ "GenSigFuncType" SG_ 135 Mot1ReqSafeChks 15;
BA_ "GenSigSendType" SG_ 135 Mot1ReqSafeChks 0;
BA_ "GenSigFuncType" SG_ 135 Mot1ReqSafeCntr 16;
BA_ "GenSigSendType" SG_ 135 Mot1ReqSafeCntr 0;
BA_ "GenSigSendType" SG_ 135 Mot1ReqSafeRsv 0;
BA_ "GenSigSendType" SG_ 135 Mot1ReqSafemod 0;
BA_ "GenSigSendType" SG_ 135 Mot1ReqSafespd 0;
BA_ "GenSigSendType" SG_ 135 Mot1ReqSafetq 0;
BA_ "GenSigStartValue" SG_ 135 Mot1ReqSafetq 8188;
BA_ "GenSigDataID" SG_ 121 Mot3ReqSafeChks "0x1788";
BA_ "GenSigFuncType" SG_ 121 Mot3ReqSafeChks 15;
BA_ "GenSigSendType" SG_ 121 Mot3ReqSafeChks 0;
BA_ "GenSigFuncType" SG_ 121 Mot3ReqSafeCntr 16;
BA_ "GenSigSendType" SG_ 121 Mot3ReqSafeCntr 0;
BA_ "GenSigSendType" SG_ 121 Mot3ReqSafeRsv 0;
BA_ "GenSigSendType" SG_ 121 Mot3ReqSafemod 0;
BA_ "GenSigSendType" SG_ 121 Mot3ReqSafespd 0;
BA_ "GenSigSendType" SG_ 121 Mot3ReqSafetq 0;
BA_ "GenSigStartValue" SG_ 121 Mot3ReqSafetq 8188;
BA_ "GenSigSendType" SG_ 147 PASFuncActive 0;
BA_ "GenSigSendType" SG_ 1431 PSCMdevelpsignalgroupreq1Functiondevpsignalgroup1 1;
BA_ "GenSigSendType" SG_ 1431 PSCMdevelpsignalgroupreq1Functiondevpsignalgroup2 1;
BA_ "GenSigSendType" SG_ 1431 PSCMdevelpsignalgroupreq1Functiondevpsignalgroup3 1;
BA_ "GenSigSendType" SG_ 1431 PSCMdevelpsignalgroupreq1Functiondevpsignalgroup4 1;
BA_ "GenSigSendType" SG_ 1431 PSCMdevelpsignalgroupreq1Functiondevpsignalgroup5 1;
BA_ "GenSigSendType" SG_ 1431 PSCMdevelpsignalgroupreq1Functiondevpsignalgroup6 1;
BA_ "GenSigSendType" SG_ 1431 PSCMdevelpsignalgroupreq1Functiondevpsignalgroup7 1;
BA_ "GenSigSendType" SG_ 1431 PSCMdevelpsignalgroupreq1Functiondevpsignalgroup8 1;
BA_ "GenSigSendType" SG_ 1430 PSCMdevelpsignalgroupresp1Functiondevpsignalgroup1 1;
BA_ "GenSigSendType" SG_ 1430 PSCMdevelpsignalgroupresp1Functiondevpsignalgroup2 1;
BA_ "GenSigSendType" SG_ 1430 PSCMdevelpsignalgroupresp1Functiondevpsignalgroup3 1;
BA_ "GenSigSendType" SG_ 1430 PSCMdevelpsignalgroupresp1Functiondevpsignalgroup4 1;
BA_ "GenSigSendType" SG_ 1430 PSCMdevelpsignalgroupresp1Functiondevpsignalgroup5 1;
BA_ "GenSigSendType" SG_ 1430 PSCMdevelpsignalgroupresp1Functiondevpsignalgroup6 1;
BA_ "GenSigSendType" SG_ 1430 PSCMdevelpsignalgroupresp1Functiondevpsignalgroup7 1;
BA_ "GenSigSendType" SG_ 1430 PSCMdevelpsignalgroupresp1Functiondevpsignalgroup8 1;
BA_ "GenSigDataID" SG_ 78 PinionSteerAgGroupChks "0x40D";
BA_ "GenSigFuncType" SG_ 78 PinionSteerAgGroupChks 15;
BA_ "GenSigSendType" SG_ 78 PinionSteerAgGroupChks 0;
BA_ "GenSigFuncType" SG_ 78 PinionSteerAgGroupCntr 16;
BA_ "GenSigSendType" SG_ 78 PinionSteerAgGroupCntr 0;
BA_ "GenSigSendType" SG_ 78 PinionSteerAgGroupPinionSteerAg1 0;
BA_ "GenSigSendType" SG_ 78 PinionSteerAgGroupPinionSteerAg1Qf 0;
BA_ "GenSigStartValue" SG_ 78 PinionSteerAgGroupPinionSteerAg1Qf 1;
BA_ "GenSigSendType" SG_ 78 PinionSteerAgGroupPinionSteerAgSpd1 0;
BA_ "GenSigSendType" SG_ 78 PinionSteerAgGroupPinionSteerAgSpd1Qf 0;
BA_ "GenSigStartValue" SG_ 78 PinionSteerAgGroupPinionSteerAgSpd1Qf 1;
BA_ "GenSigSendType" SG_ 78 PinionSteerAgGroupSteerWhlTq 0;
BA_ "GenSigSendType" SG_ 78 PinionSteerAgGroupSteerWhlTqQf 0;
BA_ "GenSigStartValue" SG_ 78 PinionSteerAgGroupSteerWhlTqQf 1;
BA_ "GenSigSendType" SG_ 955 PinionSteerAgMax1 0;
BA_ "GenSigSendType" SG_ 576 PostHeatgRunTiEstimd 0;
BA_ "GenSigSendType" SG_ 265 PrimBrkSysStBrkSysSt 0;
BA_ "GenSigDataID" SG_ 265 PrimBrkSysStChks "0x42E";
BA_ "GenSigFuncType" SG_ 265 PrimBrkSysStChks 15;
BA_ "GenSigSendType" SG_ 265 PrimBrkSysStChks 0;
BA_ "GenSigFuncType" SG_ 265 PrimBrkSysStCntr 16;
BA_ "GenSigSendType" SG_ 265 PrimBrkSysStCntr 0;
BA_ "GenSigDataID" SG_ 149 PrkgGearReqGroupChks "0x29D";
BA_ "GenSigFuncType" SG_ 149 PrkgGearReqGroupChks 15;
BA_ "GenSigSendType" SG_ 149 PrkgGearReqGroupChks 1;
BA_ "GenSigFuncType" SG_ 149 PrkgGearReqGroupCntr 16;
BA_ "GenSigSendType" SG_ 149 PrkgGearReqGroupCntr 1;
BA_ "GenSigSendType" SG_ 149 PrkgGearReqGroupReqSts1 1;
BA_ "GenSigSendType" SG_ 235 PrkgPinionAgReqGroupParkAssiPinionAgReq 0;
BA_ "GenSigStartValue" SG_ 235 PrkgPinionAgReqGroupParkAssiPinionAgReq 14847.9923978;
BA_ "GenSigDataID" SG_ 235 PrkgPinionAgReqGroupParkAssiPinionAgReqChks "0x1B1";
BA_ "GenSigFuncType" SG_ 235 PrkgPinionAgReqGroupParkAssiPinionAgReqChks 15;
BA_ "GenSigSendType" SG_ 235 PrkgPinionAgReqGroupParkAssiPinionAgReqChks 0;
BA_ "GenSigFuncType" SG_ 235 PrkgPinionAgReqGroupParkAssiPinionAgReqCntr 16;
BA_ "GenSigSendType" SG_ 235 PrkgPinionAgReqGroupParkAssiPinionAgReqCntr 0;
BA_ "GenSigSendType" SG_ 235 PrkgPinionAgReqGroupQF 0;
BA_ "GenSigStartValue" SG_ 235 PrkgPinionAgReqGroupQF 1;
BA_ "GenSigSendType" SG_ 118 PtClu0TqReq 0;
BA_ "GenSigSendType" SG_ 118 PtCluSlipCmdOfClu0 0;
BA_ "GenSigSendType" SG_ 118 PtCluSlipTarReqOfClu0 0;
BA_ "GenSigSendType" SG_ 80 PtCluTq2PtCluTq 0;
BA_ "GenSigStartValue" SG_ 80 PtCluTq2PtCluTq 1024;
BA_ "GenSigSendType" SG_ 80 PtCluTq2PtCluTqQly 0;
BA_ "GenSigSendType" SG_ 80 PtCluTq2Req 0;
BA_ "GenSigStartValue" SG_ 80 PtCluTq2Req 1024;
BA_ "GenSigSendType" SG_ 118 PtDtModReq 0;
BA_ "GenSigSendType" SG_ 118 PtEngTqAct 0;
BA_ "GenSigStartValue" SG_ 118 PtEngTqAct 1024;
BA_ "GenSigSendType" SG_ 135 PtGearActrAdpnCmd3DHT 0;
BA_ "GenSigSendType" SG_ 135 PtGearActtnAllwdStsDHT 0;
BA_ "GenSigSendType" SG_ 118 PtGearTarReq 0;
BA_ "GenSigSendType" SG_ 135 PtRotReqAckd 0;
BA_ "GenSigDataID" SG_ 1111 PtTqAtWhlFrntActChks "0x4E";
BA_ "GenSigFuncType" SG_ 1111 PtTqAtWhlFrntActChks 15;
BA_ "GenSigSendType" SG_ 1111 PtTqAtWhlFrntActChks 0;
BA_ "GenSigFuncType" SG_ 1111 PtTqAtWhlFrntActCntr 16;
BA_ "GenSigSendType" SG_ 1111 PtTqAtWhlFrntActCntr 0;
BA_ "GenSigSendType" SG_ 1111 PtTqAtWhlFrntActPtTqAtAxleFrntAct 0;
BA_ "GenSigSendType" SG_ 1111 PtTqAtWhlFrntActPtTqAtWhlFrntLeAct 0;
BA_ "GenSigSendType" SG_ 1111 PtTqAtWhlFrntActPtTqAtWhlFrntRiAct 0;
BA_ "GenSigSendType" SG_ 1111 PtTqAtWhlFrntActPtTqAtWhlsFrntQly 0;
BA_ "GenSigSendType" SG_ 708 PtVehSpdMaxChks 0;
BA_ "GenSigSendType" SG_ 708 PtVehSpdMaxCntr 0;
BA_ "GenSigSendType" SG_ 708 PtVehSpdMaxReq 0;
BA_ "GenSigStartValue" SG_ 708 PtVehSpdMaxReq 250;
BA_ "GenSigSendType" SG_ 118 PtWhlTqTar 0;
BA_ "GenSigStartValue" SG_ 118 PtWhlTqTar 6383;
BA_ "GenSigSendType" SG_ 1504 RBCMdevelpsignalgroupreq1Functiondevpsignalgroup1 1;
BA_ "GenSigSendType" SG_ 1504 RBCMdevelpsignalgroupreq1Functiondevpsignalgroup2 1;
BA_ "GenSigSendType" SG_ 1504 RBCMdevelpsignalgroupreq1Functiondevpsignalgroup3 1;
BA_ "GenSigSendType" SG_ 1504 RBCMdevelpsignalgroupreq1Functiondevpsignalgroup4 1;
BA_ "GenSigSendType" SG_ 1504 RBCMdevelpsignalgroupreq1Functiondevpsignalgroup5 1;
BA_ "GenSigSendType" SG_ 1504 RBCMdevelpsignalgroupreq1Functiondevpsignalgroup6 1;
BA_ "GenSigSendType" SG_ 1504 RBCMdevelpsignalgroupreq1Functiondevpsignalgroup7 1;
BA_ "GenSigSendType" SG_ 1504 RBCMdevelpsignalgroupreq1Functiondevpsignalgroup8 1;
BA_ "GenSigSendType" SG_ 129 RbuCtrlModReqSafeBrkSysModCfmd 0;
BA_ "GenSigDataID" SG_ 129 RbuCtrlModReqSafeChks "0x428";
BA_ "GenSigFuncType" SG_ 129 RbuCtrlModReqSafeChks 15;
BA_ "GenSigSendType" SG_ 129 RbuCtrlModReqSafeChks 0;
BA_ "GenSigFuncType" SG_ 129 RbuCtrlModReqSafeCntr 16;
BA_ "GenSigSendType" SG_ 129 RbuCtrlModReqSafeCntr 0;
BA_ "GenSigSendType" SG_ 147 RctaBrkReqQM 0;
BA_ "GenSigSendType" SG_ 147 RcwmBrkReqQM 0;
BA_ "GenSigSendType" SG_ 871 ReEvapVlvReq 0;
BA_ "GenSigSendType" SG_ 871 RegenAutLvlNotAvlMsg 0;
BA_ "GenSigSendType" SG_ 84 SBMHealthChkCmd 0;
BA_ "GenSigSendType" SG_ 185 SlipRatWithinRngForReWhls 0;
BA_ "GenSigStartValue" SG_ 185 SlipRatWithinRngForReWhls 1;
BA_ "GenSigSendType" SG_ 444 SteerErrReq 0;
BA_ "GenSigStartValue" SG_ 444 SteerErrReq 1;
BA_ "GenSigSendType" SG_ 444 SteerExtFctStsChks 0;
BA_ "GenSigSendType" SG_ 444 SteerExtFctStsCntr 0;
BA_ "GenSigSendType" SG_ 444 SteerExtFctStsDrvrSteerOvrd 0;
BA_ "GenSigSendType" SG_ 444 SteerExtFctStsExtFctLowerLimActive 0;
BA_ "GenSigSendType" SG_ 444 SteerExtFctStsExtFctRateLimActive 0;
BA_ "GenSigSendType" SG_ 444 SteerExtFctStsExtFctUpperLimActive 0;
BA_ "GenSigSendType" SG_ 444 SteerExtFctStsExtSafeLimActive 0;
BA_ "GenSigSendType" SG_ 444 SteerExtFctStsLatAgReqNotInRange 0;
BA_ "GenSigSendType" SG_ 444 SteerExtFctStsLatCtrlReqNotInRange 0;
BA_ "GenSigSendType" SG_ 70 SteerServoSts 0;
BA_ "GenSigSendType" SG_ 444 SteerStsToParkAssi 0;
BA_ "GenSigSendType" SG_ 64 SteerWhlSnsrAg 0;
BA_ "GenSigSendType" SG_ 64 SteerWhlSnsrAgSpd 0;
BA_ "GenSigDataID" SG_ 64 SteerWhlSnsrChks "0x33";
BA_ "GenSigFuncType" SG_ 64 SteerWhlSnsrChks 15;
BA_ "GenSigSendType" SG_ 64 SteerWhlSnsrChks 0;
BA_ "GenSigFuncType" SG_ 64 SteerWhlSnsrCntr 16;
BA_ "GenSigSendType" SG_ 64 SteerWhlSnsrCntr 0;
BA_ "GenSigSendType" SG_ 64 SteerWhlSnsrQf 0;
BA_ "GenSigStartValue" SG_ 64 SteerWhlSnsrQf 1;
BA_ "GenSigSendType" SG_ 70 SteerWhlTqAddl 0;
BA_ "GenSigSendType" SG_ 1142 TOCCooltFlowReq 0;
BA_ "GenSigSendType" SG_ 1135 TelltlPwrLoss 0;
BA_ "GenSigSendType" SG_ 70 TqAssAddl 0;
BA_ "GenSigSendType" SG_ 128 TrsmActrPosn2TrsmActrPosn 0;
BA_ "GenSigStartValue" SG_ 128 TrsmActrPosn2TrsmActrPosn 7;
BA_ "GenSigDataID" SG_ 128 TrsmActrPosn2TrsmActrPosnChks "0xD2";
BA_ "GenSigFuncType" SG_ 128 TrsmActrPosn2TrsmActrPosnChks 15;
BA_ "GenSigSendType" SG_ 128 TrsmActrPosn2TrsmActrPosnChks 0;
BA_ "GenSigFuncType" SG_ 128 TrsmActrPosn2TrsmActrPosnCntr 16;
BA_ "GenSigSendType" SG_ 128 TrsmActrPosn2TrsmActrPosnCntr 0;
BA_ "GenSigSendType" SG_ 512 TrsmClrRdyReq 0;
BA_ "GenSigSendType" SG_ 262 TrsmClu0FltIndcn 0;
BA_ "GenSigDataID" SG_ 262 TrsmClu0StsChks "0x1776";
BA_ "GenSigFuncType" SG_ 262 TrsmClu0StsChks 15;
BA_ "GenSigSendType" SG_ 262 TrsmClu0StsChks 0;
BA_ "GenSigFuncType" SG_ 262 TrsmClu0StsCntr 16;
BA_ "GenSigSendType" SG_ 262 TrsmClu0StsCntr 0;
BA_ "GenSigSendType" SG_ 262 TrsmClu0StsTrsm0CluSts 0;
BA_ "GenSigSendType" SG_ 65 TrsmCluSlipStsOfClu0 0;
BA_ "GenSigSendType" SG_ 512 TrsmCluTEstimdOfClu0 0;
BA_ "GenSigStartValue" SG_ 512 TrsmCluTEstimdOfClu0 32;
BA_ "GenSigSendType" SG_ 65 TrsmCluTqActOfClu0 0;
BA_ "GenSigStartValue" SG_ 65 TrsmCluTqActOfClu0 1024;
BA_ "GenSigSendType" SG_ 262 TrsmCluTqCpMaxOfClu0 0;
BA_ "GenSigStartValue" SG_ 262 TrsmCluTqCpMaxOfClu0 1024;
BA_ "GenSigSendType" SG_ 65 TrsmDtModAct 0;
BA_ "GenSigDataID" SG_ 629 TrsmEngmtLimdChks "0x6A";
BA_ "GenSigFuncType" SG_ 629 TrsmEngmtLimdChks 15;
BA_ "GenSigSendType" SG_ 629 TrsmEngmtLimdChks 0;
BA_ "GenSigFuncType" SG_ 629 TrsmEngmtLimdCntr 16;
BA_ "GenSigSendType" SG_ 629 TrsmEngmtLimdCntr 0;
BA_ "GenSigSendType" SG_ 629 TrsmEngmtLimdTrsmEngmtLimd 0;
BA_ "GenSigSendType" SG_ 629 TrsmErrIndcnReq 0;
BA_ "GenSigDataID" SG_ 128 TrsmGearActSafeChks "0x1775";
BA_ "GenSigFuncType" SG_ 128 TrsmGearActSafeChks 15;
BA_ "GenSigSendType" SG_ 128 TrsmGearActSafeChks 0;
BA_ "GenSigFuncType" SG_ 128 TrsmGearActSafeCntr 16;
BA_ "GenSigSendType" SG_ 128 TrsmGearActSafeCntr 0;
BA_ "GenSigSendType" SG_ 128 TrsmGearActSafeTrsmGearActSafe 0;
BA_ "GenSigSendType" SG_ 262 TrsmGearActrScanForRefActv3DHT 0;
BA_ "GenSigSendType" SG_ 262 TrsmGearActrScanForRefReq3DHT 0;
BA_ "GenSigSendType" SG_ 261 TrsmGearChgProgs 0;
BA_ "GenSigSendType" SG_ 262 TrsmGearEngmtSts 0;
BA_ "GenSigSendType" SG_ 629 TrsmHotSt 0;
BA_ "GenSigSendType" SG_ 261 TrsmModNotAvlSts 0;
BA_ "GenSigSendType" SG_ 65 TrsmModShiftActv 0;
BA_ "GenSigDataID" SG_ 136 TrsmOutpNChks "0x466";
BA_ "GenSigFuncType" SG_ 136 TrsmOutpNChks 15;
BA_ "GenSigSendType" SG_ 136 TrsmOutpNChks 0;
BA_ "GenSigFuncType" SG_ 136 TrsmOutpNCntr 16;
BA_ "GenSigSendType" SG_ 136 TrsmOutpNCntr 0;
BA_ "GenSigSendType" SG_ 136 TrsmOutpNDir 0;
BA_ "GenSigSendType" SG_ 136 TrsmOutpNSpd 0;
BA_ "GenSigSendType" SG_ 136 TrsmOutpNSpdQf 0;
BA_ "GenSigSendType" SG_ 262 TrsmParkLockSt 0;
BA_ "GenSigSendType" SG_ 629 TrsmReqForPfmncRedn 0;
BA_ "GenSigSendType" SG_ 262 TrsmRotReq 0;
BA_ "GenSigSendType" SG_ 261 TrsmToPrpsnNReqRecTrsmNReqCtrl 0;
BA_ "GenSigSendType" SG_ 261 TrsmToPrpsnNReqRecTrsmNReqMax 0;
BA_ "GenSigStartValue" SG_ 261 TrsmToPrpsnNReqRecTrsmNReqMax 12767;
BA_ "GenSigSendType" SG_ 261 TrsmToPrpsnNReqRecTrsmNReqMin 0;
BA_ "GenSigDataID" SG_ 629 TrsmTqLossChks "0x6B";
BA_ "GenSigFuncType" SG_ 629 TrsmTqLossChks 15;
BA_ "GenSigSendType" SG_ 629 TrsmTqLossChks 0;
BA_ "GenSigFuncType" SG_ 629 TrsmTqLossCntr 16;
BA_ "GenSigSendType" SG_ 629 TrsmTqLossCntr 0;
BA_ "GenSigSendType" SG_ 629 TrsmTqLossTrsmTqEff 0;
BA_ "GenSigSendType" SG_ 629 TrsmTqLossTrsmTqLoss 0;
BA_ "GenSigSendType" SG_ 261 TrsmTqRat 0;
BA_ "GenSigSendType" SG_ 262 TrsmWhlProtnMaxTq 0;
BA_ "GenSigSendType" SG_ 246 UBoostReqBySteerFrnt 0;
BA_ "GenSigSendType" SG_ 1432 VDDMdevelpsignalgroupreq1Functiondevpsignalgroup1 1;
BA_ "GenSigSendType" SG_ 1432 VDDMdevelpsignalgroupreq1Functiondevpsignalgroup2 1;
BA_ "GenSigSendType" SG_ 1432 VDDMdevelpsignalgroupreq1Functiondevpsignalgroup3 1;
BA_ "GenSigSendType" SG_ 1432 VDDMdevelpsignalgroupreq1Functiondevpsignalgroup4 1;
BA_ "GenSigSendType" SG_ 1432 VDDMdevelpsignalgroupreq1Functiondevpsignalgroup5 1;
BA_ "GenSigSendType" SG_ 1432 VDDMdevelpsignalgroupreq1Functiondevpsignalgroup6 1;
BA_ "GenSigSendType" SG_ 1432 VDDMdevelpsignalgroupreq1Functiondevpsignalgroup7 1;
BA_ "GenSigSendType" SG_ 1432 VDDMdevelpsignalgroupreq1Functiondevpsignalgroup8 1;
BA_ "GenSigSendType" SG_ 1433 VDDMdevelpsignalgroupreq2Functiondevpsignalgroup1 1;
BA_ "GenSigSendType" SG_ 1433 VDDMdevelpsignalgroupreq2Functiondevpsignalgroup2 1;
BA_ "GenSigSendType" SG_ 1433 VDDMdevelpsignalgroupreq2Functiondevpsignalgroup3 1;
BA_ "GenSigSendType" SG_ 1433 VDDMdevelpsignalgroupreq2Functiondevpsignalgroup4 1;
BA_ "GenSigSendType" SG_ 1433 VDDMdevelpsignalgroupreq2Functiondevpsignalgroup5 1;
BA_ "GenSigSendType" SG_ 1433 VDDMdevelpsignalgroupreq2Functiondevpsignalgroup6 1;
BA_ "GenSigSendType" SG_ 1433 VDDMdevelpsignalgroupreq2Functiondevpsignalgroup7 1;
BA_ "GenSigSendType" SG_ 1433 VDDMdevelpsignalgroupreq2Functiondevpsignalgroup8 1;
BA_ "GenSigSendType" SG_ 113 WhlTqTarOfDrvMot 0;
BA_ "GenSigStartValue" SG_ 113 WhlTqTarOfDrvMot 6383;

VAL_ 147 AsyADL3FuncCtrlStsADMod 0 "ADMod_NAD_Mod" 1 "ADMod_TJP_HWC" 2 "ADMod_NOP" 3 "ADMod_E2E";
VAL_ 147 AsyADL3FuncCtrlStsCtrlSts 0 "Primary" 1 "Secondary";
VAL_ 147 AsyADL3FuncCtrlStsQf 0 "GenQf1_UndefindDataAccur" 1 "GenQf1_TmpUndefdData" 2 "GenQf1_DataAccurNotWithinSpcn" 3 "GenQf1_AccurData";
VAL_ 147 AsyADL3FuncCtrlStsSts 0 "ColorSts_Red" 1 "ColorSts_Yellow" 2 "ColorSts_Green" 3 "ColorSts_Reserved";
VAL_ 147 AsyADModeReqADActiveReq 0 "ADMod_NAD_Mod" 1 "ADMod_TJP_HWC" 2 "ADMod_NOP" 3 "ADMod_E2E";
VAL_ 147 AsyADModeReqADDeactiveReq 0 "ReqSts1_NotReqd" 1 "ReqSts1_Reqd";
VAL_ 147 PASFuncActive 0 "OnOff1_Off" 1 "OnOff1_On";
VAL_ 147 RctaBrkReqQM 0 "OnOff1_Off" 1 "OnOff1_On";
VAL_ 147 RcwmBrkReqQM 0 "OnOff1_Off" 1 "OnOff1_On";
VAL_ 327 EpbStsEpbSts 0 "EpbSts_Resd0" 1 "EpbSts_Resd1" 2 "EpbSts_Resd2" 3 "EpbSts_AllAppld" 4 "EpbSts_Resd4" 5 "EpbSts_AllInTran" 6 "EpbSts_BrkgDynByActr" 7 "EpbSts_Resd7" 8 "EpbSts_Resd8" 9 "EpbSts_ActrAllReld" 10 "EpbSts_BrkgDynDegraded" 11 "EpbSts_Resd11" 12 "EpbSts_BrkgDyn" 13 "EpbSts_Resd13" 14 "EpbSts_Resd14" 15 "EpbSts_Err";
VAL_ 129 BrkFActAutParkBrkSpprtReq 0 "ReqSts1_NotReqd" 1 "ReqSts1_Reqd";
VAL_ 129 RbuCtrlModReqSafeBrkSysModCfmd 0 "ModCfmd_NoReq" 1 "ModCfmd_E2E" 2 "ModCfmd_Reserved2" 3 "ModCfmd_Reserved3" 4 "ModCfmd_Reserved4" 5 "ModCfmd_Reserved5" 6 "ModCfmd_Reserved6" 7 "ModCfmd_Reserved7" 8 "ModCfmd_Reserved8" 9 "ModCfmd_ACC_HWA" 10 "ModCfmd_PEB" 11 "ModCfmd_APA" 12 "ModCfmd_RPA" 13 "ModCfmd_HPA" 14 "ModCfmd_TJP_HWC" 15 "ModCfmd_NOP";
VAL_ 265 EpbAvlPrimApplyFunctionalitiesAvailable 0 "MsgSts_Inactive" 1 "MsgSts_Active";
VAL_ 265 EpbAvlPrimDriveAwayIntention 0 "MsgSts_Inactive" 1 "MsgSts_Active";
VAL_ 265 EpbAvlPrimHostAvailabilityFull 0 "MsgSts_Inactive" 1 "MsgSts_Active";
VAL_ 265 EpbAvlPrimHostAvailabilityRelOnly 0 "MsgSts_Inactive" 1 "MsgSts_Active";
VAL_ 265 EpbAvlPrimPrimarySystemAvailable 0 "MsgSts_Inactive" 1 "MsgSts_Active";
VAL_ 265 EpbAvlPrimReserved1 0 "MsgSts_Inactive" 1 "MsgSts_Active";
VAL_ 265 EpbAvlPrimReserved2 0 "MsgSts_Inactive" 1 "MsgSts_Active";
VAL_ 265 EpbAvlPrimReserved3 0 "MsgSts_Inactive" 1 "MsgSts_Active";
VAL_ 265 EpbAvlPrimReserved4 0 "MsgSts_Inactive" 1 "MsgSts_Active";
VAL_ 265 EpbAvlPrimRollerTestBench 0 "MsgSts_Inactive" 1 "MsgSts_Active";
VAL_ 265 PrimBrkSysStBrkSysSt 0 "NotAvailable_Temporary" 1 "NotAvailable_NotReleased" 2 "NotAvailable_Permanent" 3 "NotActivated_FullAvailable" 4 "Activation_Preparation" 5 "Activation_Pending" 6 "Activation_PendingRedundancyLost" 7 "Activation_PendingFailOperation" 8 "Activated_FullAvailable" 9 "Activated_FailOperation" 10 "Activated_RedundancyLost" 11 "Deactivation_Pending";
VAL_ 185 ALgtStdFromWhlSpdQf 0 "GenQf1_UndefindDataAccur" 1 "GenQf1_TmpUndefdData" 2 "GenQf1_DataAccurNotWithinSpcn" 3 "GenQf1_AccurData";
VAL_ 185 SlipRatWithinRngForReWhls 0 "NoYes1_No" 1 "NoYes1_Yes";
VAL_ 134 DrvgCyc 0 "OnOff1_Off" 1 "OnOff1_On";
VAL_ 80 PtCluTq2PtCluTqQly 0 "Qly3_De0" 1 "Qly3_De1" 2 "Qly3_De2" 3 "Qly3_De3" 4 "Qly3_De4" 5 "Qly3_De5" 6 "Qly3_De6" 7 "Qly3_De7";
VAL_ 1111 PtTqAtWhlFrntActPtTqAtWhlsFrntQly 0 "Qly3_De0" 1 "Qly3_De1" 2 "Qly3_De2" 3 "Qly3_De3" 4 "Qly3_De4" 5 "Qly3_De5" 6 "Qly3_De6" 7 "Qly3_De7";
VAL_ 730 HvBattPmpStatCooltPmpDryErr 0 "CooltPmpDryErr_RunDryNotDetd" 1 "CooltPmpDryErr_RunDryDetd" 2 "CooltPmpDryErr_Resd1" 3 "CooltPmpDryErr_Resd2";
VAL_ 730 HvBattPmpStatCooltPmpEmgyModSts 0 "CooltPmpEmgyModSts_EmgyRunNotActv" 1 "CooltPmpEmgyModSts_EmgyRunActv" 2 "CooltPmpEmgyModSts_Resd1" 3 "CooltPmpEmgyModSts_Resd2";
VAL_ 730 HvBattPmpStatCooltPmpErrSts 0 "CooltPmpErrSts_StNoErr" 1 "CooltPmpErrSts_StErr" 2 "CooltPmpErrSts_StNewErr" 3 "CooltPmpErrSts_Resd";
VAL_ 730 HvBattPmpStatCooltPmpIErr 0 "CooltPmpIErr_INoErr" 1 "CooltPmpIErr_IErr" 2 "CooltPmpIErr_Resd1" 3 "CooltPmpIErr_Resd2";
VAL_ 730 HvBattPmpStatCooltPmpMonrSpd 0 "CooltPmpMonrSpd_MonrSpdActv" 1 "CooltPmpMonrSpd_MonrSpdNoActv" 2 "CooltPmpMonrSpd_Resd1" 3 "CooltPmpMonrSpd_Resd2";
VAL_ 730 HvBattPmpStatCooltPmpPostRunSts 0 "CooltPmpPostRunSts_CooltPmpPostRunFinshd" 1 "CooltPmpPostRunSts_CooltPmpPostRunCncld" 2 "CooltPmpPostRunSts_Resd1" 3 "CooltPmpPostRunSts_Resd2";
VAL_ 730 HvBattPmpStatCooltPmpSetPostRunReq 0 "CooltPmpSetPostRunReq_CooltPmpSetNoPostRun" 1 "CooltPmpSetPostRunReq_CooltPmpSetPostRun1" 2 "CooltPmpSetPostRunReq_CooltPmpSetPostRun2" 3 "CooltPmpSetPostRunReq_CooltPmpSetPostRun3" 4 "CooltPmpSetPostRunReq_CooltPmpSetPostRun4" 5 "CooltPmpSetPostRunReq_CooltPmpSetPostRun5" 6 "CooltPmpSetPostRunReq_Resd1" 7 "CooltPmpSetPostRunReq_Resd2";
VAL_ 730 HvBattPmpStatCooltPmpTErr 0 "CooltPmpTErr_CooltPmpNoTErr" 1 "CooltPmpTErr_CooltPmpTErr" 2 "CooltPmpTErr_Resd1" 3 "CooltPmpTErr_Resd2";
VAL_ 730 HvBattPmpStatCooltPmpUErr 0 "CooltPmpUErr_CooltPmpNoUErr" 1 "CooltPmpUErr_CooltPmpUErr" 2 "CooltPmpUErr_Resd1" 3 "CooltPmpUErr_Resd2";
VAL_ 730 HvBattPmpStatCooltPmpUnstallSts 0 "CooltPmpUnstallSts_CooltPmpUnstallNotActv" 1 "CooltPmpUnstallSts_CooltPmpUnstallActv" 2 "CooltPmpUnstallSts_Resd1" 3 "CooltPmpUnstallSts_Resd2";
VAL_ 859 DispElecPwrSts 0 "OnOff1_Off" 1 "OnOff1_On";
VAL_ 871 HvBattPmpCmdCooltPmpPostRunReq 0 "CooltPmpPostRun_CooltPmpNoPostRun" 1 "CooltPmpPostRun_CooltPmpPostRun1" 2 "CooltPmpPostRun_CooltPmpPostRun2" 3 "CooltPmpPostRun_CooltPmpPostRun3" 4 "CooltPmpPostRun_CooltPmpPostRun4" 5 "CooltPmpPostRun_Resvd1" 6 "CooltPmpPostRun_Resvd2" 7 "CooltPmpPostRun_Resvd3";
VAL_ 871 ReEvapVlvReq 0 "OnOff1_Off" 1 "OnOff1_On";
VAL_ 871 RegenAutLvlNotAvlMsg 0 "OnOff1_Off" 1 "OnOff1_On";
VAL_ 979 GrlShttrDmdShttrCalEna 0 "ShttrCalEna_ShttrCalNotEnad" 1 "ShttrCalEna_ShttrCalEnad";
VAL_ 1039 EldtPmpCmdCooltPmpPostRunReq 0 "CooltPmpPostRun_CooltPmpNoPostRun" 1 "CooltPmpPostRun_CooltPmpPostRun1" 2 "CooltPmpPostRun_CooltPmpPostRun2" 3 "CooltPmpPostRun_CooltPmpPostRun3" 4 "CooltPmpPostRun_CooltPmpPostRun4" 5 "CooltPmpPostRun_Resvd1" 6 "CooltPmpPostRun_Resvd2" 7 "CooltPmpPostRun_Resvd3";
VAL_ 1039 EngCooltPmpSpdReqCooltPmpPostRunReq 0 "CooltPmpPostRun_CooltPmpNoPostRun" 1 "CooltPmpPostRun_CooltPmpPostRun1" 2 "CooltPmpPostRun_CooltPmpPostRun2" 3 "CooltPmpPostRun_CooltPmpPostRun3" 4 "CooltPmpPostRun_CooltPmpPostRun4" 5 "CooltPmpPostRun_Resvd1" 6 "CooltPmpPostRun_Resvd2" 7 "CooltPmpPostRun_Resvd3";
VAL_ 304 CnvnAllwd 0 "OkNotOk_NotOk" 1 "OkNotOk_Ok";
VAL_ 1135 BattCooltIndcnReq 0 "Boolean_FALSE" 1 "Boolean_TRUE";
VAL_ 1135 TelltlPwrLoss 0 "OnOff1_Off" 1 "OnOff1_On";
VAL_ 455 AccrpedlStsFltSts 0 "Flt_NoFault" 1 "Flt_Fault";
VAL_ 455 HvActvSts 0 "HvActvSts_Default" 1 "HvActvSts_CPSRIsActivated" 2 "HvActvSts_CPSRPlusContactorsIsActivated" 3 "HvActvSts_Error";
VAL_ 543 GearMov 0 "NoYesUnknownYes_No" 1 "NoYesUnknownYes_YesNo" 2 "NoYesUnknownYes_Unknown" 3 "NoYesUnknownYes_YesYes";
VAL_ 131 EngSt1WdStsEngSt1WdSts 0 "EngSt1_Ini" 1 "EngSt1_Awake" 2 "EngSt1_Rdy" 3 "EngSt1_PreStrtg" 4 "EngSt1_StrtgInProgs" 5 "EngSt1_RunngRunng" 6 "EngSt1_RunngStb" 7 "EngSt1_RunngStrtgInProgs" 8 "EngSt1_RunngRemStrtd" 9 "EngSt1_AftRun";
VAL_ 752 DrvrGearLvrInfoIndcn 0 "BrkMsgWarn1_NoReq" 1 "BrkMsgWarn1_Msg1" 2 "BrkMsgWarn1_Msg2" 3 "BrkMsgWarn1_Msg3" 4 "BrkMsgWarn1_Msg4" 5 "BrkMsgWarn1_Msg5" 6 "BrkMsgWarn1_Msg6" 7 "BrkMsgWarn1_Msg7";
VAL_ 752 EngSt1WdSts1 0 "EngSt1_Ini" 1 "EngSt1_Awake" 2 "EngSt1_Rdy" 3 "EngSt1_PreStrtg" 4 "EngSt1_StrtgInProgs" 5 "EngSt1_RunngRunng" 6 "EngSt1_RunngStb" 7 "EngSt1_RunngStrtgInProgs" 8 "EngSt1_RunngRemStrtd" 9 "EngSt1_AftRun";
VAL_ 1157 AutoShowModPrpsnEna 0 "OkNotOk_NotOk" 1 "OkNotOk_Ok";
VAL_ 135 Mot1ReqSafemod 0 "IsgModTyp1_Inin" 1 "IsgModTyp1_Stb" 2 "IsgModTyp1_TqCtrl" 3 "IsgModTyp1_SpdCtrl" 4 "IsgModTyp1_UDcCtrl" 5 "IsgModTyp1_PreChrg" 6 "IsgModTyp1_PwrDwn" 7 "IsgModTyp1_Flt" 8 "IsgModTyp1_TcsCtrl" 9 "IsgModTyp1_Reserved1" 10 "IsgModTyp1_Reserved2" 11 "IsgModTyp1_Reserved3" 12 "IsgModTyp1_Reserved4" 13 "IsgModTyp1_Reserved5" 14 "IsgModTyp1_Reserved6" 15 "IsgModTyp1_Reserved7";
VAL_ 135 PtGearActrAdpnCmd3DHT 0 "Boolean_FALSE" 1 "Boolean_TRUE";
VAL_ 135 PtRotReqAckd 0 "Boolean_FALSE" 1 "Boolean_TRUE";
VAL_ 121 Mot3ReqSafemod 0 "IsgModTyp1_Inin" 1 "IsgModTyp1_Stb" 2 "IsgModTyp1_TqCtrl" 3 "IsgModTyp1_SpdCtrl" 4 "IsgModTyp1_UDcCtrl" 5 "IsgModTyp1_PreChrg" 6 "IsgModTyp1_PwrDwn" 7 "IsgModTyp1_Flt" 8 "IsgModTyp1_TcsCtrl" 9 "IsgModTyp1_Reserved1" 10 "IsgModTyp1_Reserved2" 11 "IsgModTyp1_Reserved3" 12 "IsgModTyp1_Reserved4" 13 "IsgModTyp1_Reserved5" 14 "IsgModTyp1_Reserved6" 15 "IsgModTyp1_Reserved7";
VAL_ 113 ElecMot2ModReq 0 "IsgModTyp1_Inin" 1 "IsgModTyp1_Stb" 2 "IsgModTyp1_TqCtrl" 3 "IsgModTyp1_SpdCtrl" 4 "IsgModTyp1_UDcCtrl" 5 "IsgModTyp1_PreChrg" 6 "IsgModTyp1_PwrDwn" 7 "IsgModTyp1_Flt" 8 "IsgModTyp1_TcsCtrl" 9 "IsgModTyp1_Reserved1" 10 "IsgModTyp1_Reserved2" 11 "IsgModTyp1_Reserved3" 12 "IsgModTyp1_Reserved4" 13 "IsgModTyp1_Reserved5" 14 "IsgModTyp1_Reserved6" 15 "IsgModTyp1_Reserved7";
VAL_ 113 EngageFastReq 0 "Boolean_FALSE" 1 "Boolean_TRUE";
VAL_ 118 PtCluSlipCmdOfClu0 0 "CluSlipCmd_NoEcmControlReq" 1 "CluSlipCmd_ClutchSlip" 2 "CluSlipCmd_ClutchTorqueFollow" 3 "CluSlipCmd_OpenForParallelGearshift";
VAL_ 118 PtDtModReq 0 "PtModReq_Ev" 1 "PtModReq_Serial" 2 "PtModReq_Parallel" 3 "PtModReq_P2Gen" 4 "PtModReq_ParallelLaunch";
VAL_ 118 PtGearTarReq 0 "GearIndcnTyp3_Neut" 1 "GearIndcnTyp3_Gear1" 2 "GearIndcnTyp3_Gear2" 3 "GearIndcnTyp3_Gear3" 4 "GearIndcnTyp3_N1" 5 "GearIndcnTyp3_N12" 6 "GearIndcnTyp3_N23" 7 "GearIndcnTyp3_N3";
VAL_ 235 PrkgPinionAgReqGroupQF 0 "GenQf1_UndefindDataAccur" 1 "GenQf1_TmpUndefdData" 2 "GenQf1_DataAccurNotWithinSpcn" 3 "GenQf1_AccurData";
VAL_ 149 PrkgGearReqGroupReqSts1 0 "ReqSts1_NotReqd" 1 "ReqSts1_Reqd";
VAL_ 65 ElecMot2ModSts 0 "IsgModTyp2_Inin" 1 "IsgModTyp2_Stb" 2 "IsgModTyp2_TqCtrl" 3 "IsgModTyp2_SpdCtrl" 4 "IsgModTyp2_UDcCtrl" 5 "IsgModTyp2_PreChrg" 6 "IsgModTyp2_PwrDwn" 7 "IsgModTyp2_Flt" 8 "IsgModTyp2_TcsCtrl" 9 "IsgModTyp2_CluOpe";
VAL_ 65 TrsmCluSlipStsOfClu0 0 "CluSlipCmd_NoEcmControlReq" 1 "CluSlipCmd_ClutchSlip" 2 "CluSlipCmd_ClutchTorqueFollow" 3 "CluSlipCmd_OpenForParallelGearshift";
VAL_ 65 TrsmDtModAct 0 "PtModReq_Ev" 1 "PtModReq_Serial" 2 "PtModReq_Parallel" 3 "PtModReq_P2Gen" 4 "PtModReq_ParallelLaunch";
VAL_ 65 TrsmModShiftActv 0 "NotCmpl1_NotCmpl" 1 "NotCmpl1_Cmpl";
VAL_ 136 TrsmOutpNDir 0 "TrsmOutpDir_NotBackw" 1 "TrsmOutpDir_Backw";
VAL_ 136 TrsmOutpNSpdQf 0 "GenQf1_UndefindDataAccur" 1 "GenQf1_TmpUndefdData" 2 "GenQf1_DataAccurNotWithinSpcn" 3 "GenQf1_AccurData";
VAL_ 262 TrsmClu0FltIndcn 0 "TrsmClu0FltIndcn_Default" 1 "TrsmClu0FltIndcn_FailToDisengage" 2 "TrsmClu0FltIndcn_FailToEngage" 3 "TrsmClu0FltIndcn_LongSlip";
VAL_ 262 TrsmClu0StsTrsm0CluSts 0 "TrsmClu0Sts_Invalid" 1 "TrsmClu0Sts_Enggaged" 2 "TrsmClu0Sts_Disengaged" 3 "TrsmClu0Sts_Unkown";
VAL_ 262 TrsmGearActrScanForRefActv3DHT 0 "Boolean_FALSE" 1 "Boolean_TRUE";
VAL_ 262 TrsmGearActrScanForRefReq3DHT 0 "Boolean_FALSE" 1 "Boolean_TRUE";
VAL_ 262 TrsmParkLockSt 0 "LockSt4_Engaged" 1 "LockSt4_Disengaged" 2 "LockSt4_In_Progs" 3 "LockSt4_Undefined";
VAL_ 262 TrsmRotReq 0 "Boolean_FALSE" 1 "Boolean_TRUE";
VAL_ 83 DHTStSafeSpdQf 0 "Qf1_DevOfDataUndefd" 1 "Qf1_DataTmpUndefdAndEvlnInProgs" 2 "Qf1_DevOfDataNotWithinRngAllwd" 3 "Qf1_DataCalcdWithDevDefd";
VAL_ 83 DHTStSafeTqRtQf 0 "Qf1_DevOfDataUndefd" 1 "Qf1_DataTmpUndefdAndEvlnInProgs" 2 "Qf1_DevOfDataNotWithinRngAllwd" 3 "Qf1_DataCalcdWithDevDefd";
VAL_ 246 DrvrSteerActvDrvrSteerActv 0 "OnOff1_Off" 1 "OnOff1_On";
VAL_ 246 UBoostReqBySteerFrnt 0 "ReqStsSteer_NoReq" 1 "ReqStsSteer_ParkReq" 2 "ReqStsSteer_EvasiveReq" 3 "ReqStsSteer_Spare01";
VAL_ 70 LatCtrlModCfmdLatCtrlMod 0 "LatCtrlMod1_NoReq" 1 "LatCtrlMod1_HighWayAssist" 2 "LatCtrlMod1_EmgyLaneKeepAidForObjRe" 3 "LatCtrlMod1_EmgyLaneKeepAidForStat" 4 "LatCtrlMod1_SftyLaneKeepAid" 5 "LatCtrlMod1_SteerAssc" 6 "LatCtrlMod1_DsrOversteer" 7 "LatCtrlMod1_DsrMueSplit" 8 "LatCtrlMod1_DsrTrlrStaby" 9 "LatCtrlMod1_EmgyManvAssi" 10 "LatCtrlMod1_Reserved1" 11 "LatCtrlMod1_Reserved2" 12 "LatCtrlMod1_SHWA" 13 "LatCtrlMod1_APA" 14 "LatCtrlMod1_RPA" 15 "LatCtrlMod1_HPA";
VAL_ 70 SteerServoSts 0 "SteerServoSts1_SteerPwrAssidElecFullFct" 1 "SteerServoSts1_SteerPwrAssidElecCritErr";
VAL_ 444 DrvrSteerWhlHldGroupDrvrSteerWhlHld 0 "OnOffDetd1_NoInfo" 1 "OnOffDetd1_OffDetd" 2 "OnOffDetd1_NotOnOrOffDetd" 3 "OnOffDetd1_OnDetd";
VAL_ 444 SteerErrReq 0 "SteerErrReq3_NoReq" 1 "SteerErrReq3_SteerAssiSrvRqrd" 2 "SteerErrReq3_SteerErrStopSfty" 3 "SteerErrReq3_SteerAssiUrgentSrvRqrd" 4 "SteerErrReq3_SteerAssiTmpRedn" 5 "SteerErrReq3_Spare01" 6 "SteerErrReq3_Spare02" 7 "SteerErrReq3_Spare03";
VAL_ 444 SteerExtFctStsDrvrSteerOvrd 0 "Boolean_FALSE" 1 "Boolean_TRUE";
VAL_ 444 SteerExtFctStsExtFctLowerLimActive 0 "Boolean_FALSE" 1 "Boolean_TRUE";
VAL_ 444 SteerExtFctStsExtFctRateLimActive 0 "Boolean_FALSE" 1 "Boolean_TRUE";
VAL_ 444 SteerExtFctStsExtFctUpperLimActive 0 "Boolean_FALSE" 1 "Boolean_TRUE";
VAL_ 444 SteerExtFctStsExtSafeLimActive 0 "Boolean_FALSE" 1 "Boolean_TRUE";
VAL_ 444 SteerExtFctStsLatAgReqNotInRange 0 "Boolean_FALSE" 1 "Boolean_TRUE";
VAL_ 444 SteerExtFctStsLatCtrlReqNotInRange 0 "Boolean_FALSE" 1 "Boolean_TRUE";
VAL_ 444 SteerStsToParkAssi 0 "SteerStsToParkAssi_NormOper" 1 "SteerStsToParkAssi_SteerAbortBySpdHi" 2 "SteerStsToParkAssi_CtrlDifHi" 3 "SteerStsToParkAssi_SteerCtrlIntErr" 4 "SteerStsToParkAssi_SteerAbortByDrvrIntv" 5 "SteerStsToParkAssi_SteerTqHi" 6 "SteerStsToParkAssi_Spare1" 7 "SteerStsToParkAssi_Spare2";
VAL_ 78 PinionSteerAgGroupPinionSteerAg1Qf 0 "GenQf1_UndefindDataAccur" 1 "GenQf1_TmpUndefdData" 2 "GenQf1_DataAccurNotWithinSpcn" 3 "GenQf1_AccurData";
VAL_ 78 PinionSteerAgGroupPinionSteerAgSpd1Qf 0 "GenQf1_UndefindDataAccur" 1 "GenQf1_TmpUndefdData" 2 "GenQf1_DataAccurNotWithinSpcn" 3 "GenQf1_AccurData";
VAL_ 78 PinionSteerAgGroupSteerWhlTqQf 0 "GenQf1_UndefindDataAccur" 1 "GenQf1_TmpUndefdData" 2 "GenQf1_DataAccurNotWithinSpcn" 3 "GenQf1_AccurData";
VAL_ 64 SteerWhlSnsrQf 0 "GenQf1_UndefindDataAccur" 1 "GenQf1_TmpUndefdData" 2 "GenQf1_DataAccurNotWithinSpcn" 3 "GenQf1_AccurData";
VAL_ 128 TrsmActrPosn2TrsmActrPosn 0 "TrsmActrPosn1_Park" 1 "TrsmActrPosn1_ParkRvs" 2 "TrsmActrPosn1_Rvs" 3 "TrsmActrPosn1_RvsNeut" 4 "TrsmActrPosn1_Neut" 5 "TrsmActrPosn1_NeutDrv" 6 "TrsmActrPosn1_Drv" 7 "TrsmActrPosn1_Undefd";
VAL_ 128 TrsmGearActSafeTrsmGearActSafe 0 "PtGearAct1_Neut" 1 "PtGearAct1_Gear1" 2 "PtGearAct1_Gear2" 3 "PtGearAct1_Gear3" 4 "PtGearAct1_Gear4" 5 "PtGearAct1_Gear5" 6 "PtGearAct1_Gear6" 7 "PtGearAct1_Gear7" 8 "PtGearAct1_Gear8" 9 "PtGearAct1_Gear9" 10 "PtGearAct1_Gear10" 11 "PtGearAct1_Gear11" 12 "PtGearAct1_Gear12" 13 "PtGearAct1_Drv" 14 "PtGearAct1_Ukwn" 15 "PtGearAct1_Rvs";
VAL_ 512 TrsmClrRdyReq 0 "OnOff1_Off" 1 "OnOff1_On";
VAL_ 261 TrsmGearChgProgs 0 "TrsmGearChgProgs1_GearShiftChgNotActv" 1 "TrsmGearChgProgs1_StrtPha" 2 "TrsmGearChgProgs1_TqPha" 3 "TrsmGearChgProgs1_JPha" 4 "TrsmGearChgProgs1_EndPha";
VAL_ 261 TrsmToPrpsnNReqRecTrsmNReqCtrl 0 "OnOff1_Off" 1 "OnOff1_On";
VAL_ 629 TrsmEngmtLimdTrsmEngmtLimd 0 "YesNo1_Yes" 1 "YesNo1_No";
VAL_ 629 TrsmErrIndcnReq 0 "OnOff1_Off" 1 "OnOff1_On";
VAL_ 629 TrsmHotSt 0 "TrsmHotSt1_HotStNotActv" 1 "TrsmHotSt1_LvlHotSt1" 2 "TrsmHotSt1_LvlHotSt2";
VAL_ 629 TrsmReqForPfmncRedn 0 "Boolean_FALSE" 1 "Boolean_TRUE";
SIG_GROUP_ 544 AccrPedlRat 1 : AccrPedlRatAccrPedlRat AccrPedlRatChks AccrPedlRatCntr;
SIG_GROUP_ 455 AccrpedlSts 1 : AccrpedlStsChks AccrpedlStsCntr AccrpedlStsFltSts;
SIG_GROUP_ 185 ALgtStdFromWhlSpd 1 : ALgtStdFromWhlSpdALgtStdFromWhlSpd ALgtStdFromWhlSpdChks ALgtStdFromWhlSpdCntr ALgtStdFromWhlSpdQf;
SIG_GROUP_ 147 AsyADL3FuncCtrlSts 1 : AsyADL3FuncCtrlStsADMod AsyADL3FuncCtrlStsChks AsyADL3FuncCtrlStsCntr AsyADL3FuncCtrlStsCtrlSts AsyADL3FuncCtrlStsDegraded AsyADL3FuncCtrlStsQf AsyADL3FuncCtrlStsSts;
SIG_GROUP_ 147 AsyADModeReq 1 : AsyADModeReqADActiveReq AsyADModeReqADDeactiveReq AsyADModeReqChks AsyADModeReqCntr;
SIG_GROUP_ 51 AsyPinionAgReqSafe 1 : AsyPinionAgReqSafeAsyPinionAgReq AsyPinionAgReqSafeAsyPinionAgReqChks AsyPinionAgReqSafeAsyPinionAgReqCntr;
SIG_GROUP_ 129 BrkFAct 1 : BrkFActAutParkBrkSpprtReq BrkFActChks BrkFActCntr BrkFActForce;
SIG_GROUP_ 308 BrkWssInfoFrnt 1 : BrkWssInfoFrntChks BrkWssInfoFrntCntr BrkWssInfoFrntTTCFactorFL BrkWssInfoFrntTTCFactorFR BrkWssInfoFrntWssCoreMonRob;
SIG_GROUP_ 327 BrkWssInfoRe 1 : BrkWssInfoReChks BrkWssInfoReCntr BrkWssInfoReTTCFactorRL BrkWssInfoReTTCFactorRR;
SIG_GROUP_ 587 CchForPwrEco 1 : CchForPwrEcoBarForPwrEco CchForPwrEcoGrdForPwrEco;
SIG_GROUP_ 83 DHTStSafe 1 : DHTStSafeChks DHTStSafeCntr DHTStSafeRsv DHTStSafeSpd DHTStSafeSpdQf DHTStSafeTqRt DHTStSafeTqRtQf;
SIG_GROUP_ 859 DispElecPwr 1 : DispElecPwrAbs DispElecPwrSts;
SIG_GROUP_ 246 DrvrSteerActv 1 : DrvrSteerActvChks DrvrSteerActvCntr DrvrSteerActvDrvrSteerActv;
SIG_GROUP_ 444 DrvrSteerWhlHldGroup 1 : DrvrSteerWhlHldGroupDrvrSteerWhlHld DrvrSteerWhlHldGroupDrvrSteerWhlHldQly;
SIG_GROUP_ 1039 EldtPmpCmd 1 : EldtPmpCmdCooltPmpPostRunReq EldtPmpCmdCooltPmpSpdReq;
SIG_GROUP_ 1039 EngCooltPmpSpdReq 1 : EngCooltPmpSpdReqCooltPmpPostRunReq EngCooltPmpSpdReqCooltPmpSpdReq;
SIG_GROUP_ 304 EngNSafe 1 : EngNSafeEngN EngNSafeEngNChks EngNSafeEngNCntr EngNSafeEngNGrdt;
SIG_GROUP_ 131 EngSt1WdSts 1 : EngSt1WdStsChks EngSt1WdStsCntr EngSt1WdStsEngSt1WdSts;
SIG_GROUP_ 1135 EngTRef 1 : EngTRefSts EngTRefT1 EngTRefT2;
SIG_GROUP_ 265 EpbAvlPrim 1 : EpbAvlPrimApplyFunctionalitiesAvailable EpbAvlPrimChks EpbAvlPrimCntr EpbAvlPrimDriveAwayIntention EpbAvlPrimHostAvailabilityFull EpbAvlPrimHostAvailabilityRelOnly EpbAvlPrimPrimarySystemAvailable EpbAvlPrimReserved1 EpbAvlPrimReserved2 EpbAvlPrimReserved3 EpbAvlPrimReserved4 EpbAvlPrimRollerTestBench;
SIG_GROUP_ 327 EpbSts 1 : EpbStsChks EpbStsCntr EpbStsEpbSts;
SIG_GROUP_ 979 GrlShttrDmd 1 : GrlShttrDmdShttrCalEna GrlShttrDmdShttrPosnReq;
SIG_GROUP_ 871 HvBattPmpCmd 1 : HvBattPmpCmdCooltPmpPostRunReq HvBattPmpCmdCooltPmpSpdReq;
SIG_GROUP_ 730 HvBattPmpStat 1 : HvBattPmpStatCooltPmpDryErr HvBattPmpStatCooltPmpEmgyModSts HvBattPmpStatCooltPmpErrSts HvBattPmpStatCooltPmpI HvBattPmpStatCooltPmpIErr HvBattPmpStatCooltPmpMonrSpd HvBattPmpStatCooltPmpPostRunSts HvBattPmpStatCooltPmpSetPostRunReq HvBattPmpStatCooltPmpSetSpdReq HvBattPmpStatCooltPmpSpd HvBattPmpStatCooltPmpT HvBattPmpStatCooltPmpTErr HvBattPmpStatCooltPmpU HvBattPmpStatCooltPmpUErr HvBattPmpStatCooltPmpUnstallSts;
SIG_GROUP_ 70 LatCtrlModCfmd 1 : LatCtrlModCfmdChks LatCtrlModCfmdCntr LatCtrlModCfmdLatCtrlMod;
SIG_GROUP_ 135 Mot1ReqSafe 1 : Mot1ReqSafeChks Mot1ReqSafeCntr Mot1ReqSafemod Mot1ReqSafeRsv Mot1ReqSafespd Mot1ReqSafetq;
SIG_GROUP_ 121 Mot3ReqSafe 1 : Mot3ReqSafeChks Mot3ReqSafeCntr Mot3ReqSafemod Mot3ReqSafeRsv Mot3ReqSafespd Mot3ReqSafetq;
SIG_GROUP_ 78 PinionSteerAgGroup 1 : PinionSteerAgGroupChks PinionSteerAgGroupCntr PinionSteerAgGroupPinionSteerAg1 PinionSteerAgGroupPinionSteerAg1Qf PinionSteerAgGroupPinionSteerAgSpd1 PinionSteerAgGroupPinionSteerAgSpd1Qf PinionSteerAgGroupSteerWhlTq PinionSteerAgGroupSteerWhlTqQf;
SIG_GROUP_ 265 PrimBrkSysSt 1 : PrimBrkSysStBrkSysSt PrimBrkSysStChks PrimBrkSysStCntr;
SIG_GROUP_ 149 PrkgGearReqGroup 1 : PrkgGearReqGroupChks PrkgGearReqGroupCntr PrkgGearReqGroupReqSts1;
SIG_GROUP_ 235 PrkgPinionAgReqGroup 1 : PrkgPinionAgReqGroupParkAssiPinionAgReq PrkgPinionAgReqGroupParkAssiPinionAgReqChks PrkgPinionAgReqGroupParkAssiPinionAgReqCntr PrkgPinionAgReqGroupQF;
SIG_GROUP_ 1431 PSCMdevelpsignalgroupreq1 1 : PSCMdevelpsignalgroupreq1Functiondevpsignalgroup1 PSCMdevelpsignalgroupreq1Functiondevpsignalgroup2 PSCMdevelpsignalgroupreq1Functiondevpsignalgroup3 PSCMdevelpsignalgroupreq1Functiondevpsignalgroup4 PSCMdevelpsignalgroupreq1Functiondevpsignalgroup5 PSCMdevelpsignalgroupreq1Functiondevpsignalgroup6 PSCMdevelpsignalgroupreq1Functiondevpsignalgroup7 PSCMdevelpsignalgroupreq1Functiondevpsignalgroup8;
SIG_GROUP_ 1430 PSCMdevelpsignalgroupresp1 1 : PSCMdevelpsignalgroupresp1Functiondevpsignalgroup1 PSCMdevelpsignalgroupresp1Functiondevpsignalgroup2 PSCMdevelpsignalgroupresp1Functiondevpsignalgroup3 PSCMdevelpsignalgroupresp1Functiondevpsignalgroup4 PSCMdevelpsignalgroupresp1Functiondevpsignalgroup5 PSCMdevelpsignalgroupresp1Functiondevpsignalgroup6 PSCMdevelpsignalgroupresp1Functiondevpsignalgroup7 PSCMdevelpsignalgroupresp1Functiondevpsignalgroup8;
SIG_GROUP_ 80 PtCluTq2 1 : PtCluTq2PtCluTq PtCluTq2PtCluTqQly;
SIG_GROUP_ 1111 PtTqAtWhlFrntAct 1 : PtTqAtWhlFrntActChks PtTqAtWhlFrntActCntr PtTqAtWhlFrntActPtTqAtAxleFrntAct PtTqAtWhlFrntActPtTqAtWhlFrntLeAct PtTqAtWhlFrntActPtTqAtWhlFrntRiAct PtTqAtWhlFrntActPtTqAtWhlsFrntQly;
SIG_GROUP_ 708 PtVehSpdMax 1 : PtVehSpdMaxChks PtVehSpdMaxCntr PtVehSpdMaxReq;
SIG_GROUP_ 1504 RBCMdevelpsignalgroupreq1 1 : RBCMdevelpsignalgroupreq1Functiondevpsignalgroup1 RBCMdevelpsignalgroupreq1Functiondevpsignalgroup2 RBCMdevelpsignalgroupreq1Functiondevpsignalgroup3 RBCMdevelpsignalgroupreq1Functiondevpsignalgroup4 RBCMdevelpsignalgroupreq1Functiondevpsignalgroup5 RBCMdevelpsignalgroupreq1Functiondevpsignalgroup6 RBCMdevelpsignalgroupreq1Functiondevpsignalgroup7 RBCMdevelpsignalgroupreq1Functiondevpsignalgroup8;
SIG_GROUP_ 129 RbuCtrlModReqSafe 1 : RbuCtrlModReqSafeBrkSysModCfmd RbuCtrlModReqSafeChks RbuCtrlModReqSafeCntr;
SIG_GROUP_ 444 SteerExtFctSts 1 : SteerExtFctStsChks SteerExtFctStsCntr SteerExtFctStsDrvrSteerOvrd SteerExtFctStsExtFctLowerLimActive SteerExtFctStsExtFctRateLimActive SteerExtFctStsExtFctUpperLimActive SteerExtFctStsExtSafeLimActive SteerExtFctStsLatAgReqNotInRange SteerExtFctStsLatCtrlReqNotInRange;
SIG_GROUP_ 64 SteerWhlSnsr 1 : SteerWhlSnsrAg SteerWhlSnsrAgSpd SteerWhlSnsrChks SteerWhlSnsrCntr SteerWhlSnsrQf;
SIG_GROUP_ 128 TrsmActrPosn2 1 : TrsmActrPosn2TrsmActrPosn TrsmActrPosn2TrsmActrPosnChks TrsmActrPosn2TrsmActrPosnCntr;
SIG_GROUP_ 262 TrsmClu0Sts 1 : TrsmClu0StsChks TrsmClu0StsCntr TrsmClu0StsTrsm0CluSts;
SIG_GROUP_ 629 TrsmEngmtLimd 1 : TrsmEngmtLimdChks TrsmEngmtLimdCntr TrsmEngmtLimdTrsmEngmtLimd;
SIG_GROUP_ 128 TrsmGearActSafe 1 : TrsmGearActSafeChks TrsmGearActSafeCntr TrsmGearActSafeTrsmGearActSafe;
SIG_GROUP_ 136 TrsmOutpN 1 : TrsmOutpNChks TrsmOutpNCntr TrsmOutpNDir TrsmOutpNSpd TrsmOutpNSpdQf;
SIG_GROUP_ 261 TrsmToPrpsnNReqRec 1 : TrsmToPrpsnNReqRecTrsmNReqCtrl TrsmToPrpsnNReqRecTrsmNReqMax TrsmToPrpsnNReqRecTrsmNReqMin;
SIG_GROUP_ 629 TrsmTqLoss 1 : TrsmTqLossChks TrsmTqLossCntr TrsmTqLossTrsmTqEff TrsmTqLossTrsmTqLoss;
SIG_GROUP_ 1432 VDDMdevelpsignalgroupreq1 1 : VDDMdevelpsignalgroupreq1Functiondevpsignalgroup1 VDDMdevelpsignalgroupreq1Functiondevpsignalgroup2 VDDMdevelpsignalgroupreq1Functiondevpsignalgroup3 VDDMdevelpsignalgroupreq1Functiondevpsignalgroup4 VDDMdevelpsignalgroupreq1Functiondevpsignalgroup5 VDDMdevelpsignalgroupreq1Functiondevpsignalgroup6 VDDMdevelpsignalgroupreq1Functiondevpsignalgroup7 VDDMdevelpsignalgroupreq1Functiondevpsignalgroup8;
SIG_GROUP_ 1433 VDDMdevelpsignalgroupreq2 1 : VDDMdevelpsignalgroupreq2Functiondevpsignalgroup1 VDDMdevelpsignalgroupreq2Functiondevpsignalgroup2 VDDMdevelpsignalgroupreq2Functiondevpsignalgroup3 VDDMdevelpsignalgroupreq2Functiondevpsignalgroup4 VDDMdevelpsignalgroupreq2Functiondevpsignalgroup5 VDDMdevelpsignalgroupreq2Functiondevpsignalgroup6 VDDMdevelpsignalgroupreq2Functiondevpsignalgroup7 VDDMdevelpsignalgroupreq2Functiondevpsignalgroup8;
